VERSION ""

NS_ :

BS_:

BU_: IHU

BO_ 1538 NMm_IHU_RxMessage: 8 Vector__XXX
 SG_ NM_User_RxSignal_01 : 0|8@1- (1,0) [0|0] ""  IHU

BO_ 2015 DIAG_OBD_REQ_Broadcast: 8 Vector__XXX
 SG_ DIAG_OBD_REQ_Broadcast : 7|64@0+ (1,0) [0|0] ""  IHU

BO_ 1866 Diag_IHU_REQ: 8 Vector__XXX
 SG_ Diag_IHU_REQ : 7|64@0+ (1,0) [0|0] ""  IHU

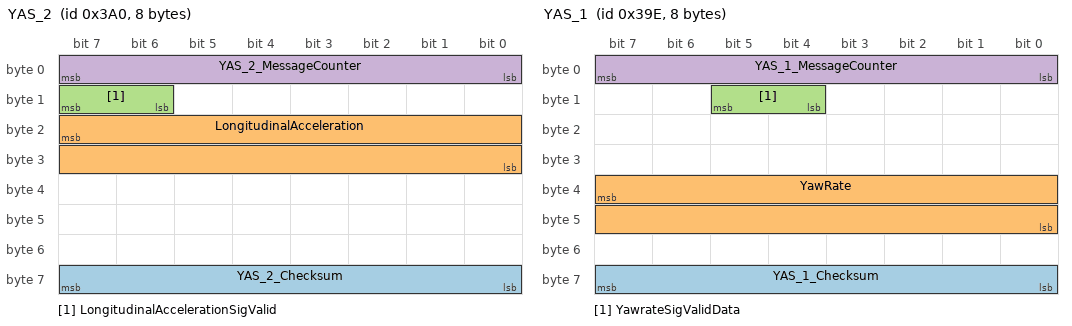
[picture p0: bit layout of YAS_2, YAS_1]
BO_ 928 YAS_2: 8 Vector__XXX
 SG_ YAS_2_Checksum : 63|8@0+ (1,0) [0|255] ""  IHU
 SG_ LongitudinalAcceleration : 23|16@0+ (0.001,-2) [-2|2] "g"  IHU
 SG_ LongitudinalAccelerationSigValid : 15|2@0+ (1,0) [0|3] ""  IHU
 SG_ YAS_2_MessageCounter : 7|8@0+ (1,0) [0|255] ""  IHU

BO_ 926 YAS_1: 8 Vector__XXX
 SG_ YAS_1_Checksum : 63|8@0+ (1,0) [0|255] ""  IHU
 SG_ YawRate : 39|16@0+ (0.01,-180) [-180|180] "deg/sec"  IHU
 SG_ YawrateSigValidData : 13|2@0+ (1,0) [0|3] ""  IHU
 SG_ YAS_1_MessageCounter : 7|8@0+ (1,0) [0|255] ""  IHU

BO_ 769 TCU_G: 4 Vector__XXX
 SG_ GBPositoionDisplay : 14|5@0+ (1,0) [0|31] ""  IHU

BO_ 1206 SHU2R_1: 8 Vector__XXX
 SG_ SHU2R_RSeatVentnSts : 5|3@0+ (1,0) [0|7] ""  IHU
 SG_ SHU2R_RSeatHeatSts : 2|3@0+ (1,0) [0|7] ""  IHU

BO_ 1202 SHU2M_1: 8 Vector__XXX
 SG_ SHU2M_MSeatVentnSts : 5|3@0+ (1,0) [0|7] ""  IHU
 SG_ SHU2M_MSeatHeatSts : 2|3@0+ (1,0) [0|7] ""  IHU

BO_ 1194 SHU2L_1: 8 Vector__XXX
 SG_ SHU2L_LSeatVentnSts : 5|3@0+ (1,0) [0|7] ""  IHU
 SG_ SHU2L_LSeatHeatSts : 2|3@0+ (1,0) [0|7] ""  IHU

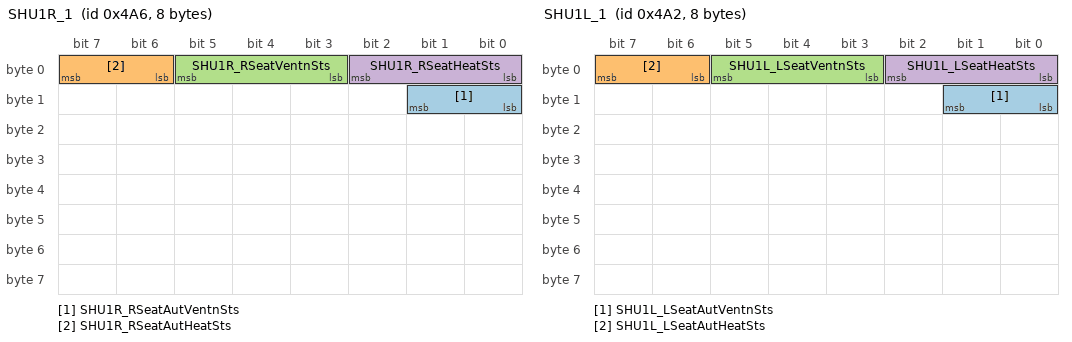
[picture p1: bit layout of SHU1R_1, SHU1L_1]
BO_ 1190 SHU1R_1: 8 Vector__XXX
 SG_ SHU1R_RSeatAutVentnSts : 9|2@0+ (1,0) [0|3] ""  IHU
 SG_ SHU1R_RSeatAutHeatSts : 7|2@0+ (1,0) [0|3] ""  IHU
 SG_ SHU1R_RSeatVentnSts : 5|3@0+ (1,0) [0|7] ""  IHU
 SG_ SHU1R_RSeatHeatSts : 2|3@0+ (1,0) [0|7] ""  IHU

BO_ 1186 SHU1L_1: 8 Vector__XXX
 SG_ SHU1L_LSeatAutVentnSts : 9|2@0+ (1,0) [0|3] ""  IHU
 SG_ SHU1L_LSeatAutHeatSts : 7|2@0+ (1,0) [0|3] ""  IHU
 SG_ SHU1L_LSeatVentnSts : 5|3@0+ (1,0) [0|7] ""  IHU
 SG_ SHU1L_LSeatHeatSts : 2|3@0+ (1,0) [0|7] ""  IHU

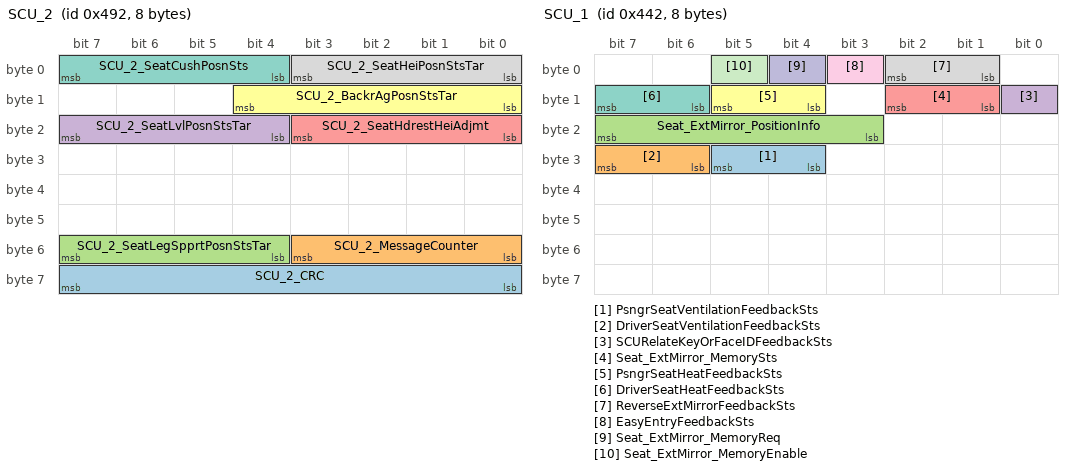
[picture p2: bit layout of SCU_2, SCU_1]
BO_ 1170 SCU_2: 8 Vector__XXX
 SG_ SCU_2_CRC : 63|8@0+ (1,0) [0|255] ""  IHU
 SG_ SCU_2_MessageCounter : 51|4@0+ (1,0) [0|15] ""  IHU
 SG_ SCU_2_SeatLegSpprtPosnStsTar : 55|4@0+ (10,0) [0|100] "%"  IHU
 SG_ SCU_2_SeatLvlPosnStsTar : 23|4@0+ (10,0) [0|100] "%"  IHU
 SG_ SCU_2_SeatHdrestHeiAdjmt : 19|4@0+ (10,0) [0|100] "%"  IHU
 SG_ SCU_2_BackrAgPosnStsTar : 12|5@0+ (5,0) [0|100] "%"  IHU
 SG_ SCU_2_SeatCushPosnSts : 7|4@0+ (10,0) [0|100] "%"  IHU
 SG_ SCU_2_SeatHeiPosnStsTar : 3|4@0+ (10,0) [0|100] "%"  IHU

BO_ 1090 SCU_1: 8 Vector__XXX
 SG_ PsngrSeatVentilationFeedbackSts : 29|2@0+ (1,0) [0|3] ""  IHU
 SG_ DriverSeatVentilationFeedbackSts : 31|2@0+ (1,0) [0|3] ""  IHU
 SG_ Seat_ExtMirror_PositionInfo : 23|5@0+ (1,0) [0|31] ""  IHU
 SG_ SCURelateKeyOrFaceIDFeedbackSts : 8|1@0+ (1,0) [0|1] ""  IHU
 SG_ Seat_ExtMirror_MemorySts : 10|2@0+ (1,0) [0|3] ""  IHU
 SG_ PsngrSeatHeatFeedbackSts : 13|2@0+ (1,0) [0|3] ""  IHU
 SG_ DriverSeatHeatFeedbackSts : 15|2@0+ (1,0) [0|3] ""  IHU
 SG_ ReverseExtMirrorFeedbackSts : 2|2@0+ (1,0) [0|3] ""  IHU
 SG_ EasyEntryFeedbackSts : 3|1@0+ (1,0) [0|1] ""  IHU
 SG_ Seat_ExtMirror_MemoryReq : 4|1@0+ (1,0) [0|1] ""  IHU
 SG_ Seat_ExtMirror_MemoryEnable : 5|1@0+ (1,0) [0|1] ""  IHU

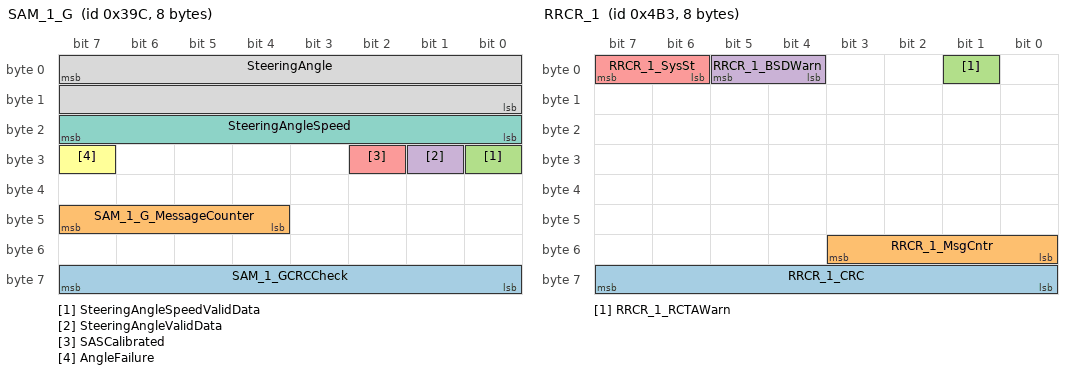
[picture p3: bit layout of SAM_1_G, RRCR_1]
BO_ 924 SAM_1_G: 8 Vector__XXX
 SG_ SAM_1_GCRCCheck : 63|8@0+ (1,0) [0|255] ""  IHU
 SG_ SAM_1_G_MessageCounter : 47|4@0+ (1,0) [0|15] ""  IHU
 SG_ SteeringAngleSpeedValidData : 24|1@0+ (1,0) [0|1] ""  IHU
 SG_ SteeringAngleValidData : 25|1@0+ (1,0) [0|1] ""  IHU
 SG_ SASCalibrated : 26|1@0+ (1,0) [0|1] ""  IHU
 SG_ AngleFailure : 31|1@0+ (1,0) [0|1] ""  IHU
 SG_ SteeringAngleSpeed : 23|8@0+ (4,0) [0|1016] "deg/Sec"  IHU
 SG_ SteeringAngle : 7|16@0+ (0.0625,-2048) [-2048|2047.875] "deg"  IHU

BO_ 1203 RRCR_1: 8 Vector__XXX
 SG_ RRCR_1_CRC : 63|8@0+ (1,0) [0|255] ""  IHU
 SG_ RRCR_1_MsgCntr : 51|4@0+ (1,0) [0|15] ""  IHU
 SG_ RRCR_1_RCTAWarn : 1|1@0+ (1,0) [0|1] ""  IHU
 SG_ RRCR_1_BSDWarn : 5|2@0+ (1,0) [0|3] ""  IHU
 SG_ RRCR_1_SysSt : 7|2@0+ (1,0) [0|3] ""  IHU

BO_ 498 RLCR_2: 8 Vector__XXX
 SG_ RLCR_2_RCTBONOFFSts : 5|2@0+ (1,0) [0|3] ""  IHU
 SG_ RLCR_2_RAEBONOFFSts : 3|2@0+ (1,0) [0|3] ""  IHU

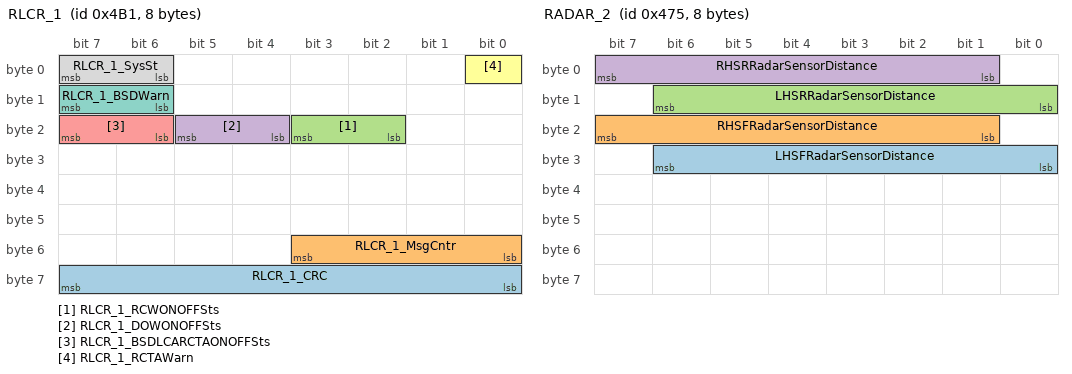
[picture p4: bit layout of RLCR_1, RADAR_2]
BO_ 1201 RLCR_1: 8 Vector__XXX
 SG_ RLCR_1_CRC : 63|8@0+ (1,0) [0|255] ""  IHU
 SG_ RLCR_1_MsgCntr : 51|4@0+ (1,0) [0|15] ""  IHU
 SG_ RLCR_1_RCWONOFFSts : 19|2@0+ (1,0) [0|3] ""  IHU
 SG_ RLCR_1_DOWONOFFSts : 21|2@0+ (1,0) [0|3] ""  IHU
 SG_ RLCR_1_BSDLCARCTAONOFFSts : 23|2@0+ (1,0) [0|3] ""  IHU
 SG_ RLCR_1_RCTAWarn : 0|1@0+ (1,0) [0|1] ""  IHU
 SG_ RLCR_1_BSDWarn : 15|2@0+ (1,0) [0|3] ""  IHU
 SG_ RLCR_1_SysSt : 7|2@0+ (1,0) [0|3] ""  IHU

BO_ 1141 RADAR_2: 8 Vector__XXX
 SG_ LHSFRadarSensorDistance : 30|7@0+ (5,30) [30|500] "cm"  IHU
 SG_ RHSFRadarSensorDistance : 23|7@0+ (5,30) [30|500] "cm"  IHU
 SG_ LHSRRadarSensorDistance : 14|7@0+ (5,30) [30|500] "cm"  IHU
 SG_ RHSRRadarSensorDistance : 7|7@0+ (5,30) [30|500] "cm"  IHU

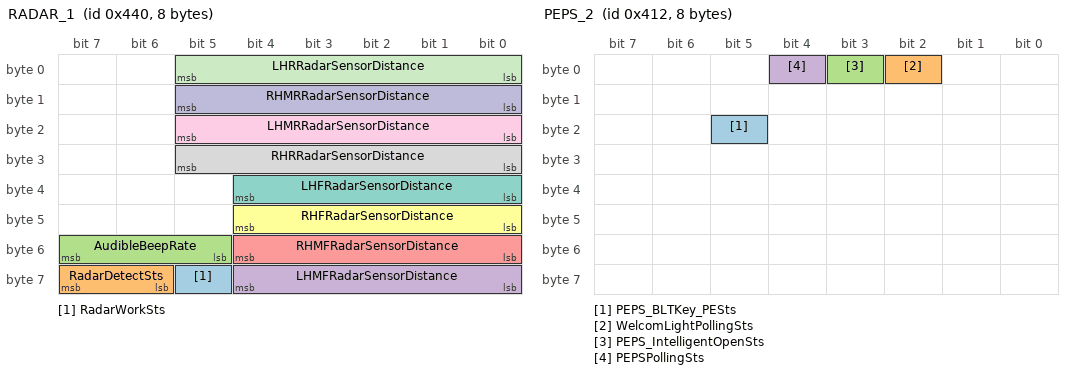
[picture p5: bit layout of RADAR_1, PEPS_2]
BO_ 1088 RADAR_1: 8 Vector__XXX
 SG_ RadarWorkSts : 61|1@0+ (1,0) [0|1] ""  IHU
 SG_ RadarDetectSts : 63|2@0+ (1,0) [0|3] ""  IHU
 SG_ AudibleBeepRate : 55|3@0+ (1,0) [0|7] ""  IHU
 SG_ LHMFRadarSensorDistance : 60|5@0+ (5,25) [25|160] "cm"  IHU
 SG_ RHMFRadarSensorDistance : 52|5@0+ (5,25) [25|160] "cm"  IHU
 SG_ RHFRadarSensorDistance : 44|5@0+ (5,25) [25|160] "cm"  IHU
 SG_ LHFRadarSensorDistance : 36|5@0+ (5,25) [25|160] "cm"  IHU
 SG_ RHRRadarSensorDistance : 29|6@0+ (5,25) [25|180] "cm"  IHU
 SG_ LHMRRadarSensorDistance : 21|6@0+ (5,25) [25|180] "cm"  IHU
 SG_ RHMRRadarSensorDistance : 13|6@0+ (5,25) [25|180] "cm"  IHU
 SG_ LHRRadarSensorDistance : 5|6@0+ (5,25) [25|180] "cm"  IHU

BO_ 1078 PLG_1: 8 Vector__XXX
 SG_ PLG_OperateSts : 21|3@0+ (1,0) [0|7] ""  IHU
 SG_ PLG_Set_MaxPosition : 15|8@0+ (1,0) [0|100] "%"  IHU

BO_ 1042 PEPS_2: 8 Vector__XXX
 SG_ PEPS_BLTKey_PESts : 21|1@0+ (1,0) [0|1] ""  IHU
 SG_ WelcomLightPollingSts : 2|1@0+ (1,0) [0|1] ""  IHU
 SG_ PEPS_IntelligentOpenSts : 3|1@0+ (1,0) [0|1] ""  IHU
 SG_ PEPSPollingSts : 4|1@0+ (1,0) [0|1] ""  IHU

BO_ 998 PEPS_1: 8 Vector__XXX
 SG_ RemoteStartSts : 42|2@0+ (1,0) [0|3] ""  IHU
 SG_ Start_StopRequest : 45|3@0+ (1,0) [0|7] ""  IHU
 SG_ IDInformation : 34|3@0+ (1,0) [0|7] ""  IHU

BO_ 1124 NFC_1: 8 Vector__XXX
 SG_ NFC_1_DispCardPosn : 15|1@0+ (1,0) [0|1] ""  IHU
 SG_ NFC_1_IDList : 7|3@0+ (1,0) [0|7] ""  IHU
 SG_ NFC_1_ID : 4|3@0+ (1,0) [0|7] ""  IHU

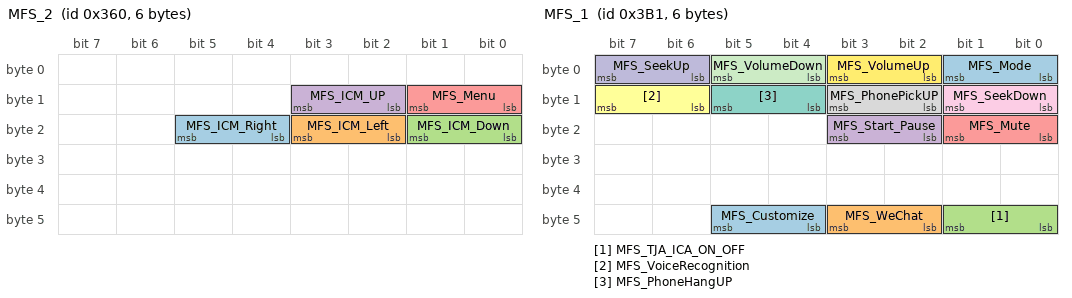
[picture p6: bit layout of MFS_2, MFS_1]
BO_ 864 MFS_2: 6 Vector__XXX
 SG_ MFS_ICM_Right : 21|2@0+ (1,0) [0|3] ""  IHU
 SG_ MFS_ICM_Left : 19|2@0+ (1,0) [0|3] ""  IHU
 SG_ MFS_ICM_Down : 17|2@0+ (1,0) [0|3] ""  IHU
 SG_ MFS_ICM_UP : 11|2@0+ (1,0) [0|3] ""  IHU
 SG_ MFS_Menu : 9|2@0+ (1,0) [0|3] ""  IHU

BO_ 945 MFS_1: 6 Vector__XXX
 SG_ MFS_Customize : 45|2@0+ (1,0) [0|3] ""  IHU
 SG_ MFS_WeChat : 43|2@0+ (1,0) [0|3] ""  IHU
 SG_ MFS_TJA_ICA_ON_OFF : 41|2@0+ (1,0) [0|3] ""  IHU
 SG_ MFS_Start_Pause : 19|2@0+ (1,0) [0|3] ""  IHU
 SG_ MFS_Mute : 17|2@0+ (1,0) [0|3] ""  IHU
 SG_ MFS_VoiceRecognition : 15|2@0+ (1,0) [0|3] ""  IHU
 SG_ MFS_PhoneHangUP : 13|2@0+ (1,0) [0|3] ""  IHU
 SG_ MFS_PhonePickUP : 11|2@0+ (1,0) [0|3] ""  IHU
 SG_ MFS_SeekDown : 9|2@0+ (1,0) [0|3] ""  IHU
 SG_ MFS_SeekUp : 7|2@0+ (1,0) [0|3] ""  IHU
 SG_ MFS_VolumeDown : 5|2@0+ (1,0) [0|3] ""  IHU
 SG_ MFS_VolumeUp : 3|2@0+ (1,0) [0|3] ""  IHU
 SG_ MFS_Mode : 1|2@0+ (1,0) [0|3] ""  IHU

BO_ 1218 LHM_1: 8 Vector__XXX
 SG_ LHM_1_ADBenable_Feedback : 0|1@0+ (1,0) [0|1] ""  IHU
 SG_ LHM_1_ADBSts : 2|2@0+ (1,0) [0|3] ""  IHU

BO_ 1059 LDW_1: 8 Vector__XXX
 SG_ LDWSensitivitySettingFeedback : 6|2@0+ (1,0) [0|3] ""  IHU
 SG_ LDWSwitchStsFeedback : 7|1@0+ (1,0) [0|1] ""  IHU

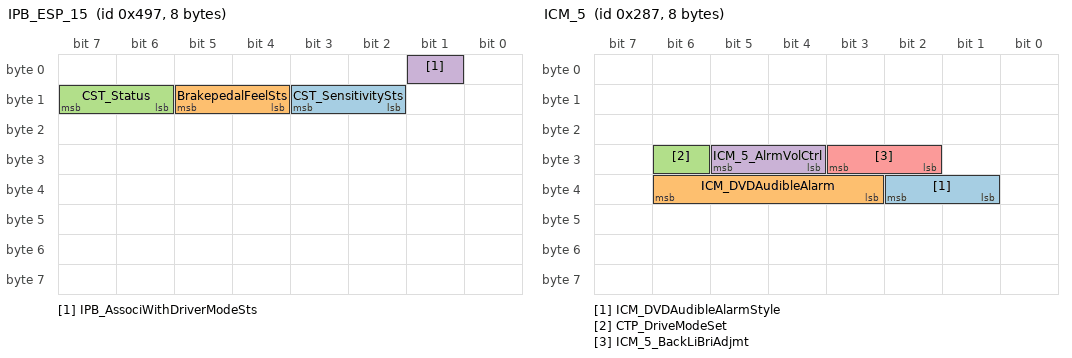
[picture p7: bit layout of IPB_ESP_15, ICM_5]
BO_ 1175 IPB_ESP_15: 8 Vector__XXX
 SG_ CST_SensitivitySts : 11|2@0+ (1,0) [0|3] ""  IHU
 SG_ BrakepedalFeelSts : 13|2@0+ (1,0) [0|3] ""  IHU
 SG_ CST_Status : 15|2@0+ (1,0) [0|3] ""  IHU
 SG_ IPB_AssociWithDriverModeSts : 1|1@0+ (1,0) [0|1] ""  IHU

BO_ 1149 IMMO_12: 8 Vector__XXX
 SG_ IMMO_Teach : 7|64@0+ (1,0) [0|0] ""  IHU

BO_ 1110 IMMO_11: 8 Vector__XXX
 SG_ IMMO_Chall : 7|64@0+ (1,0) [0|0] ""  IHU

BO_ 1508 ICM_IHU_Interaction: 8 Vector__XXX
 SG_ ICM_4_InteractiveDisplayInfo : 7|64@0+ (1,0) [0|0] ""  IHU

BO_ 906 IDCU_12: 8 Vector__XXX
 SG_ IDCU_12CPMod : 15|4@0+ (1,0) [0|15] ""  IHU
 SG_ IDCU_12Rmninfo : 7|7@0+ (1,0) [0|127] ""  IHU

BO_ 1248 IDCU_11: 8 Vector__XXX
 SG_ IDCU_11_DrvAssiStylests : 8|2@0+ (1,0) [0|3] ""  IHU
 SG_ IDCU_11_DCLCONOFFsts : 10|2@0+ (1,0) [0|3] ""  IHU

BO_ 533 ICM_8: 8 Vector__XXX
 SG_ ICM_8_FrntRadarSwt : 15|1@0+ (1,0) [0|1] ""  IHU
 SG_ ICM_ESPSwitchCmd : 0|1@0+ (1,0) [0|1] ""  IHU

BO_ 647 ICM_5: 8 Vector__XXX
 SG_ ICM_DVDAudibleAlarmStyle : 34|2@0+ (1,0) [0|3] ""  IHU
 SG_ ICM_DVDAudibleAlarm : 38|4@0+ (1,0) [0|15] ""  IHU
 SG_ CTP_DriveModeSet : 30|1@0+ (1,0) [0|3] ""  IHU
 SG_ ICM_5_AlrmVolCtrl : 29|2@0+ (1,0) [0|3] ""  IHU
 SG_ ICM_5_BackLiBriAdjmt : 27|2@0+ (1,0) [0|3] ""  IHU

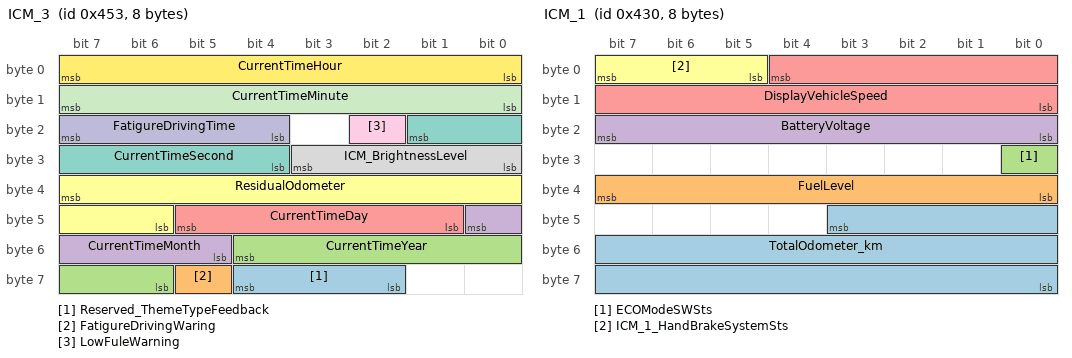
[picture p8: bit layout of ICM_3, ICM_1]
BO_ 1107 ICM_3: 8 Vector__XXX
 SG_ Reserved_ThemeTypeFeedback : 60|3@0+ (1,0) [0|0] ""  IHU
 SG_ FatigureDrivingWaring : 61|1@0+ (1,0) [0|1] ""  IHU
 SG_ CurrentTimeYear : 52|7@0+ (1,2000) [2000|2127] ""  IHU
 SG_ CurrentTimeMonth : 40|4@0+ (1,0) [1|12] ""  IHU
 SG_ CurrentTimeDay : 45|5@0+ (1,0) [1|31] ""  IHU
 SG_ ResidualOdometer : 39|10@0+ (1,0) [0|999] "km"  IHU
 SG_ CurrentTimeSecond : 17|6@0+ (1,0) [0|59] ""  IHU
 SG_ ICM_BrightnessLevel : 27|4@0+ (1,0) [0|15] ""  IHU
 SG_ LowFuleWarning : 18|1@0+ (1,0) [0|1] ""  IHU
 SG_ FatigureDrivingTime : 23|4@0+ (1,0) [0|15] ""  IHU
 SG_ CurrentTimeMinute : 15|8@0+ (1,0) [0|59] ""  IHU
 SG_ CurrentTimeHour : 7|8@0+ (1,0) [0|23] ""  IHU

BO_ 1106 ICM_2: 4 Vector__XXX
 SG_ ICM_2_OverSpeedValue : 31|6@0+ (1,0) [0|63] ""  IHU
 SG_ BackLightLevel : 23|4@0+ (1,0) [0|15] ""  IHU
 SG_ AverageFuelConsumption : 7|8@0+ (0.1,0) [0|25.4] "L/100km"  IHU

BO_ 1072 ICM_1: 8 Vector__XXX
 SG_ TotalOdometer_km : 43|20@0+ (1,0) [0|999999] "km"  IHU
 SG_ FuelLevel : 39|8@0+ (1,0) [0|100] "%"  IHU
 SG_ ECOModeSWSts : 24|1@0+ (1,0) [0|1] ""  IHU
 SG_ BatteryVoltage : 23|8@0+ (0.1,0) [0|25.4] "V"  IHU
 SG_ DisplayVehicleSpeed : 4|13@0+ (0.0625,0) [0|511.875] "km/h"  IHU
 SG_ ICM_1_HandBrakeSystemSts : 7|3@0+ (1,0) [0|7] ""  IHU

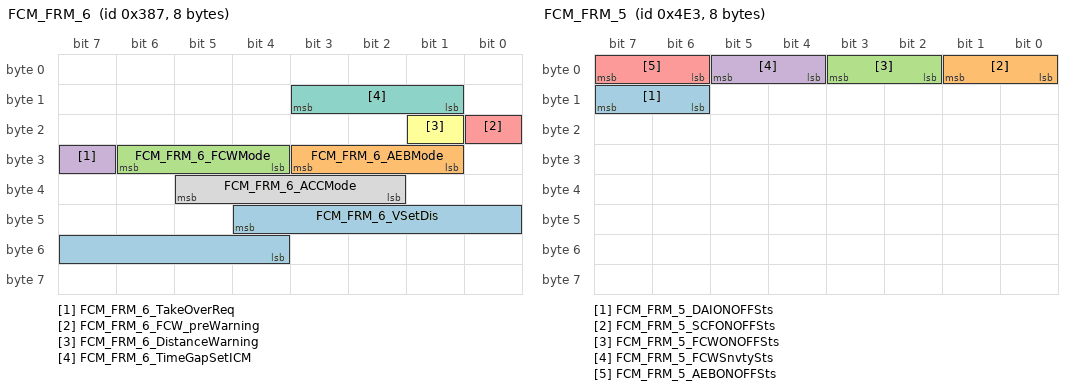
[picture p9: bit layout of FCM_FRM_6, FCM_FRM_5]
BO_ 903 FCM_FRM_6: 8 Vector__XXX
 SG_ FCM_FRM_6_VSetDis : 44|9@0+ (0.5,0) [0|255.5] "KPH"  IHU
 SG_ FCM_FRM_6_AEBMode : 27|3@0+ (1,0) [0|4] ""  IHU
 SG_ FCM_FRM_6_FCWMode : 30|3@0+ (1,0) [0|4] ""  IHU
 SG_ FCM_FRM_6_TakeOverReq : 31|1@0+ (1,0) [0|1] ""  IHU
 SG_ FCM_FRM_6_FCW_preWarning : 16|1@0+ (1,0) [0|1] ""  IHU
 SG_ FCM_FRM_6_DistanceWarning : 17|1@0+ (1,0) [0|1] ""  IHU
 SG_ FCM_FRM_6_TimeGapSetICM : 11|3@0+ (1,0) [0|7] ""  IHU
 SG_ FCM_FRM_6_ACCMode : 37|4@0+ (1,0) [0|15] ""  IHU

BO_ 1251 FCM_FRM_5: 8 Vector__XXX
 SG_ FCM_FRM_5_DAIONOFFSts : 15|2@0+ (1,0) [0|3] ""  IHU
 SG_ FCM_FRM_5_SCFONOFFSts : 1|2@0+ (1,0) [0|3] ""  IHU
 SG_ FCM_FRM_5_FCWONOFFSts : 3|2@0+ (1,0) [0|3] ""  IHU
 SG_ FCM_FRM_5_FCWSnvtySts : 5|2@0+ (1,0) [0|3] ""  IHU
 SG_ FCM_FRM_5_AEBONOFFSts : 7|2@0+ (1,0) [0|3] ""  IHU

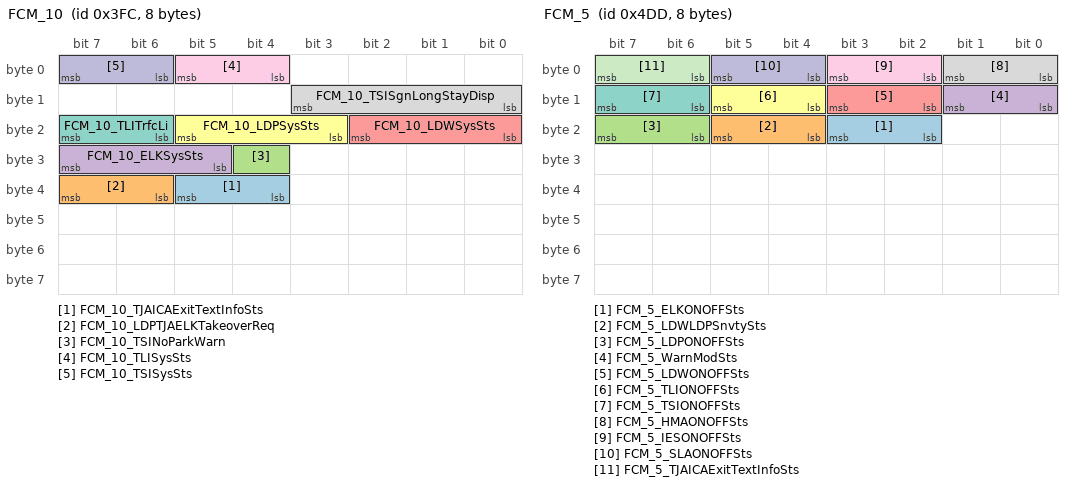
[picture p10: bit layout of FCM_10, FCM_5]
BO_ 1020 FCM_10: 8 Vector__XXX
 SG_ FCM_10_TJAICAExitTextInfoSts : 37|2@0+ (1,0) [0|3] ""  IHU
 SG_ FCM_10_LDPTJAELKTakeoverReq : 39|2@0+ (1,0) [0|3] ""  IHU
 SG_ FCM_10_TSINoParkWarn : 28|1@0+ (1,0) [0|1] ""  IHU
 SG_ FCM_10_ELKSysSts : 31|3@0+ (1,0) [0|7] ""  IHU
 SG_ FCM_10_LDWSysSts : 18|3@0+ (1,0) [0|7] ""  IHU
 SG_ FCM_10_LDPSysSts : 21|3@0+ (1,0) [0|7] ""  IHU
 SG_ FCM_10_TLITrfcLi : 23|2@0+ (1,0) [0|3] ""  IHU
 SG_ FCM_10_TSISgnLongStayDisp : 11|4@0+ (1,0) [0|15] ""  IHU
 SG_ FCM_10_TLISysSts : 5|2@0+ (1,0) [0|3] ""  IHU
 SG_ FCM_10_TSISysSts : 7|2@0+ (1,0) [0|3] ""  IHU

BO_ 1245 FCM_5: 8 Vector__XXX
 SG_ FCM_5_ELKONOFFSts : 19|2@0+ (1,0) [0|3] ""  IHU
 SG_ FCM_5_LDWLDPSnvtySts : 21|2@0+ (1,0) [0|3] ""  IHU
 SG_ FCM_5_LDPONOFFSts : 23|2@0+ (1,0) [0|3] ""  IHU
 SG_ FCM_5_WarnModSts : 9|2@0+ (1,0) [0|3] ""  IHU
 SG_ FCM_5_LDWONOFFSts : 11|2@0+ (1,0) [0|3] ""  IHU
 SG_ FCM_5_TLIONOFFSts : 13|2@0+ (1,0) [0|3] ""  IHU
 SG_ FCM_5_TSIONOFFSts : 15|2@0+ (1,0) [0|3] ""  IHU
 SG_ FCM_5_HMAONOFFSts : 1|2@0+ (1,0) [0|3] ""  IHU
 SG_ FCM_5_IESONOFFSts : 3|2@0+ (1,0) [0|3] ""  IHU
 SG_ FCM_5_SLAONOFFSts : 5|2@0+ (1,0) [0|3] ""  IHU
 SG_ FCM_5_TJAICAExitTextInfoSts : 7|2@0+ (1,0) [0|3] ""  IHU

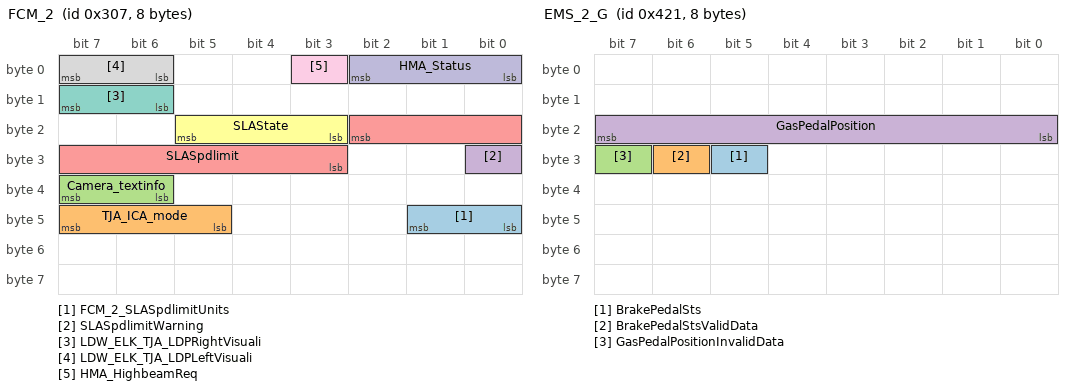
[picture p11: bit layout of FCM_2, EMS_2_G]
BO_ 775 FCM_2: 8 Vector__XXX
 SG_ FCM_2_SLASpdlimitUnits : 41|2@0+ (1,0) [0|3] ""  IHU
 SG_ TJA_ICA_mode : 47|3@0+ (1,0) [0|4] ""  IHU
 SG_ Camera_textinfo : 39|2@0+ (1,0) [0|3] ""  IHU
 SG_ SLASpdlimitWarning : 24|1@0+ (1,0) [0|1] ""  IHU
 SG_ SLASpdlimit : 18|8@0+ (1,0) [0|255] ""  IHU
 SG_ SLAState : 21|3@0+ (1,0) [0|7] ""  IHU
 SG_ LDW_ELK_TJA_LDPRightVisuali : 15|2@0+ (1,0) [0|3] ""  IHU
 SG_ LDW_ELK_TJA_LDPLeftVisuali : 7|2@0+ (1,0) [0|3] ""  IHU
 SG_ HMA_HighbeamReq : 3|1@0+ (1,0) [0|1] ""  IHU
 SG_ HMA_Status : 2|3@0+ (1,0) [0|7] ""  IHU

BO_ 896 EPS_1: 3 Vector__XXX
 SG_ EPS_AssociWithDriverModeSts : 11|1@0+ (1,0) [0|1] ""  IHU
 SG_ EPS_AssistanceStyle_Sts : 6|2@0+ (1,0) [0|3] ""  IHU

BO_ 1240 EMS_3_G: 8 Vector__XXX
 SG_ EMS_BoostP : 39|16@0+ (0.078125,0) [0|5119] "hPa"  IHU

BO_ 1057 EMS_2_G: 8 Vector__XXX
 SG_ BrakePedalSts : 29|1@0+ (1,0) [0|1] ""  IHU
 SG_ BrakePedalStsValidData : 30|1@0+ (1,0) [0|1] ""  IHU
 SG_ GasPedalPositionInvalidData : 31|1@0+ (1,0) [0|1] ""  IHU
 SG_ GasPedalPosition : 23|8@0+ (0.392,0) [0|99.568] "%"  IHU

BO_ 640 EMS_1_G: 8 Vector__XXX
 SG_ EngineSts : 58|1@0+ (1,0) [0|1] ""  IHU
 SG_ SSMStatus : 52|3@0+ (1,0) [0|7] ""  IHU
 SG_ EngineSpeed : 39|11@0+ (4,0) [0|8000] "rpm"  IHU

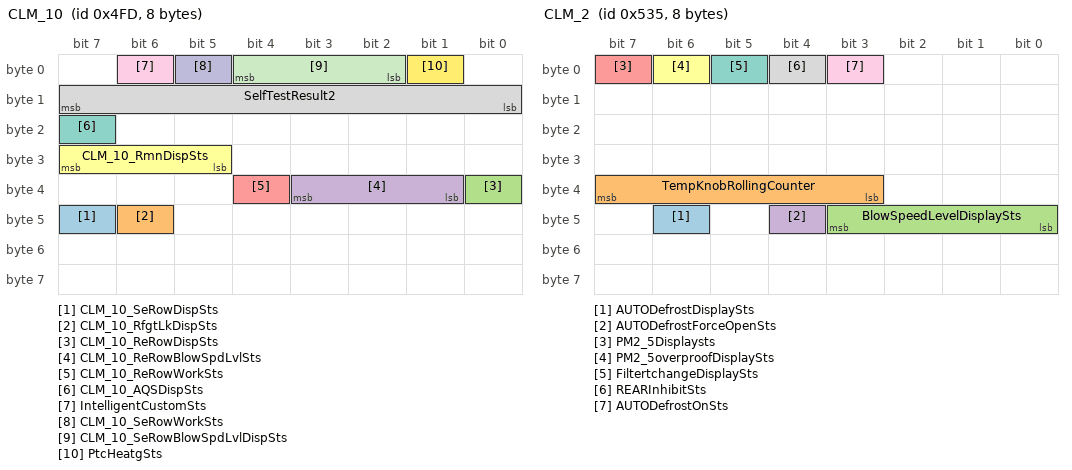
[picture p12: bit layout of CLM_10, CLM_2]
BO_ 1277 CLM_10: 8 Vector__XXX
 SG_ CLM_10_SeRowDispSts : 47|1@0+ (1,0) [0|1] ""  IHU
 SG_ CLM_10_RfgtLkDispSts : 46|1@0+ (1,0) [0|1] ""  IHU
 SG_ CLM_10_ReRowDispSts : 32|1@0+ (1,0) [0|1] ""  IHU
 SG_ CLM_10_ReRowBlowSpdLvlSts : 35|3@0+ (1,0) [0|7] ""  IHU
 SG_ CLM_10_ReRowWorkSts : 36|1@0+ (1,0) [0|1] ""  IHU
 SG_ CLM_10_RmnDispSts : 31|3@0+ (1,0) [0|7] ""  IHU
 SG_ CLM_10_AQSDispSts : 23|1@0+ (1,0) [0|1] ""  IHU
 SG_ SelfTestResult2 : 15|8@0+ (1,0) [0|255] ""  IHU
 SG_ IntelligentCustomSts : 6|1@0+ (1,0) [0|1] ""  IHU
 SG_ CLM_10_SeRowWorkSts : 5|1@0+ (1,0) [0|1] ""  IHU
 SG_ CLM_10_SeRowBlowSpdLvlDispSts : 4|3@0+ (1,0) [0|7] ""  IHU
 SG_ PtcHeatgSts : 1|1@0+ (1,0) [0|1] ""  IHU

BO_ 1334 CLM_3: 8 Vector__XXX
 SG_ FragranCeconsistenceLevelSts : 58|3@0+ (1,0) [0|7] ""  IHU
 SG_ Pos3_FragranceTypesSts : 49|3@0+ (1,0) [0|7] ""  IHU
 SG_ Pos2_FragranceTypesSts : 62|3@0+ (1,0) [0|7] ""  IHU
 SG_ PM2_5AutoRunSetSts : 59|1@0+ (1,0) [0|1] ""  IHU
 SG_ PM2_5_Incar_Level : 52|3@0+ (1,0) [0|7] ""  IHU
 SG_ PM2_5_Outcar_Level : 55|3@0+ (1,0) [0|7] ""  IHU
 SG_ FragranceDisplaysts : 40|1@0+ (1,0) [0|1] ""  IHU
 SG_ FragrancePositionSwt : 24|2@0+ (1,0) [0|3] ""  IHU
 SG_ ACModeCustomSts : 42|2@0+ (1,0) [0|3] ""  IHU
 SG_ FragranceWelcomeModeSts : 44|1@0+ (1,0) [0|1] ""  IHU
 SG_ RefreshFunctionSts : 43|1@0+ (1,0) [0|1] ""  IHU
 SG_ Pos1_FragranceTypesSts : 47|3@0+ (1,0) [0|7] ""  IHU
 SG_ PM2_5AutoRunSts : 33|1@0+ (1,0) [0|1] ""  IHU
 SG_ FragranceSWSts : 36|2@0+ (1,0) [0|3] ""  IHU
 SG_ AutoBltCalllowBlowSpeedSts : 37|1@0+ (1,0) [0|1] ""  IHU
 SG_ AutoParkInnerCirculationSts : 38|1@0+ (1,0) [0|1] ""  IHU
 SG_ PM2_5_IncarSts : 26|1@0+ (1,0) [0|1] ""  IHU
 SG_ PM2_5_ExtSts : 27|1@0+ (1,0) [0|1] ""  IHU
 SG_ PM2_5_ext : 23|10@0+ (1,0) [0|1000] "ug/m3"  IHU
 SG_ FragranceShortageWarning : 6|3@0+ (1,0) [0|7] ""  IHU
 SG_ ION_Function_Sts : 3|2@0+ (1,0) [0|3] ""  IHU
 SG_ PM2_5_incar : 1|10@0+ (1,0) [0|1000] "ug/m3"  IHU

BO_ 1333 CLM_2: 8 Vector__XXX
 SG_ AUTODefrostDisplaySts : 46|1@0+ (1,0) [0|1] ""  IHU
 SG_ TempKnobRollingCounter : 39|5@0+ (1,0) [0|31] ""  IHU
 SG_ BlowSpeedLevelDisplaySts : 43|4@0+ (1,0) [0|15] ""  IHU
 SG_ AUTODefrostForceOpenSts : 44|1@0+ (1,0) [0|1] ""  IHU
 SG_ PM2_5Displaysts : 7|1@0+ (1,0) [0|1] ""  IHU
 SG_ PM2_5overproofDisplaySts : 6|1@0+ (1,0) [0|1] ""  IHU
 SG_ FiltertchangeDisplaySts : 5|1@0+ (1,0) [0|1] ""  IHU
 SG_ REARInhibitSts : 4|1@0+ (1,0) [0|1] ""  IHU
 SG_ AUTODefrostOnSts : 3|1@0+ (1,0) [0|1] ""  IHU

BO_ 1306 CLM_1: 8 Vector__XXX
 SG_ SetTemperature_R_F : 61|5@0+ (2,58) [58|90] "℉"  IHU
 SG_ SetTemperature_L_F : 50|5@0+ (2,58) [58|90] "℉"  IHU
 SG_ SelfTestResult : 55|5@0+ (1,0) [0|31] ""  IHU
 SG_ TemperatureUnit : 40|1@0+ (1,0) [0|1] ""  IHU
 SG_ ZoneSelectionDisplaySts : 41|1@0+ (1,0) [0|1] ""  IHU
 SG_ CirculationModeDisplaySts : 42|1@0+ (1,0) [0|1] ""  IHU
 SG_ SetTemperature_R_C : 47|5@0+ (1,15) [15|31] "℃"  IHU
 SG_ SetTemperature_L_C : 39|5@0+ (1,15) [15|31] "℃"  IHU
 SG_ BlowDelayOffSts : 34|1@0+ (1,0) [0|1] ""  IHU
 SG_ BlowAdvanceOnSts : 33|1@0+ (1,0) [0|1] ""  IHU
 SG_ DisplayActive : 32|1@0+ (1,0) [0|1] ""  IHU
 SG_ SelfTestActive : 27|1@0+ (1,0) [0|1] ""  IHU
 SG_ PM2_5Sts : 26|1@0+ (1,0) [0|1] ""  IHU
 SG_ WorkingSts : 25|1@0+ (1,0) [0|1] ""  IHU
 SG_ ModeAdjustDisplaySts : 30|3@0+ (1,0) [0|7] ""  IHU
 SG_ FrontDeforest_MaxDisplaySts : 31|1@0+ (1,0) [0|1] ""  IHU
 SG_ ACRequestDisplaySts : 19|1@0+ (1,0) [0|1] ""  IHU
 SG_ AutoDisplaySts : 20|1@0+ (1,0) [0|1] ""  IHU
 SG_ Reserved_AC_MaxSts : 22|1@0+ (1,0) [0|1] ""  IHU
 SG_ ExternalTemperatureFailSts : 23|1@0+ (1,0) [0|1] ""  IHU
 SG_ ExternalTemperature_C : 15|8@0+ (0.5,-55) [-55|70] "°C"  IHU
 SG_ ExternalTemperature_F : 7|8@0+ (1,-67) [-67|158] "°F"  IHU

BO_ 1104 CGW_1: 8 Vector__XXX
 SG_ OBDDiagnosisReqInd : 7|1@0+ (1,0) [0|1] ""  IHU

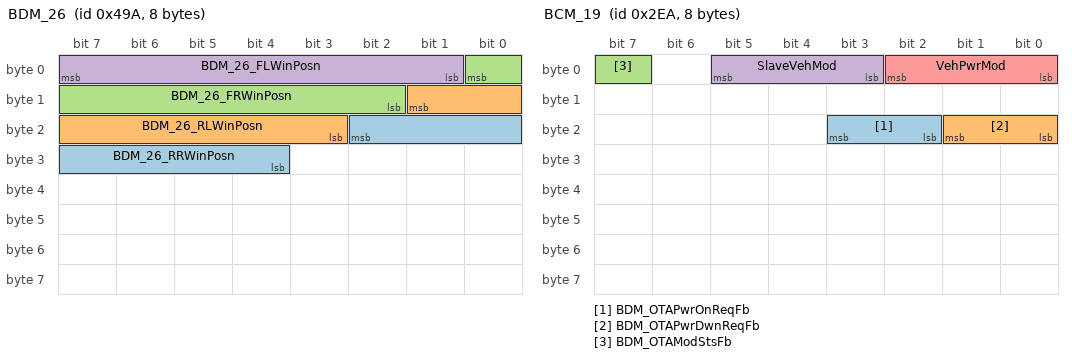
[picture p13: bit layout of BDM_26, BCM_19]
BO_ 1178 BDM_26: 8 Vector__XXX
 SG_ BDM_26_RRWinPosn : 18|7@0+ (1,0) [0|100] "%"  IHU
 SG_ BDM_26_RLWinPosn : 9|7@0+ (1,0) [0|100] "%"  IHU
 SG_ BDM_26_FRWinPosn : 0|7@0+ (1,0) [0|100] "%"  IHU
 SG_ BDM_26_FLWinPosn : 7|7@0+ (1,0) [0|100] "%"  IHU

BO_ 1007 BDM_25: 8 Vector__XXX
 SG_ BDM_25_AmbBrightness : 23|12@0+ (20,0) [0|81880] "Lux"  IHU
 SG_ BDM_25_FWBrightness : 1|10@0+ (6,0) [0|6126] "Lux"  IHU

BO_ 1287 BCM_22: 8 Vector__XXX
 SG_ BCM_22_WiprSnvtySetFb : 34|3@0+ (1,0) [0|7] ""  IHU
 SG_ PassSeatMsgStr_LvlSts : 20|2@0+ (1,0) [0|3] ""  IHU
 SG_ PassSeatMsg_ModeSts : 18|3@0+ (1,0) [0|7] ""  IHU

BO_ 746 BCM_19: 8 Vector__XXX
 SG_ BDM_OTAPwrOnReqFb : 19|2@0+ (1,0) [0|3] ""  IHU
 SG_ BDM_OTAPwrDwnReqFb : 17|2@0+ (1,0) [0|3] ""  IHU
 SG_ BDM_OTAModStsFb : 7|1@0+ (1,0) [0|1] ""  IHU
 SG_ SlaveVehMod : 5|3@0+ (1,0) [0|7] ""  IHU
 SG_ VehPwrMod : 2|3@0+ (1,0) [0|7] ""  IHU

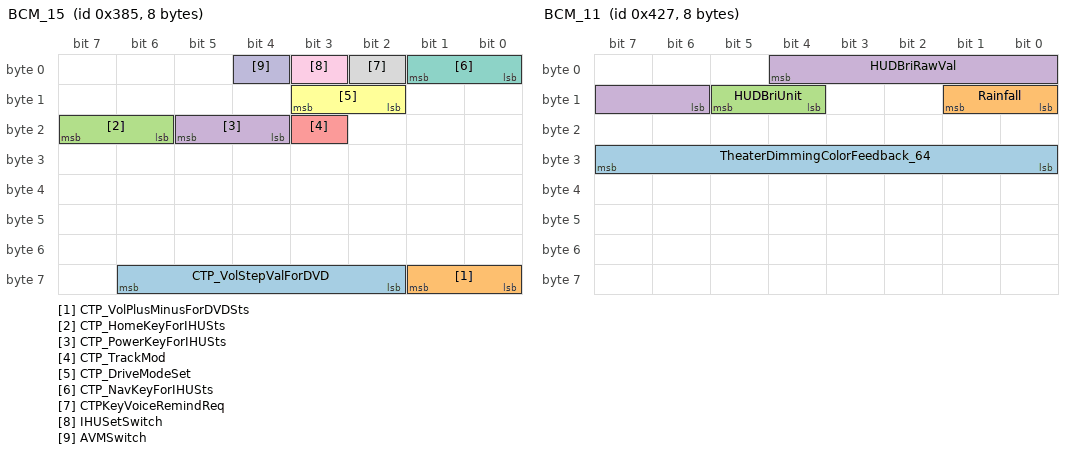
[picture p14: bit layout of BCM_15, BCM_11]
BO_ 901 BCM_15: 8 Vector__XXX
 SG_ CTP_VolStepValForDVD : 62|5@0+ (1,0) [0|31] "Grid"  IHU
 SG_ CTP_VolPlusMinusForDVDSts : 57|2@0+ (1,0) [0|3] ""  IHU
 SG_ CTP_HomeKeyForIHUSts : 23|2@0+ (1,0) [0|3] ""  IHU
 SG_ CTP_PowerKeyForIHUSts : 21|2@0+ (1,0) [0|3] ""  IHU
 SG_ CTP_TrackMod : 19|1@0+ (1,0) [0|1] ""  IHU
 SG_ CTP_DriveModeSet : 11|2@0+ (1,0) [0|3] ""  IHU
 SG_ CTP_NavKeyForIHUSts : 1|2@0+ (1,0) [0|3] ""  IHU
 SG_ CTPKeyVoiceRemindReq : 2|1@0+ (1,0) [0|1] ""  IHU
 SG_ IHUSetSwitch : 3|1@0+ (1,0) [0|1] ""  IHU
 SG_ AVMSwitch : 4|1@0+ (1,0) [0|1] ""  IHU

BO_ 936 BCM_13: 8 Vector__XXX
 SG_ IBS_SOH : 55|8@0+ (1,0) [0|255] "%"  IHU
 SG_ IBS_SOC : 23|8@0+ (1,0) [0|255] "%"  IHU

BO_ 934 BCM_12: 8 Vector__XXX
 SG_ IBS_Current : 39|16@0+ (1,0) [0|0] "A"  IHU
 SG_ IBS_Voltage : 21|14@0+ (0.000976563,3) [3|18] "V"  IHU

BO_ 1063 BCM_11: 8 Vector__XXX
 SG_ TheaterDimmingColorFeedback_64 : 31|8@0+ (1,0) [0|255] ""  IHU
 SG_ Rainfall : 9|2@0+ (1,0) [0|3] ""  IHU
 SG_ HUDBriUnit : 13|2@0+ (1,0) [0|3] ""  IHU
 SG_ HUDBriRawVal : 4|7@0+ (1,0) [0|126] ""  IHU

BO_ 1077 BCM_9: 8 Vector__XXX
 SG_ RvsExtMirrFbSts : 57|2@0+ (1,0) [0|3] ""  IHU
 SG_ Reserved_RainingWarning : 49|1@0+ (1,0) [0|0] ""  IHU
 SG_ SRF_Hall2SensorError : 47|1@0+ (1,0) [0|1] ""  IHU
 SG_ SRF_Hall1SensorError : 46|1@0+ (1,0) [0|1] ""  IHU
 SG_ SRF_SunroofOverVolt : 45|1@0+ (1,0) [0|1] ""  IHU
 SG_ SRF_SunroofUnderVolt : 44|1@0+ (1,0) [0|1] ""  IHU
 SG_ SRF_LINCommunicationERROR : 43|1@0+ (1,0) [0|1] ""  IHU
 SG_ SRF_SwitchError : 42|1@0+ (1,0) [0|1] ""  IHU
 SG_ SRF_OverHeatProtect : 41|1@0+ (1,0) [0|1] ""  IHU
 SG_ SRF_MotorRelayError : 40|1@0+ (1,0) [0|1] ""  IHU
 SG_ AssociatedWithDriverModeFeedback : 32|1@0+ (1,0) [0|1] ""  IHU
 SG_ TheaterDimmingBrightnessFeedback : 35|3@0+ (1,0) [0|7] ""  IHU
 SG_ TheaterDimmingColorFeedback : 38|3@0+ (1,0) [0|7] ""  IHU
 SG_ SRF_Sunshade_OperateSts : 25|3@0+ (1,0) [0|7] ""  IHU
 SG_ RRWindowSts : 28|3@0+ (1,0) [0|7] ""  IHU
 SG_ RLWindowSts : 31|3@0+ (1,0) [0|7] ""  IHU
 SG_ WindowInhibitSts : 17|1@0+ (1,0) [0|1] ""  IHU
 SG_ FRWindow_Sts : 20|3@0+ (1,0) [0|7] ""  IHU
 SG_ FLWindow_Sts : 23|3@0+ (1,0) [0|7] ""  IHU
 SG_ Window_OperateSts : 11|2@0+ (1,0) [0|3] ""  IHU
 SG_ Reserved_SRF_Error : 15|4@0+ (1,0) [0|15] ""  IHU
 SG_ SRF_InitStatus : 7|1@0+ (1,0) [0|1] ""  IHU
 SG_ AssociatedWithMusicModeFeedback : 9|1@0+ (1,0) [0|1] ""  IHU
 SG_ TheaterDimmingStatusFeedback : 8|1@0+ (1,0) [0|1] ""  IHU
 SG_ SRF_PositionSts : 6|4@0+ (1,0) [0|15] ""  IHU
 SG_ SRF_OperateSts : 2|3@0+ (1,0) [0|7] ""  IHU

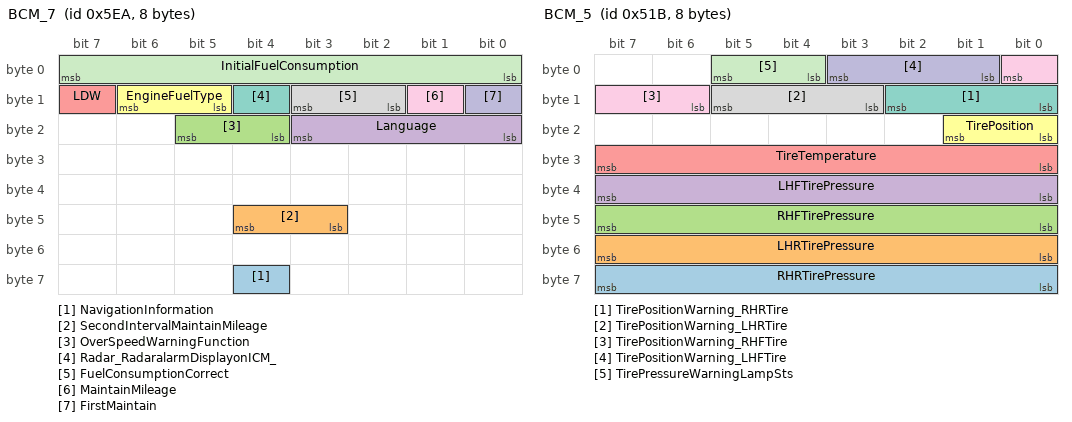
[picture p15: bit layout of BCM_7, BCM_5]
BO_ 1514 BCM_7: 8 Vector__XXX
 SG_ NavigationInformation : 60|1@0+ (1,0) [0|1] ""  IHU
 SG_ SecondIntervalMaintainMileage : 44|2@0+ (1,0) [0|3] ""  IHU
 SG_ OverSpeedWarningFunction : 21|2@0+ (1,0) [0|3] ""  IHU
 SG_ Language : 19|4@0+ (1,0) [0|15] ""  IHU
 SG_ LDW : 15|1@0+ (1,0) [0|1] ""  IHU
 SG_ EngineFuelType : 14|2@0+ (1,0) [0|3] ""  IHU
 SG_ Radar_RadaralarmDisplayonICM_ : 12|1@0+ (1,0) [0|1] ""  IHU
 SG_ FuelConsumptionCorrect : 11|2@0+ (1,0) [0|3] ""  IHU
 SG_ MaintainMileage : 9|1@0+ (1,0) [0|1] ""  IHU
 SG_ FirstMaintain : 8|1@0+ (1,0) [0|1] ""  IHU
 SG_ InitialFuelConsumption : 7|8@0+ (1,0) [0|255] ""  IHU

BO_ 1505 BCM_6: 8 Vector__XXX
 SG_ PEPSType : 61|2@0+ (1,0) [0|3] ""  IHU
 SG_ EmissionType : 52|1@0+ (1,0) [0|1] ""  IHU
 SG_ TCU3_CVT25_CVT18 : 39|1@0+ (1,0) [0|1] ""  IHU
 SG_ CGW : 38|1@0+ (1,0) [0|1] ""  IHU
 SG_ MFS_LIN : 36|1@0+ (1,0) [0|1] ""  IHU
 SG_ PLG : 34|1@0+ (1,0) [0|1] ""  IHU
 SG_ FRM : 33|1@0+ (1,0) [0|1] ""  IHU
 SG_ FCM : 32|1@0+ (1,0) [0|1] ""  IHU
 SG_ TCU4_7DCT_DHT : 31|1@0+ (1,0) [0|1] ""  IHU
 SG_ EIPM_ONCAN : 30|1@0+ (1,0) [0|1] ""  IHU
 SG_ BSD : 29|1@0+ (1,0) [0|1] ""  IHU
 SG_ EPB : 28|1@0+ (1,0) [0|1] ""  IHU
 SG_ AVM : 25|1@0+ (1,0) [0|1] ""  IHU
 SG_ RADAR : 24|1@0+ (1,0) [0|1] ""  IHU
 SG_ SAS : 17|1@0+ (1,0) [0|1] ""  IHU
 SG_ TPMS : 16|1@0+ (1,0) [0|1] ""  IHU
 SG_ APM : 15|1@0+ (1,0) [0|1] ""  IHU
 SG_ PEPS : 12|1@0+ (1,0) [0|1] ""  IHU
 SG_ EPS : 11|1@0+ (1,0) [0|1] ""  IHU
 SG_ CLM : 10|1@0+ (1,0) [0|1] ""  IHU
 SG_ TCU2_6DCT : 9|1@0+ (1,0) [0|1] ""  IHU
 SG_ TCU1_CVT19 : 8|1@0+ (1,0) [0|1] ""  IHU
 SG_ IMMO : 7|2@0+ (1,0) [0|3] ""  IHU
 SG_ ESP : 5|1@0+ (1,0) [0|1] ""  IHU
 SG_ ABS : 4|1@0+ (1,0) [0|1] ""  IHU
 SG_ ABM : 3|1@0+ (1,0) [0|1] ""  IHU
 SG_ ICM : 2|1@0+ (1,0) [0|1] ""  IHU
 SG_ BCM : 1|1@0+ (1,0) [0|1] ""  IHU
 SG_ EMS : 0|1@0+ (1,0) [0|1] ""  IHU

BO_ 1307 BCM_5: 8 Vector__XXX
 SG_ RHRTirePressure : 63|8@0+ (0.0177,0) [0|4.5] "bar"  IHU
 SG_ LHRTirePressure : 55|8@0+ (0.0177,0) [0|4.5] "bar"  IHU
 SG_ RHFTirePressure : 47|8@0+ (0.0177,0) [0|4.5] "bar"  IHU
 SG_ LHFTirePressure : 39|8@0+ (0.0177,0) [0|4.5] "bar"  IHU
 SG_ TireTemperature : 31|8@0+ (0.65,-40) [-40|125] "℃"  IHU
 SG_ TirePosition : 17|2@0+ (1,0) [0|3] ""  IHU
 SG_ TirePositionWarning_RHRTire : 10|3@0+ (1,0) [0|7] ""  IHU
 SG_ TirePositionWarning_LHRTire : 13|3@0+ (1,0) [0|7] ""  IHU
 SG_ TirePositionWarning_RHFTire : 0|3@0+ (1,0) [0|7] ""  IHU
 SG_ TirePositionWarning_LHFTire : 3|3@0+ (1,0) [0|7] ""  IHU
 SG_ TirePressureWarningLampSts : 5|2@0+ (1,0) [0|3] ""  IHU

BO_ 914 BCM_4: 8 Vector__XXX
 SG_ DRLModeSts : 58|1@0+ (1,0) [0|1] ""  IHU
 SG_ HeadlampDelayLightSts : 57|1@0+ (1,0) [0|1] ""  IHU
 SG_ AutolockSts : 56|1@0+ (1,0) [0|1] ""  IHU
 SG_ AutoFoldSts : 63|1@0+ (1,0) [0|1] ""  IHU
 SG_ HeadlampHeightFeedbackSts : 52|3@0+ (1,0) [0|7] ""  IHU
 SG_ RemoteLockFeedbackSts : 54|2@0+ (1,0) [0|3] ""  IHU
 SG_ BCM_4_ReverseGearSts : 35|1@0+ (1,0) [0|1] ""  IHU
 SG_ BCM_4_RearFogLightSts : 34|1@0+ (1,0) [0|1] ""  IHU
 SG_ BCM_4_DriverDoorLockSts : 31|1@0+ (1,0) [0|1] ""  IHU
 SG_ BCM_4_TrunkSts : 30|1@0+ (1,0) [0|1] ""  IHU
 SG_ BCM_4_LHRdoorSts : 29|1@0+ (1,0) [0|1] ""  IHU
 SG_ BCM_4_RHRDoorSts : 28|1@0+ (1,0) [0|1] ""  IHU
 SG_ BCM_4_HoodSts : 26|1@0+ (1,0) [0|1] ""  IHU
 SG_ BCM_4_PsngrDoorSts : 25|1@0+ (1,0) [0|1] ""  IHU
 SG_ BCM_4_DriverDoorSts : 24|1@0+ (1,0) [0|1] ""  IHU
 SG_ RVSMode : 19|1@0+ (1,0) [0|1] ""  IHU
 SG_ DirectionIndLeft : 17|1@0+ (1,0) [0|1] ""  IHU
 SG_ DirectionIndRight : 16|1@0+ (1,0) [0|1] ""  IHU
 SG_ BCM_4_ParkLightSts : 11|1@0+ (1,0) [0|1] ""  IHU
 SG_ DrvrDoorUnlckOnlySts : 10|1@0+ (1,0) [0|1] ""  IHU
 SG_ FGHeat_Req_CmdFeedback : 7|1@0+ (1,0) [0|1] ""  IHU
 SG_ BCM_4_KeySts : 6|2@0+ (1,0) [0|3] ""  IHU
 SG_ LightDetected : 4|1@0+ (1,0) [0|1] ""  IHU
 SG_ BCM_4_ArmingSts : 1|2@0+ (1,0) [0|3] ""  IHU

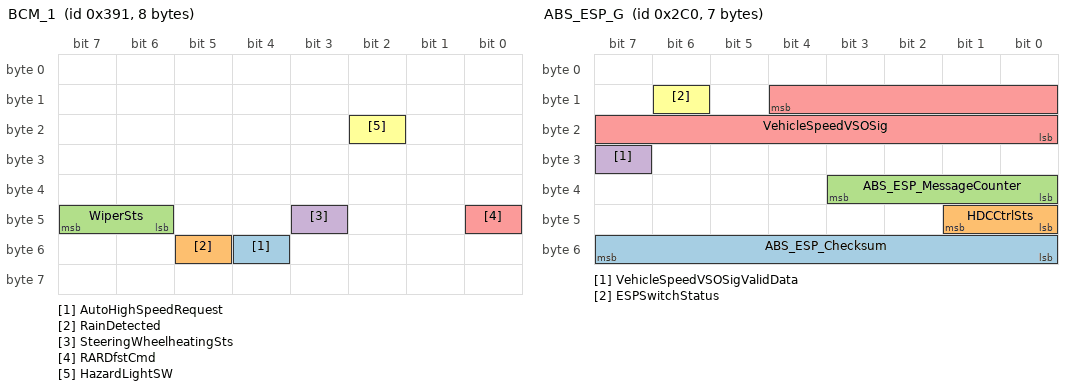
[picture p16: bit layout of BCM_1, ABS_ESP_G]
BO_ 913 BCM_1: 8 Vector__XXX
 SG_ AutoHighSpeedRequest : 52|1@0+ (1,0) [0|1] ""  IHU
 SG_ RainDetected : 53|1@0+ (1,0) [0|1] ""  IHU
 SG_ WiperSts : 47|2@0+ (1,0) [0|3] ""  IHU
 SG_ SteeringWheelheatingSts : 43|1@0+ (1,0) [0|1] ""  IHU
 SG_ RARDfstCmd : 40|1@0+ (1,0) [0|1] ""  IHU
 SG_ HazardLightSW : 18|1@0+ (1,0) [0|1] ""  IHU

BO_ 1217 ASU_1: 8 Vector__XXX
 SG_ ASU_1_SetModsts : 3|2@0+ (1,0) [0|3] ""  IHU
 SG_ ASU_1_AssocWithDrvrModFB : 5|2@0+ (1,0) [0|3] ""  IHU

BO_ 554 AVM_APA_1: 8 Vector__XXX
 SG_ APAFailureSts : 7|1@0+ (1,0) [0|1] ""  IHU
 SG_ APA_Active : 6|1@0+ (1,0) [0|1] ""  IHU
 SG_ AVM_APA_SystemSts : 5|3@0+ (1,0) [0|7] ""  IHU

BO_ 1267 AIPM_2: 8 Vector__XXX
 SG_ AIPM_2_DriveModeSet : 35|2@0+ (1,0) [0|3] ""  IHU

BO_ 1265 AIPM_1: 8 Vector__XXX
 SG_ PanelKeyVoiceRemindReq : 8|1@0+ (1,0) [0|1] ""  IHU

BO_ 704 ABS_ESP_G: 7 Vector__XXX
 SG_ ABS_ESP_Checksum : 55|8@0+ (1,0) [0|255] ""  IHU
 SG_ HDCCtrlSts : 41|2@0+ (1,0) [0|3] ""  IHU
 SG_ ABS_ESP_MessageCounter : 35|4@0+ (1,0) [0|15] ""  IHU
 SG_ VehicleSpeedVSOSigValidData : 31|1@0+ (1,0) [0|1] ""  IHU
 SG_ VehicleSpeedVSOSig : 12|13@0+ (0.0625,0) [0|511.875] "km/h"  IHU
 SG_ ESPSwitchStatus : 14|1@0+ (1,0) [0|1] ""  IHU

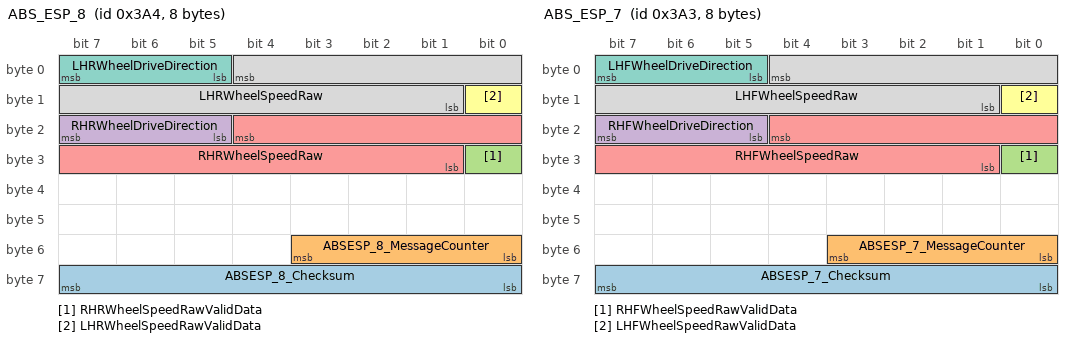
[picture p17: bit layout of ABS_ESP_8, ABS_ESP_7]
BO_ 932 ABS_ESP_8: 8 Vector__XXX
 SG_ ABSESP_8_Checksum : 63|8@0+ (1,0) [0|255] ""  IHU
 SG_ ABSESP_8_MessageCounter : 51|4@0+ (1,0) [0|15] ""  IHU
 SG_ RHRWheelSpeedRawValidData : 24|1@0+ (1,0) [0|1] ""  IHU
 SG_ RHRWheelDriveDirection : 23|3@0+ (1,0) [0|7] ""  IHU
 SG_ RHRWheelSpeedRaw : 20|12@0+ (0.05,-30) [-30|80] "m/s"  IHU
 SG_ LHRWheelSpeedRawValidData : 8|1@0+ (1,0) [0|1] ""  IHU
 SG_ LHRWheelDriveDirection : 7|3@0+ (1,0) [0|7] ""  IHU
 SG_ LHRWheelSpeedRaw : 4|12@0+ (0.05,-30) [-30|80] "m/s"  IHU

BO_ 931 ABS_ESP_7: 8 Vector__XXX
 SG_ ABSESP_7_Checksum : 63|8@0+ (1,0) [0|255] ""  IHU
 SG_ ABSESP_7_MessageCounter : 51|4@0+ (1,0) [0|15] ""  IHU
 SG_ RHFWheelSpeedRawValidData : 24|1@0+ (1,0) [0|1] ""  IHU
 SG_ RHFWheelDriveDirection : 23|3@0+ (1,0) [0|7] ""  IHU
 SG_ RHFWheelSpeedRaw : 20|12@0+ (0.05,-30) [-30|80] "m/s"  IHU
 SG_ LHFWheelSpeedRawValidData : 8|1@0+ (1,0) [0|1] ""  IHU
 SG_ LHFWheelDriveDirection : 7|3@0+ (1,0) [0|7] ""  IHU
 SG_ LHFWheelSpeedRaw : 4|12@0+ (0.05,-30) [-30|80] "m/s"  IHU

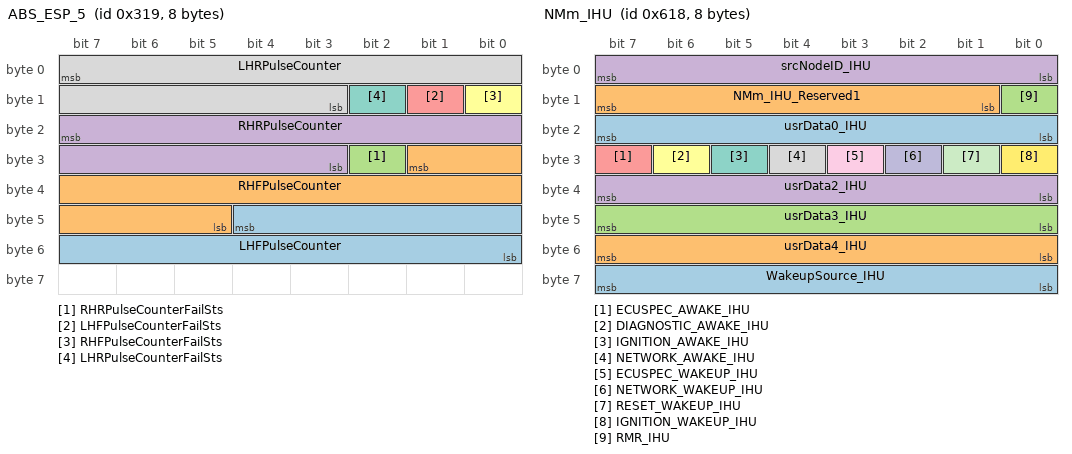
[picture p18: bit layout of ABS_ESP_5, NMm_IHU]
BO_ 793 ABS_ESP_5: 8 Vector__XXX
 SG_ LHFPulseCounter : 44|13@0+ (1,0) [0|8191] "pulse"  IHU
 SG_ RHFPulseCounter : 25|13@0+ (1,0) [0|8191] "pulse"  IHU
 SG_ RHRPulseCounterFailSts : 26|1@0+ (1,0) [0|1] ""  IHU
 SG_ RHRPulseCounter : 23|13@0+ (1,0) [0|8191] "pulse"  IHU
 SG_ LHFPulseCounterFailSts : 9|1@0+ (1,0) [0|1] ""  IHU
 SG_ RHFPulseCounterFailSts : 8|1@0+ (1,0) [0|1] ""  IHU
 SG_ LHRPulseCounterFailSts : 10|1@0+ (1,0) [0|1] ""  IHU
 SG_ LHRPulseCounter : 7|13@0+ (1,0) [0|8191] "pulse"  IHU

BO_ 787 ABS_ESP_3: 8 Vector__XXX
 SG_ ABS_ESP_3_AVHSts : 53|2@0+ (1,0) [0|3] ""  IHU
 SG_ ABS_ESP_3_AVHFailSts : 39|1@0+ (1,0) [0|1] ""  IHU

BO_ 800 ABM_1: 4 Vector__XXX
 SG_ ABM_1_PABSetSts : 11|1@0+ (1,0) [0|1] ""  IHU

BO_ 1882 Diag_IHU_RES: 8 IHU
 SG_ Diag_IHU_RES : 7|64@0+ (1,0) [0|0] "" Vector__XXX

BO_ 1942 DMC_ACP_RES: 8 Vector__XXX
 SG_ DMC__ACP_RES : 7|64@0+ (1,0) [0|0] ""  IHU

BO_ 1926 DMC_ACP_REQ: 8 IHU
 SG_ DMC__ACP_REQ : 7|64@0+ (1,0) [0|0] "" Vector__XXX

BO_ 1560 NMm_IHU: 8 IHU
 SG_ WakeupSource_IHU : 63|8@0+ (1,0) [0|255] "" Vector__XXX
 SG_ usrData4_IHU : 55|8@0+ (1,0) [0|255] "" Vector__XXX
 SG_ usrData3_IHU : 47|8@0+ (1,0) [0|255] "" Vector__XXX
 SG_ usrData2_IHU : 39|8@0+ (1,0) [0|255] "" Vector__XXX
 SG_ ECUSPEC_AWAKE_IHU : 31|1@0+ (1,0) [0|1] "" Vector__XXX
 SG_ DIAGNOSTIC_AWAKE_IHU : 30|1@0+ (1,0) [0|1] "" Vector__XXX
 SG_ IGNITION_AWAKE_IHU : 29|1@0+ (1,0) [0|1] "" Vector__XXX
 SG_ NETWORK_AWAKE_IHU : 28|1@0+ (1,0) [0|1] "" Vector__XXX
 SG_ ECUSPEC_WAKEUP_IHU : 27|1@0+ (1,0) [0|1] "" Vector__XXX
 SG_ NETWORK_WAKEUP_IHU : 26|1@0+ (1,0) [0|1] "" Vector__XXX
 SG_ RESET_WAKEUP_IHU : 25|1@0+ (1,0) [0|1] "" Vector__XXX
 SG_ IGNITION_WAKEUP_IHU : 24|1@0+ (1,0) [0|1] "" Vector__XXX
 SG_ usrData0_IHU : 23|8@0+ (1,0) [0|255] "" Vector__XXX
 SG_ NMm_IHU_Reserved1 : 15|7@0+ (1,0) [0|127] "" Vector__XXX
 SG_ RMR_IHU : 8|1@0+ (1,0) [0|1] "" Vector__XXX
 SG_ srcNodeID_IHU : 7|8@0+ (1,0) [0|255] "" Vector__XXX

BO_ 1266 TBOX_2: 8 Vector__XXX
 SG_ TBOX_SetAVMVeiw : 34|3@0+ (1,0) [0|7] ""  IHU
 SG_ TBOX_SetAVMOnReq : 36|2@0+ (1,0) [0|3] ""  IHU

BO_ 1312 TBOX_1: 4 Vector__XXX
 SG_ TBOX_1_RemDiagSts : 23|2@0+ (1,0) [0|3] ""  IHU

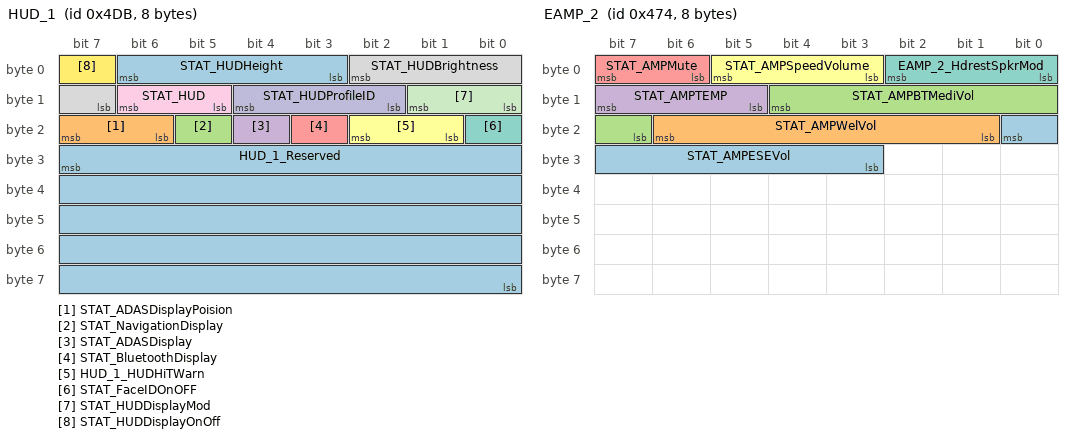
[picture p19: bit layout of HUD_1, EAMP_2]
BO_ 1243 HUD_1: 8 Vector__XXX
 SG_ HUD_1_Reserved : 31|40@0+ (1,0) [0|0] ""  IHU
 SG_ STAT_ADASDisplayPoision : 23|2@0+ (1,0) [0|3] ""  IHU
 SG_ STAT_NavigationDisplay : 21|1@0+ (1,0) [0|1] ""  IHU
 SG_ STAT_ADASDisplay : 20|1@0+ (1,0) [0|1] ""  IHU
 SG_ STAT_BluetoothDisplay : 19|1@0+ (1,0) [0|1] ""  IHU
 SG_ HUD_1_HUDHiTWarn : 18|2@0+ (1,0) [0|3] ""  IHU
 SG_ STAT_FaceIDOnOFF : 16|1@0+ (1,0) [0|1] ""  IHU
 SG_ STAT_HUDBrightness : 2|4@0+ (1,0) [0|15] ""  IHU
 SG_ STAT_HUD : 14|2@0+ (1,0) [0|3] ""  IHU
 SG_ STAT_HUDProfileID : 12|3@0+ (1,0) [0|7] ""  IHU
 SG_ STAT_HUDDisplayMod : 9|2@0+ (1,0) [0|3] ""  IHU
 SG_ STAT_HUDDisplayOnOff : 7|1@0+ (1,0) [0|1] ""  IHU
 SG_ STAT_HUDHeight : 6|4@0+ (1,0) [0|15] ""  IHU

BO_ 1140 EAMP_2: 8 Vector__XXX
 SG_ STAT_AMPESEVol : 16|6@0+ (1,0) [0|63] ""  IHU
 SG_ STAT_AMPWelVol : 22|6@0+ (1,0) [0|63] ""  IHU
 SG_ STAT_AMPBTMediVol : 12|6@0+ (1,0) [0|63] ""  IHU
 SG_ STAT_AMPTEMP : 15|3@0+ (1,0) [0|7] ""  IHU
 SG_ STAT_AMPMute : 7|2@0+ (1,0) [0|3] ""  IHU
 SG_ STAT_AMPSpeedVolume : 5|3@0+ (1,0) [0|7] ""  IHU
 SG_ EAMP_2_HdrestSpkrMod : 2|3@0+ (1,0) [0|7] ""  IHU

BO_ 1121 EAMP_1: 8 Vector__XXX
 SG_ STAT_AMPAlarmVolume : 63|4@0+ (1,0) [1|15] ""  IHU
 SG_ STAT_AMPLoudness : 59|2@0+ (1,0) [0|3] ""  IHU
 SG_ STAT_AMPLiveAcoustics : 57|2@0+ (1,0) [0|3] ""  IHU
 SG_ STAT_AMPSoundFieldFader : 55|4@0+ (1,0) [0|15] ""  IHU
 SG_ STAT_AMPSoundFieldBalance : 51|4@0+ (1,0) [0|15] ""  IHU
 SG_ STAT_AMPSoundEffectTreble : 47|4@0+ (1,0) [0|15] ""  IHU
 SG_ STAT_AMPSoundEffectMidrange : 43|4@0+ (1,0) [0|15] ""  IHU
 SG_ STAT_AMPSoundEffectBass : 39|4@0+ (1,0) [0|15] ""  IHU
 SG_ STAT_AMPSoundEffect : 35|4@0+ (1,0) [0|15] ""  IHU
 SG_ STAT_AMPRestoreDefaults : 31|2@0+ (1,0) [0|3] ""  IHU
 SG_ STAT_AMPDefaultVolume : 29|6@0+ (1,0) [0|63] ""  IHU
 SG_ STAT_AMPSoundFocus : 23|3@0+ (1,0) [0|15] ""  IHU
 SG_ STAT_AMPPhoneVolume : 20|5@0+ (1,0) [0|31] ""  IHU
 SG_ STAT_AMPMediaVolume : 15|6@0+ (1,0) [0|63] ""  IHU
 SG_ STAT_AMPKeyTone : 9|2@0+ (1,0) [0|3] ""  IHU
 SG_ STAT_AMPVRVolume : 7|4@0+ (1,0) [0|15] ""  IHU
 SG_ STAT_AMPNaviVolume : 3|4@0+ (1,0) [0|15] ""  IHU

BO_ 1517 HUD_IHU_Interaction: 8 Vector__XXX
 SG_ HUD_IHU_Interaction : 7|64@0+ (1,0) [0|0] ""  IHU

BO_ 1515 IHU_HUD_Interaction: 8 IHU
 SG_ IHU_HUD_Interaction : 7|64@0+ (1,0) [0|0] "" Vector__XXX

BO_ 1298 IHU_CVBOX_Interaction: 8 IHU
 SG_ IHU_CVBOX_Interaction : 7|64@0+ (1,0) [0|0] "" Vector__XXX

BO_ 1289 CVBOX_IHU_Interaction: 8 Vector__XXX
 SG_ CVBOX_IHU_Interaction : 7|64@0+ (1,0) [0|0] ""  IHU

BO_ 759 DVR_TIHU_Interaction: 8 Vector__XXX
 SG_ DVR_TIHU_Interaction : 7|64@0+ (1,0) [0|0] ""  IHU

BO_ 755 TIHU_DVR_Interaction: 8 IHU
 SG_ IHU_DVR_Interaction : 7|64@0+ (1,0) [0|0] "" Vector__XXX

BO_ 1506 TIHU_ICM_Interaction: 8 IHU
 SG_ InteractiveDisplayInfo : 7|64@0+ (1,0) [0|0] "" Vector__XXX

BO_ 1151 TIHU_IMMO_12: 8 IHU
 SG_ TIHU_Teach_IMMO : 7|64@0+ (1,0) [0|0] "" Vector__XXX

BO_ 1116 TIHU_IMMO_11: 8 IHU
 SG_ TIHU_Auth : 7|64@0+ (1,0) [0|0] "" Vector__XXX

CM_ BO_ 2015 "Source network message is \"NoMsgSendType,/\".
If no messages are received on source network, no messages are sent on the destination network.";
CM_ BO_ 1866 "Source network message is \"NoMsgSendType, /\".
If no messages are received on source network, no messages are sent on the destination network.";
CM_ BO_ 928 "Source network message is \"Cyclic, 20ms\".
If no messages are received on source network, no messages are sent on the destination network.";
CM_ SG_ 928 YAS_2_Checksum "0x01 XOR 0x28 XOR Byte0 XOR Byte1 XOR Byte2 XOR Byte3 XOR Byte4 XOR Byte5 XOR Byte6";
CM_ SG_ 928 LongitudinalAcceleration "???????????
??????????!mao!0.0027680342857143 g";
CM_ SG_ 928 LongitudinalAccelerationSigValid "If hasn??t been calibrated, after initialization, this signal ??s value is always10(invalid)";
CM_ BO_ 926 "Source network message is \"Cyclic, 20ms\".
If no messages are received on source network, no messages are sent on the destination network.";
CM_ SG_ 926 YAS_1_Checksum "0x01 XOR 0x27 XOR Byte0 XOR Byte1 XOR Byte2 XOR Byte3 XOR Byte4 XOR Byte5 XOR Byte6";
CM_ SG_ 926 YawRate "???????????                ??????????：0.122189236 deg/s";
CM_ SG_ 926 YawrateSigValidData "Signal state for yawrate";
CM_ BO_ 769 "Source network message is \"Cyclic, 100ms\".
If no messages are received on source network, no messages are sent on the destination network.";
CM_ SG_ 769 GBPositoionDisplay "?????M1??，????5，???????????，??01101??????????????????
Low???CVT?С?for PHEV!mao!TCU only has 0x0!dun!0x1!dun!0x2!dun!0x3!dun!0x4";
CM_ BO_ 1206 "Source network message is \"Cyclic, 100ms\".
If no messages are received on source network, no messages are sent on the destination network.";
CM_ SG_ 1206 SHU2R_RSeatVentnSts "Seat Ventilation Status
????????????????";
CM_ SG_ 1206 SHU2R_RSeatHeatSts "Seat Heat Status
??????????μ?????";
CM_ BO_ 1202 "Source network message is \"Cyclic, 100ms\".
If no messages are received on source network, no messages are sent on the destination network.";
CM_ SG_ 1202 SHU2M_MSeatVentnSts "Seat Ventilation Status
?????м??????????";
CM_ SG_ 1202 SHU2M_MSeatHeatSts "Seat Heat Status
?????м????μ?????";
CM_ BO_ 1194 "Source network message is \"Cyclic, 100ms\".
If no messages are received on source network, no messages are sent on the destination network.";
CM_ SG_ 1194 SHU2L_LSeatVentnSts "Seat Ventilation Status
????????????????";
CM_ SG_ 1194 SHU2L_LSeatHeatSts "Seat Heat Status
??????????μ?????";
CM_ BO_ 1190 "Source network message is \"Cyclic, 100ms\".
If no messages are received on source network, no messages are sent on the destination network.";
CM_ SG_ 1190 SHU1R_RSeatAutVentnSts "Passenger Seat Automatic Ventilation Status";
CM_ SG_ 1190 SHU1R_RSeatAutHeatSts "Passenger Seat Automatic Heat Status";
CM_ SG_ 1190 SHU1R_RSeatVentnSts "Passenger Seat Ventilation Status
???????????????";
CM_ SG_ 1190 SHU1R_RSeatHeatSts "Passenger Seat Heat Status
?????????μ?????";
CM_ BO_ 1186 "Source network message is \"Cyclic, 100ms\".
If no messages are received on source network, no messages are sent on the destination network.";
CM_ SG_ 1186 SHU1L_LSeatAutVentnSts "Driver Seat Automatic Ventilation Status";
CM_ SG_ 1186 SHU1L_LSeatAutHeatSts "Driver Seat Automatic Heat Status";
CM_ SG_ 1186 SHU1L_LSeatVentnSts "Driver Seat Ventilation Status
????????????????";
CM_ SG_ 1186 SHU1L_LSeatHeatSts "Driver Seat Heat Status
??????????μ?????";
CM_ SG_ 1170 SCU_2_CRC "CRC (SAE J1850 CRC-8)
Note: Details Please refer to specification??Standard Specification for CAN Data Link Layer_v1.1??section 2.3.2";
CM_ SG_ 1170 SCU_2_MessageCounter "Rolling message counter(the maximum value of Alive counter is 15)
Note: Details Please refer to specification??Standard Specification for CAN Data Link Layer_v1.1??section 2.3.1";
CM_ SG_ 1170 SCU_2_SeatLegSpprtPosnStsTar "Seat leg support position status";
CM_ SG_ 1170 SCU_2_SeatLvlPosnStsTar "Seat level position status";
CM_ SG_ 1170 SCU_2_SeatHdrestHeiAdjmt "Seat headrest height adjustment";
CM_ SG_ 1170 SCU_2_BackrAgPosnStsTar "Seat back angle position status";
CM_ SG_ 1170 SCU_2_SeatCushPosnSts "Seat cushion position status";
CM_ SG_ 1170 SCU_2_SeatHeiPosnStsTar "Seat height position status";
CM_ BO_ 1090 "Source network message is \"Cyclic, 100ms\".
If no messages are received on source network, no messages are sent on the destination network.";
CM_ SG_ 1090 PsngrSeatVentilationFeedbackSts "0x3: Seat Ventilation Level3 is only for EEA4.0 project
?????????????";
CM_ SG_ 1090 DriverSeatVentilationFeedbackSts "0x3: Seat Ventilation Level3 is only for EEA4.0 project
?????????????";
CM_ SG_ 1090 Seat_ExtMirror_PositionInfo "???η?????DVD??????λ????????";
CM_ SG_ 1090 SCURelateKeyOrFaceIDFeedbackSts "???μ??书???????????ID?????????????
??????????????!mao!?????????μ??书????????????????????
????????????????!mao!?????????μ??书???????????ID????????";
CM_ SG_ 1090 Seat_ExtMirror_MemorySts "????/????????????
0x0!mao!??д???????/??????λ?ü??书???!dou!??????0x0
0x1!mao!??????
0x2!mao!???????
???????!dou!???????????0x1!mao!success!dou!???0x0!mao!Not active";
CM_ SG_ 1090 PsngrSeatHeatFeedbackSts "0x3: Seat heating Level3 is only for EEA4.0 project
???????μ?????";
CM_ SG_ 1090 DriverSeatHeatFeedbackSts "0x3: Seat heating Level3 is only for EEA4.0 project
???????μ?????";
CM_ SG_ 1090 ReverseExtMirrorFeedbackSts "???????????·???????";
CM_ SG_ 1090 EasyEntryFeedbackSts "EasyEntry??????";
CM_ SG_ 1090 Seat_ExtMirror_MemoryReq "???μ???/??????????????
Note:???????????????????λ???????!dou!???????????3s????в??????????,???????????????????????!dou!????????????0x1!mao!Reuqest!dou!???0x0!mao!Not Request";
CM_ SG_ 1090 Seat_ExtMirror_MemoryEnable "???μ???/????????????????????
Note!mao!??????????????!dou!????????0x1??";
CM_ BO_ 924 "Source network message is \"Cyclic, 10ms\".
If no messages are received on source network, no messages are sent on the destination network.";
CM_ SG_ 924 SAM_1_GCRCCheck "CRC (SAE J1850 CRC-8)
Note: Details Please refer to specification??Standard Specification for CAN Data Link Layer_v1.1??section 2.3.2";
CM_ SG_ 924 SAM_1_G_MessageCounter "Rolling message counter(the maximum value of Alive counter is 15)
Note: Details Please refer to specification??Standard Specification for CAN Data Link Layer_v1.1??section 2.3.1";
CM_ SG_ 924 AngleFailure "????????????????SAS????????????
SASδ????б?????????????Χ???1-failure";
CM_ SG_ 924 SteeringAngle "The actual range is from -720 deg to +720 deg.";
CM_ BO_ 1203 "Source network message is \"Cyclic, 100ms\".
If no messages are received on source network, no messages are sent on the destination network.";
CM_ SG_ 1203 RRCR_1_CRC "CRC (SAE J1850 CRC-8)
Note: Details Please refer to specification??EE Standard Specification for CAN FD Network Implementation??section 2.3.2";
CM_ SG_ 1203 RRCR_1_MsgCntr "Rolling message counter(the maximum value of Alive counter is 15)
Note: Details Please refer to specification??EE Standard Specification for CAN FD Network Implementation??section 2.3.1";
CM_ SG_ 1203 RRCR_1_RCTAWarn "RCTA Warning";
CM_ SG_ 1203 RRCR_1_BSDWarn "Blind spot detection system Warning";
CM_ SG_ 1203 RRCR_1_SysSt "System State (only for VEONEER)";
CM_ BO_ 498 "Source network message is \"Cyclic, 10ms\".
If no messages are received on source network, no messages are sent on the destination network.";
CM_ SG_ 498 RLCR_2_RCTBONOFFSts "RCTB Switch status";
CM_ SG_ 498 RLCR_2_RAEBONOFFSts "RAEB Switch status";
CM_ BO_ 1201 "Source network message is \"Cyclic, 100ms\".
If no messages are received on source network, no messages are sent on the destination network.";
CM_ SG_ 1201 RLCR_1_CRC "CRC (SAE J1850 CRC-8)
Note: Details Please refer to specification??EE Standard Specification for CAN FD Network Implementation??section 2.3.2";
CM_ SG_ 1201 RLCR_1_MsgCntr "Rolling message counter(the maximum value of Alive counter is 15)
Note: Details Please refer to specification??EE Standard Specification for CAN FD Network Implementation??section 2.3.1";
CM_ SG_ 1201 RLCR_1_RCWONOFFSts "Rear Collision Warning Switch Status";
CM_ SG_ 1201 RLCR_1_DOWONOFFSts "Door open warning Switch status";
CM_ SG_ 1201 RLCR_1_BSDLCARCTAONOFFSts "Blind spot detection system/LCA/RCTA Switch status";
CM_ SG_ 1201 RLCR_1_RCTAWarn "RCTA Warning";
CM_ SG_ 1201 RLCR_1_BSDWarn "Blind spot detection system Warning";
CM_ SG_ 1201 RLCR_1_SysSt "System self-test State(only for VEONEER)";
CM_ BO_ 1141 "Source network message is \"Cyclic, 100ms\".
If no messages are received on source network, no messages are sent on the destination network.";
CM_ SG_ 1141 LHSFRadarSensorDistance "??????????
??????Sensor err!mao!????0x7F
???????????????!mao!????0x7E

???????!mao!????=(D)*5+30
???????!mao!????0x7E
0x5F~0x7D!mao!??Ч????";
CM_ SG_ 1141 RHSFRadarSensorDistance "??????????
??????Sensor err!mao!????0x7F
???????????????!mao!????0x7E

???????!mao!????=(D)*5+30
???????!mao!????0x7E
0x5F~0x7D!mao!??Ч????";
CM_ SG_ 1141 LHSRRadarSensorDistance "?????????
??????Sensor err!mao!????0x7F
???????????????!mao!????0x7E

???????!mao!????=(D)*5+30
???????!mao!????0x7E
0x5F~0x7D!mao!??Ч????";
CM_ SG_ 1141 RHSRRadarSensorDistance "?????????
??????Sensor err!mao!????0x7F
???????????????!mao!????0x7E

???????!mao!????=(D)*5+30
???????!mao!????0x7E
0x5F~0x7D!mao!??Ч????";
CM_ BO_ 1088 "Source network message is \"Cyclic, 100ms\".
If no messages are received on source network, no messages are sent on the destination network.";
CM_ SG_ 1088 RadarWorkSts "???????????
1!dun!Active!mao!????PAS???????????!dou!???????????!dou!?????1??
2!dun!Not Active!mao!???????????PAS??????!dou!??0(Not Active)??";
CM_ SG_ 1088 RadarDetectSts "????????
????01!dou!RRM????????????????????
????10!dou!RRM??????????????????";
CM_ SG_ 1088 AudibleBeepRate "???????
1!dun!??????????????????Startup
2!dun!??????????!mao!??????????
3!dun!?????????RadarWorkSts??????";
CM_ SG_ 1088 LHMFRadarSensorDistance "??????????
??????Sensor err!mao!????0x1F
???????????????!mao!????0x1E

???????!mao!????=(D)*5+25
???????!mao!????0x1E
???????(??4 ??)!mao!????0x1E
0x1C~0x1D!mao!??Ч????";
CM_ SG_ 1088 RHMFRadarSensorDistance "??????????
??????Sensor err!mao!????0x1F
???????????????!mao!????0x1E

???????!mao!????=(D)*5+25
???????!mao!????0x1E
???????(??4 ??)!mao!????0x1E
0x1C~0x1D!mao!??Ч????";
CM_ SG_ 1088 RHFRadarSensorDistance "????????
??????Sensor err!mao!????0x1F
???????????????!mao!????0x1E

???????!mao!????=(D)*5+25
???????!mao!????0x1E
???????(??4 ??)!mao!????0x1E
0x1C~0x1D!mao!??Ч????";
CM_ SG_ 1088 LHFRadarSensorDistance "????????
??????Sensor err!mao!????0x1F
???????????????!mao!????0x1E

???????!mao!????=(D)*5+25
???????!mao!????0x1E
???????(??4 ??)!mao!????0x1E
0x1C~0x1D!mao!??Ч????";
CM_ SG_ 1088 RHRRadarSensorDistance "????????
??????Sensor err!mao!????0x3F
???????????????!mao!????0x3E

???????!mao!????=(D)*5+25
???????!mao!????0x3E
0x20~0x3D!mao!??Ч????\"";
CM_ SG_ 1088 LHMRRadarSensorDistance "???к??????
??????Sensor err!mao!????0x3F
???????????????!mao!????0x3E

???????!mao!????=(D)*5+25
???????!mao!????0x3E 
0x20~0x3D!mao!??Ч????";
CM_ SG_ 1088 RHMRRadarSensorDistance "???к??????
??????Sensor err!mao!????0x3F
???????????????!mao!????0x3E

???????!mao!????=(D)*5+25
???????!mao!????0x3E 
0x20~0x3D!mao!??Ч????";
CM_ SG_ 1088 LHRRadarSensorDistance "????????
??????Sensor err!mao!????0x3F
???????????????!mao!????0x3E

???????!mao!????=(D)*5+25
???????!mao!????0x3E
0x20~0x3D!mao!??Ч????";
CM_ BO_ 1078 "Source network message is \"Cyclic, 100ms\".
If no messages are received on source network, no messages are sent on the destination network.";
CM_ SG_ 1078 PLG_OperateSts "β????????";
CM_ SG_ 1078 PLG_Set_MaxPosition "β????????????λ??";
CM_ BO_ 1042 "Source network message is \"Cyclic, 100ms\".
If no messages are received on source network, no messages are sent on the destination network.";
CM_ SG_ 1042 PEPS_BLTKey_PESts "????????PE??????????????";
CM_ BO_ 998 "Source network message is \"Cyclic, 50ms\".
If no messages are received on source network, no messages are sent on the destination network.";
CM_ SG_ 998 RemoteStartSts "????????";
CM_ SG_ 998 Start_StopRequest "???,???????";
CM_ SG_ 998 IDInformation "To show which ID is sending the signal.";
CM_ BO_ 1124 "Source network message is \"Cyclic, 100ms\".
If no messages are received on source network, no messages are sent on the destination network.";
CM_ SG_ 1124 NFC_1_DispCardPosn "Display card position";
CM_ BO_ 864 "Source network message is \"Cyclic, 50ms\".
If no messages are received on source network, no messages are sent on the destination network.";
CM_ BO_ 945 "Source network message is \"Cyclic, 50ms\".
If no messages are received on source network, no messages are sent on the destination network.";
CM_ SG_ 945 MFS_TJA_ICA_ON_OFF "IHU???MFS?????TJA_ICA_ON_OFF?????????????0?，?????????????????，??IHU_7?а???Not Active??????????????1????2?，??????????，IHU????????ε??????????η???switch off，??仯??η???switch on;??????";
CM_ BO_ 1218 "Source network message is \"Cyclic, 100ms\".
If no messages are received on source network, no messages are sent on the destination network.";
CM_ BO_ 1059 "Source network message is \"Cyclic, 100ms\".
If no messages are received on source network, no messages are sent on the destination network.";
CM_ SG_ 1059 LDWSensitivitySettingFeedback "LDW???????????
?????????????????????,Low????????????,High?????????????????????.";
CM_ SG_ 1059 LDWSwitchStsFeedback "LDW?????????????";
CM_ BO_ 1175 "Source network message is \"Cyclic, 100ms\".
If no messages are received on source network, no messages are sent on the destination network.";
CM_ SG_ 1175 CST_Status "CST:Comfortable stop";
CM_ BO_ 1149 "Source network message is \"NoMsgSendType, /\".
If no messages are received on source network, no messages are sent on the destination network.";
CM_ BO_ 1110 "Source network message is \"NoMsgSendType, /\".
If no messages are received on source network, no messages are sent on the destination network.";
CM_ BO_ 1508 "Source network message is \"NoMsgSendType, /\".
If no messages are received on source network, no messages are sent on the destination network.";
CM_ SG_ 1508 ICM_4_InteractiveDisplayInfo "Refer to ??T15 RRM and ICM Interactive Display Communication Specification??";
CM_ SG_ 906 IDCU_12CPMod "Chery Pilot Mode
???????!dou!?????
???????????????
??????CP???????????????
??????CP??????????????
???????????????
??????NOC???????????????
??????NOC??????????????
CP??????????????????????!dou!?????????????????
NOC??????????????????????!dou!?????????????????
?????????????!dou!??????????????
???????????
???";
CM_ SG_ 906 IDCU_12Rmninfo "HMI reminder information";
CM_ SG_ 1248 IDCU_11_DrvAssiStylests "Assist driver's default style selection Settings
???????????????????????!dou!IDCU??????";
CM_ SG_ 1248 IDCU_11_DCLCONOFFsts "Dial lever control lane change setting item switch state
???????????????????!dou!IDCU??????";
CM_ BO_ 533 "??????Σ???3?ε????? ???????Not Active.";
CM_ BO_ 647 "Source network message is \"Cyclic, 20ms\".
If no messages are received on source network, no messages are sent on the destination network.";
CM_ SG_ 647 ICM_DVDAudibleAlarmStyle "???????????：
0x0:?????
0x1:???β???
0x2!mao!???????
12.3????????????!dou!??????????DVD???????";
CM_ SG_ 647 ICM_DVDAudibleAlarm "12.3????????????，??????????DVD???????
0x0:?????";
CM_ SG_ 647 ICM_5_AlrmVolCtrl "Alarm volume control????????????
??????????????????????!dou!???????Up????Down?!dou!???????????????????????!dou!??????????????????0x0 Not active??
0x0 ??????
0x1 ???????????
0x2 ???????????";
CM_ SG_ 647 ICM_5_BackLiBriAdjmt "Backlight brightness adjustment ???????????
?????????????????????!dou!???????Up????Down?!dou!???????????????????????!dou!??????????????????0x0 Not active??
0x0 ??????
0x1 ???????????
0x2 ???????????";
CM_ BO_ 1107 "Source network message is \"Cyclic, 500ms\".
If no messages are received on source network, no messages are sent on the destination network.";
CM_ SG_ 1107 FatigureDrivingWaring "?????????";
CM_ SG_ 1107 CurrentTimeYear "??";
CM_ SG_ 1107 CurrentTimeMonth "??";
CM_ SG_ 1107 CurrentTimeDay "??";
CM_ SG_ 1107 ResidualOdometer "???????";
CM_ SG_ 1107 CurrentTimeSecond "ICM??????????????
DVD??
????????!dou!??0 (Not active)??
????????0 (Startup)?????15????????!dou!???????????(????????????????????)??";
CM_ SG_ 1107 LowFuleWarning "????????????????????DVD?????，DVD??????????????λ????????，????????????????е?????
??????λ???????Ч!dou!??????0??";
CM_ SG_ 1107 FatigureDrivingTime "????????，???????????????á?
???????????????!dou!????1 hours??????????Ч???????!dou!????????????????Ч?
??δ???????!dou!?????????Ч???
????????!dou!??1 hours??
???RRM???ù????!dou!???????????????????????????ICM????????";
CM_ SG_ 1107 CurrentTimeMinute "ICM??????????????
DVD??????????y??
????????!dou!??0 (Not active)??????????0 (Startup)?????15????????!dou!???????????(????????????????????)??";
CM_ SG_ 1107 CurrentTimeHour "ICM???????????????
DVD??????????y??
????????!dou!??0 (Not active)??????????0 (Startup)?????15????????!dou!???????????(????????????????????)??";
CM_ BO_ 1106 "Source network message is \"Cyclic, 100ms\".
If no messages are received on source network, no messages are sent on the destination network.";
CM_ SG_ 1106 ICM_2_OverSpeedValue "???：??DVD???????????，??????0x0";
CM_ SG_ 1106 AverageFuelConsumption "??????";
CM_ BO_ 1072 "Source network message is \"Cyclic, 20ms\".
If no messages are received on source network, no messages are sent on the destination network.";
CM_ SG_ 1072 FuelLevel "Unfilter signal";
CM_ SG_ 1072 ECOModeSWSts "?????1????\"ECO\"，0????\"Sport\"
MT????ECO????";
CM_ SG_ 1072 BatteryVoltage "????????????????";
CM_ SG_ 1072 DisplayVehicleSpeed "???????????，???????????";
CM_ SG_ 1072 ICM_1_HandBrakeSystemSts "???????
????????????
???????н???
?????????????????
?????????н??????
δ???!mao!??????????δ???
ErrorApplied!mao!
??EPBError????????????н???,????????EPB(apply)???????101?????????????
??EPBError????????н???,??101?????????????
??е??????000??001????????EPB?????????С?";
CM_ BO_ 903 "Source network message is \"Cyclic, 50ms\".
If no messages are received on source network, no messages are sent on the destination network.";
CM_ SG_ 903 FCM_FRM_6_VSetDis "setted target speed";
CM_ SG_ 903 FCM_FRM_6_AEBMode "AEB Mode";
CM_ SG_ 903 FCM_FRM_6_FCWMode "FCW Mode";
CM_ SG_ 903 FCM_FRM_6_TakeOverReq "Take Over Request";
CM_ SG_ 903 FCM_FRM_6_FCW_preWarning "FCW_preWarning";
CM_ SG_ 903 FCM_FRM_6_DistanceWarning "Distance Warning";
CM_ SG_ 903 FCM_FRM_6_TimeGapSetICM "Time Gap Set on the ICM";
CM_ SG_ 903 FCM_FRM_6_ACCMode "ACC Mode";
CM_ BO_ 1251 "Source network message is \"Cyclic, 100ms\".
If no messages are received on source network, no messages are sent on the destination network.";
CM_ SG_ 1251 FCM_FRM_5_DAIONOFFSts "DAI status";
CM_ SG_ 1251 FCM_FRM_5_SCFONOFFSts "SCF status";
CM_ SG_ 1251 FCM_FRM_5_FCWONOFFSts "FCW status";
CM_ SG_ 1251 FCM_FRM_5_FCWSnvtySts "FCW Sensitivity status";
CM_ SG_ 1251 FCM_FRM_5_AEBONOFFSts "AEB status";
CM_ BO_ 1020 "Source network message is \"Cyclic, 50ms\".
If no messages are received on source network, no messages are sent on the destination network.";
CM_ SG_ 1020 FCM_10_TJAICAExitTextInfoSts "TJAICA Exit Text Information status";
CM_ SG_ 1020 FCM_10_LDPTJAELKTakeoverReq "Take over request to driver";
CM_ SG_ 1020 FCM_10_TSINoParkWarn "TSI No Park Warning";
CM_ SG_ 1020 FCM_10_ELKSysSts "ELK System Status";
CM_ SG_ 1020 FCM_10_LDWSysSts "LDW System Status";
CM_ SG_ 1020 FCM_10_LDPSysSts "LDP System Status";
CM_ SG_ 1020 FCM_10_TLITrfcLi "TLI Traffic Light";
CM_ SG_ 1020 FCM_10_TSISgnLongStayDisp "TSI Sign Long Stay Display";
CM_ SG_ 1020 FCM_10_TLISysSts "TLI system Status";
CM_ SG_ 1020 FCM_10_TSISysSts "TSI System Status";
CM_ BO_ 1245 "Source network message is \"Cyclic, 100ms\".
If no messages are received on source network, no messages are sent on the destination network.";
CM_ SG_ 1245 FCM_5_ELKONOFFSts "ELK status";
CM_ SG_ 1245 FCM_5_LDWLDPSnvtySts "LDW LDP Senstitivity status";
CM_ SG_ 1245 FCM_5_LDPONOFFSts "LDP status";
CM_ SG_ 1245 FCM_5_WarnModSts "Warning Mode status";
CM_ SG_ 1245 FCM_5_LDWONOFFSts "LDW status";
CM_ SG_ 1245 FCM_5_TLIONOFFSts "TLI status";
CM_ SG_ 1245 FCM_5_TSIONOFFSts "TSI status";
CM_ SG_ 1245 FCM_5_HMAONOFFSts "HMA status";
CM_ SG_ 1245 FCM_5_IESONOFFSts "IES status";
CM_ SG_ 1245 FCM_5_SLAONOFFSts "SLA ON/OFF status";
CM_ SG_ 1245 FCM_5_TJAICAExitTextInfoSts "TJAICA Exit Text Information status";
CM_ BO_ 775 "Source network message is \"Cyclic, 20ms\".
If no messages are received on source network, no messages are sent on the destination network.";
CM_ SG_ 775 FCM_2_SLASpdlimitUnits "SLA Speed limit Units";
CM_ SG_ 775 LDW_ELK_TJA_LDPRightVisuali "LDW_ELK_TJA_LDP Right Visualization";
CM_ SG_ 775 LDW_ELK_TJA_LDPLeftVisuali "LDW_ELK_TJA_LDP Left Visualization";
CM_ BO_ 896 "Source network message is \"Cyclic, 100ms\".
If no messages are received on source network, no messages are sent on the destination network.";
CM_ SG_ 896 EPS_AssistanceStyle_Sts "0x0: sport
0x1: comfort
0x3: normal (reserved)
0x4: Reserved";
CM_ BO_ 1240 "Source network message is \"Cyclic, 100ms\".
If no messages are received on source network, no messages are sent on the destination network.";
CM_ SG_ 1240 EMS_BoostP "boost pressure";
CM_ BO_ 1057 "Source network message is \"Cyclic, 100ms\".
If no messages are received on source network, no messages are sent on the destination network.";
CM_ SG_ 1057 GasPedalPosition "Driver/Cruise control
This signal including compositive informations which are actual gas pedal position and dummy Cruise control gas pedal position";
CM_ BO_ 640 "Source network message is \"Cyclic, 100ms\".
If no messages are received on source network, no messages are sent on the destination network.";
CM_ SG_ 640 EngineSts "PHEV??，???????????????????";
CM_ SG_ 640 SSMStatus "??????????????????
0-Reset Start/Stop not active(any engine condition possible)
??????
1-StandbyS/S active, engine off(waiting for initial keybutton start)
?????!dou!?????????翪??
2- StoppedS/S active, engine standstill
3- Starter RestartSS/ active starter engine is turning 
??????????????????
4 - Engine RestartS/S active, engine runs up
?????????????????????????!dou!??????????????????!dou!??????е?0!dou!???????????!dou!??????????????????????????!dou!????????????!dou!???????????????????
5 - OperationS/S active, engine is running
6 - Auto StoppingS/S active, engine is turning but no fuel injection anymore
????ISS????!dou!??????000";
CM_ SG_ 1277 CLM_10_SeRowDispSts "Second Row display Status";
CM_ SG_ 1277 CLM_10_RfgtLkDispSts "Refrigerant Leakage Display Status";
CM_ SG_ 1277 CLM_10_ReRowDispSts "Rear Row display  Status";
CM_ SG_ 1277 CLM_10_ReRowBlowSpdLvlSts "Rear Row Blow speed level Status";
CM_ SG_ 1277 CLM_10_ReRowWorkSts "Rear Row Work  Status";
CM_ SG_ 1277 CLM_10_RmnDispSts "Reminder Display Status";
CM_ SG_ 1277 CLM_10_AQSDispSts "AQS Display Status";
CM_ SG_ 1277 SelfTestResult2 "fault display on DVD with SelfTestActive
????????????????DVD????????!dou!DVD?????????????????SelfTestActive?????";
CM_ SG_ 1277 IntelligentCustomSts "ON:?????????????
OFF!mao!????????????";
CM_ SG_ 1277 CLM_10_SeRowWorkSts "Second Row Working status
??????????";
CM_ SG_ 1277 CLM_10_SeRowBlowSpdLvlDispSts "Second Row Blow speed level display status
??????????λ";
CM_ SG_ 1277 PtcHeatgSts "Ptc Heating Status
ON:??????????????
OFF!mao!?????????????";
CM_ BO_ 1334 "Source network message is \"Cyclic, 500ms\".
If no messages are received on source network, no messages are sent on the destination network.";
CM_ SG_ 1334 FragranCeconsistenceLevelSts "??????????????";
CM_ SG_ 1334 Pos3_FragranceTypesSts "λ??3???????????????:
Type1,Type2 ??Type3?????????????????
Unfilled ???λ??δ??κ?????";
CM_ SG_ 1334 Pos2_FragranceTypesSts "λ??2???????????????:
Type1,Type2 ??Type3?????????????????
Unfilled ???λ??δ??κ?????";
CM_ SG_ 1334 PM2_5AutoRunSetSts "?????????????????????";
CM_ SG_ 1334 PM2_5_Incar_Level "???????PM2.5???????????????????????";
CM_ SG_ 1334 PM2_5_Outcar_Level "???????PM2.5???????????????????????";
CM_ SG_ 1334 FragranceDisplaysts "???????????????";
CM_ SG_ 1334 ACModeCustomSts "????????????????";
CM_ SG_ 1334 FragranceWelcomeModeSts "???????????";
CM_ SG_ 1334 RefreshFunctionSts "?????????????????";
CM_ SG_ 1334 Pos1_FragranceTypesSts "λ??1???????????????:
Type1,Type2 ??Type3?????????????????
Unfilled ???λ??δ??κ?????";
CM_ SG_ 1334 PM2_5AutoRunSts "?????????????，????????????????????????????????
???????????????????????!dou!????????";
CM_ SG_ 1334 FragranceSWSts "????????????";
CM_ SG_ 1334 AutoBltCalllowBlowSpeedSts "???????????????????????";
CM_ SG_ 1334 AutoParkInnerCirculationSts "???????????????????";
CM_ SG_ 1334 PM2_5_IncarSts "PM2.5_IncarSts????PM2.5?????????????，??0X1????????·?????·????";
CM_ SG_ 1334 PM2_5_ExtSts "PM2.5_ExtSts????PM2.5?????????????，??0X1????????·?????·????";
CM_ SG_ 1334 PM2_5_ext "????PM2.5?";
CM_ SG_ 1334 FragranceShortageWarning "?????????????
??????bitλ???????λ???
????!mao!111!dou!??λ??1!dou!???λ??3?????????м?λ??1!dou!???λ??2??????????λ??1!dou!???λ??1??????????????1!dou!??????????!dou!??????";
CM_ SG_ 1334 ION_Function_Sts "???????????????,???????????????：
0x0 ??????????????
0x1 ?????????
0x2 ????????";
CM_ SG_ 1334 PM2_5_incar "????PM2.5?";
CM_ BO_ 1333 "Source network message is \"Cyclic, 100ms\".
If no messages are received on source network, no messages are sent on the destination network.";
CM_ SG_ 1333 AUTODefrostDisplaySts "????????????????，??????????????????(???????????????，??????????????，????????)";
CM_ SG_ 1333 TempKnobRollingCounter "?????/??????????
???!mao!????????????????16!dou!?????????????10000??

?綯????!dou!IPM????RRM???????????";
CM_ SG_ 1333 AUTODefrostForceOpenSts "???????????????????，??????????????????(?????????????，?????????????????????，????????)";
CM_ SG_ 1333 PM2_5Displaysts "?????????DVD，?????????????????????";
CM_ SG_ 1333 PM2_5overproofDisplaySts "????????δ??????????，????PM2.5????????，DVD?????????????????????????";
CM_ SG_ 1333 FiltertchangeDisplaySts "?????о????????DVD?????????????????";
CM_ SG_ 1333 REARInhibitSts "???????????????ж????????";
CM_ SG_ 1333 AUTODefrostOnSts "???????????????";
CM_ BO_ 1306 "Source network message is \"Cyclic, 100ms\".
If no messages are received on source network, no messages are sent on the destination network.";
CM_ SG_ 1306 SelfTestResult "????????????????DVD????????，DVD?????????????????SelfTestActive?????";
CM_ SG_ 1306 TemperatureUnit "???????????Startup??
??????!deg!";
CM_ SG_ 1306 SetTemperature_L_C "?????????，????????????????趨?????????????趨???????????，??????趨???????，??????趨????????
DVDδ????趨????!dou!???????趨????startup ?????1F?!dou!DVD???????????????????????";
CM_ SG_ 1306 BlowDelayOffSts "DelayOff：??????????
Not DelayOff!mao!??????????????";
CM_ SG_ 1306 BlowAdvanceOnSts "AdvanceOn：???????????
Not AdvanceOn!mao!???????????????";
CM_ SG_ 1306 DisplayActive "???????????
CLM?????????????DVD????????!dou!????active-1!dou!DVD??????????????????10????м????????????!dou!????? not active-0!dou!DVD?????????????";
CM_ SG_ 1306 SelfTestActive "???????????????????5S????，?????????????Ч???， ????????????????DVD????????5s??，??????????????Ч";
CM_ SG_ 1306 PM2_5Sts "PM2.5??????";
CM_ SG_ 1306 WorkingSts "Not active-?????
Active--?????";
CM_ SG_ 1306 FrontDeforest_MaxDisplaySts "?????????????";
CM_ SG_ 1306 ACRequestDisplaySts "AC??????
?????????????,?????EMS??AC??????????????";
CM_ SG_ 1306 Reserved_AC_MaxSts "MAX AC??????";
CM_ SG_ 1104 OBDDiagnosisReqInd "?????????
1!mao!CGW???Diag CAN????????????1(??????CAN???Diag CAN????????????????)
0!mao!CGW 10s??????Diag CAN????????????0(??????CAN???Diag CAN????????????????)
TBOX!mao!???1???????????????????????";
CM_ BO_ 1178 "Source network message is \"Cyclic, 100ms\".
If no messages are received on source network, no messages are sent on the destination network.";
CM_ SG_ 1178 BDM_26_RRWinPosn "Rear Right Window Position";
CM_ SG_ 1178 BDM_26_RLWinPosn "Rear Left Window Position";
CM_ SG_ 1178 BDM_26_FRWinPosn "Front Right Window Position";
CM_ SG_ 1178 BDM_26_FLWinPosn "Front Left Window Position";
CM_ SG_ 1007 BDM_25_AmbBrightness "?????";
CM_ SG_ 1007 BDM_25_FWBrightness "????";
CM_ BO_ 1287 "Source network message is \"Cyclic, 100ms\".
If no messages are received on source network, no messages are sent on the destination network.";
CM_ SG_ 1287 BCM_22_WiprSnvtySetFb "Wiper Sensitivity Set feedback";
CM_ SG_ 1287 PassSeatMsg_ModeSts "0x0:????
0x1:??????
0x2:è????
0x3:??????
0x4:?滺??
0x5:?????";
CM_ BO_ 746 "Source network message is \"Cyclic, 20ms\".
If no messages are received on source network, no messages are sent on the destination network.";
CM_ SG_ 746 BDM_OTAPwrOnReqFb "OTA Power On Request FeedBack";
CM_ SG_ 746 BDM_OTAPwrDwnReqFb "OTA Power Down Request FeedBack";
CM_ SG_ 746 BDM_OTAModStsFb "Mode Status FeedBack";
CM_ SG_ 746 SlaveVehMod "?????????????";
CM_ SG_ 746 VehPwrMod "?????????";
CM_ SG_ 901 CTP_VolStepValForDVD "Volume Step Value For DVD of Roller";
CM_ SG_ 901 CTP_VolPlusMinusForDVDSts "Volume Plus Minus For DVD Status of Roller";
CM_ SG_ 901 CTP_HomeKeyForIHUSts "DVD???????";
CM_ SG_ 901 CTP_PowerKeyForIHUSts "DVD???????
??e??????????д????e????!dou!??????0x0";
CM_ SG_ 901 CTP_TrackMod "track mode
???????!dou!??3?? Active!dou!????? Not Active";
CM_ SG_ 901 CTP_NavKeyForIHUSts "CTP_NavigationKeyForIHUSts
???????!dou!??3?? Active!dou!????? Not Active
????????!dou!???????????";
CM_ BO_ 936 "Source network message is \"Cyclic, 100ms\".
If no messages are received on source network, no messages are sent on the destination network.";
CM_ SG_ 936 IBS_SOH "The maximum possible amount of a fully charged battery (aged), relative to the nominal battery capacity; 101-254 reserved.Invalid Raw Value:255.";
CM_ SG_ 936 IBS_SOC "Battery state of charge calculated from IBS; 101-254 reserved;Invalid Raw Value:255.";
CM_ BO_ 934 "Source network message is \"Cyclic, 100ms\".
If no messages are received on source network, no messages are sent on the destination network.";
CM_ SG_ 934 IBS_Current "Current measured battery current.
Initial value:
65535/1024-32,
65535/128-256,
65535/16-2048.
Factor:
1/1024,
1/128,
1/16.
Offset:
-32,
-256,
-2048.
Minimum:
-1,
-200,
-1500.
Maximum:
1,
200,
1500.";
CM_ SG_ 934 IBS_Voltage "Current measured battery voltage, max value is 18V.Invalid Raw Value:16383.";
CM_ BO_ 1063 "Source network message is \"Cyclic, 100ms\".
If no messages are received on source network, no messages are sent on the destination network.";
CM_ SG_ 1063 TheaterDimmingColorFeedback_64 "64???Χ???????????";
CM_ SG_ 1063 HUDBriUnit "HUD brightness unit.
In case brightness <= 120lux, the HUDBrightnessUnit=0x0 ; in case the brightness > 120lux andbrightness<= 1200lux, the HUDBrightnessUnit=0x1; 
in case thbrightness > 1200lux and brightness<= 12000lux, theHUDBrightnessUnit=0x2;
otherwise the HUDBrightnessUnit=0x3.";
CM_ SG_ 1063 HUDBriRawVal "HUDBrightnessRawValue
HUD brightness automatic adjustment raw value for HUD.
0x7F:Invalid. HUDbrightness=HUDBrightnessRawValue*HUDBrightnessUnit";
CM_ BO_ 1077 "Source network message is \"Cyclic, 100ms\".
If no messages are received on source network, no messages are sent on the destination network.";
CM_ SG_ 1077 RvsExtMirrFbSts "?????????????·???????";
CM_ SG_ 1077 SRF_Hall2SensorError "HALL2??????????";
CM_ SG_ 1077 SRF_Hall1SensorError "HALL1??????????";
CM_ SG_ 1077 SRF_SunroofOverVolt "?????????";
CM_ SG_ 1077 SRF_SunroofUnderVolt "???????????";
CM_ SG_ 1077 SRF_LINCommunicationERROR "LIN??????";
CM_ SG_ 1077 SRF_SwitchError "??????";
CM_ SG_ 1077 SRF_OverHeatProtect "?????????????";
CM_ SG_ 1077 SRF_MotorRelayError "????????????";
CM_ SG_ 1077 AssociatedWithDriverModeFeedback "Associated With Driver Mode Feedback";
CM_ SG_ 1077 TheaterDimmingBrightnessFeedback "Theater Dimming Brightness Feedback";
CM_ SG_ 1077 TheaterDimmingColorFeedback "Theater Dimming Color Feedback";
CM_ SG_ 1077 SRF_Sunshade_OperateSts "???????????";
CM_ SG_ 1077 RRWindowSts "??????：
???????????????????6????!mao!comfort!dou!close ,open ,stop , closing , opening!dou!????????!dun!???!dun!???!dun!???!dun!???????к????????С?
???APP???startup???????????????????";
CM_ SG_ 1077 RLWindowSts "??????：
???????????????????6????!mao!comfort!dou!close ,open ,stop , closing , opening!dou!????????!dun!???!dun!???!dun!???!dun!???????к????????С?
???APP???startup???????????????????";
CM_ SG_ 1077 WindowInhibitSts "?????????";
CM_ SG_ 1077 FRWindow_Sts "??????：
???????????????????6????!mao!comfort!dou!close ,open ,stop , closing , opening!dou!????????!dun!???!dun!???!dun!???!dun!???????к????????С?
???APP???startup???????????????????";
CM_ SG_ 1077 FLWindow_Sts "??????：
???????????????????6????!mao!comfort!dou!close ,open ,stop , closing , opening!dou!????????!dun!???!dun!???!dun!???!dun!???????к????????С?
???APP???startup???????????????????";
CM_ SG_ 1077 Window_OperateSts "??????：
Window_OperateSts????2????!mao!active ,not active !dou!???????ж????????ж???";
CM_ SG_ 1077 Reserved_SRF_Error "?????????????????????，??0x0?????????????????????";
CM_ SG_ 1077 SRF_InitStatus "?????????λ";
CM_ SG_ 1077 AssociatedWithMusicModeFeedback "Associated With Music Mode Feedback";
CM_ SG_ 1077 TheaterDimmingStatusFeedback "Theater Dimming Status Feedback";
CM_ SG_ 1077 SRF_PositionSts "??????λ??
SRF_PostionSts???????????λ??!dou!0??????!dou!100%??????!dou!tilt?????!dou!?????????12????!mao!0!dun!10%!dun!20%......100%!dun!tilt!dou!???????????!dou!???統?????λ???????????!dou!????0-10%???!dou!??????10%!dou!???????.";
CM_ SG_ 1077 SRF_OperateSts "????
SRF_OperateSts??????7????!mao!tilt,close,opening,stop,closing,open, comfort open!mao!?????????!dun!???!dun!????!dun!???!dun!?????!dun!???!dun!???????????.";
CM_ BO_ 1514 "Source network message is \"NoMsgSendType, /\".???????????????
If no messages are received on source network, no messages are sent on the destination network.";
CM_ BO_ 1505 "Source network message is \"NoMsgSendType, /\".???????????????
If no messages are received on source network, no messages are sent on the destination network.";
CM_ BO_ 1307 "Source network message is \"Cyclic, 500ms\".
If no messages are received on source network, no messages are sent on the destination network.";
CM_ SG_ 1307 TireTemperature "?????????，??TyrePosition?????á?";
CM_ SG_ 1307 TirePosition "???????λ???，??TyreTemperature?????????";
CM_ SG_ 1307 TirePositionWarning_RHRTire "???λ?????????，????????、???、???、?????";
CM_ SG_ 1307 TirePositionWarning_LHRTire "???λ?????????，????????、???、???、?????";
CM_ SG_ 1307 TirePositionWarning_RHFTire "?????λ?????????，????????、???、???、?????";
CM_ SG_ 1307 TirePositionWarning_LHFTire "?????λ?????????，????????、???、???、?????";
CM_ SG_ 1307 TirePressureWarningLampSts "??????????，?????、?????????????、?????????????????";
CM_ BO_ 914 "Source network message is \"Cyclic, 20ms\".
If no messages are received on source network, no messages are sent on the destination network.";
CM_ SG_ 914 DRLModeSts "????г????????";
CM_ SG_ 914 HeadlampDelayLightSts "?????????????????????????????????，???????";
CM_ SG_ 914 AutolockSts "?????????????";
CM_ SG_ 914 AutoFoldSts "?????????????";
CM_ SG_ 914 HeadlampHeightFeedbackSts "???????";
CM_ SG_ 914 RemoteLockFeedbackSts "????????";
CM_ SG_ 914 DirectionIndLeft "????????????????1，????????????0.";
CM_ SG_ 914 DirectionIndRight "????????????????1，????????????0.";
CM_ SG_ 914 DrvrDoorUnlckOnlySts "???????????????????";
CM_ SG_ 914 FGHeat_Req_CmdFeedback "??絲??????????";
CM_ SG_ 914 LightDetected "0X0: ??
0x1: ??
?????LIN??????!mao!
????LIN???S_AUTO_LAMP??????????????????CAN??????????
?????LIN??????
BCM?????????????????????CAN??????????
?????????????ж????????????????0";
CM_ SG_ 914 BCM_4_ArmingSts "???????/?????????????
??????0x1,??????0x2
??????/??????? 0x1??0x2??????????0x0";
CM_ BO_ 913 "Source network message is \"Cyclic, 20ms\".
If no messages are received on source network, no messages are sent on the destination network.";
CM_ SG_ 913 AutoHighSpeedRequest "Auto high speed request
???????ε??????";
CM_ SG_ 913 RainDetected "Rain detected
???????????";
CM_ SG_ 913 HazardLightSW "???????????，????Σ???????????????????????，????Σ?????";
CM_ SG_ 1217 ASU_1_SetModsts "Set mode status";
CM_ SG_ 1217 ASU_1_AssocWithDrvrModFB "associate with driver mode feedback";
CM_ BO_ 554 "Source network message is \"Cyclic, 20ms\".
If no messages are received on source network, no messages are sent on the destination network.";
CM_ SG_ 554 APAFailureSts "APA????????";
CM_ SG_ 554 APA_Active "APA?????????";
CM_ SG_ 554 AVM_APA_SystemSts "APA?????????
0x0: ??????????п???APA?????!dou!??????0x0
0x1: standby??
0x2: ?????????
0x3: ??????????
0x4: ?????????????????λ???!dou!??????0x4
0x5: APA????
0x6: APA?ж?
???!mao!APA????????????
BCM???0x3!dun!0x4!dun!0x6???????";
CM_ BO_ 1267 "Source network message is \"Cyclic, 100ms\".
If no messages are received on source network, no messages are sent on the destination network.";
CM_ SG_ 1267 AIPM_2_DriveModeSet "????????λ，??3?ε???，????? Not Active";
CM_ BO_ 1265 "?????????????????????????0
Source network message is \"NoMsgSendType, /\".
If no messages are received on source network, no messages are sent on the destination network.";
CM_ SG_ 1265 PanelKeyVoiceRemindReq "0x0：No action??DVD need not to respond to this signal 
0x1!mao! Request??DVD need to make an audible prompt??
Note!mao!When the panel detects that a button that requires an audible prompt is pressed, the signal is triggered to first send a frame 0x1:Request, and then send a frame 0x0:Not active.";
CM_ BO_ 704 "Source network message is \"Cyclic, 100ms\".
If no messages are received on source network, no messages are sent on the destination network.";
CM_ SG_ 704 ABS_ESP_Checksum "((Byte0+Byte1+ Byte2+Byte3+Byte4+Byte5) AND 0xFF) XOR 0xFF
Note: Details Please refer to specification??Standard Specification for CAN Data Link Layer_v1.1??section 2.3.3";
CM_ SG_ 704 ABS_ESP_MessageCounter "Rolling message counter(the maximum value of Alive counter is 15)
Note: Details Please refer to specification??Standard Specification for CAN Data Link Layer_v1.1??section 2.3.1";
CM_ SG_ 704 ESPSwitchStatus "??1?? means VDC and Engine Traction Control System (PTC) Function and Brake Traction Control System (BTC) Function disabled and Ignit ESP lamp.
0x0!mao!ESP???????
0x1!mao!ESP??????";
CM_ BO_ 932 "Source network message is \"Cyclic, 20ms\".
If no messages are received on source network, no messages are sent on the destination network.";
CM_ SG_ 932 ABSESP_8_Checksum "((Byte0+Byte1+ Byte2+Byte3+Byte4+Byte5+Byte6) AND 0xFF) XOR 0xFF
Note: Details Please refer to specification??Standard Specification for CAN Data Link Layer_v1.1??section 2.3.3";
CM_ SG_ 932 ABSESP_8_MessageCounter "Rolling message counter(the maximum value of Alive counter is 15)
Note: Details Please refer to specification??Standard Specification for CAN Data Link Layer_v1.1??section 2.3.1";
CM_ BO_ 931 "Source network message is \"Cyclic, 20ms\".
If no messages are received on source network, no messages are sent on the destination network.";
CM_ SG_ 931 ABSESP_7_Checksum "((Byte0+Byte1+ Byte2+Byte3+Byte4+Byte5+Byte6) AND 0xFF) XOR 0xFF
Note: Details Please refer to specification??Standard Specification for CAN Data Link Layer_v1.1??section 2.3.3";
CM_ SG_ 931 ABSESP_7_MessageCounter "Rolling message counter(the maximum value of Alive counter is 15)
Note: Details Please refer to specification??Standard Specification for CAN Data Link Layer_v1.1??section 2.3.1";
CM_ BO_ 793 "Source network message is \"Cyclic, 20ms\".
If no messages are received on source network, no messages are sent on the destination network.";
CM_ BO_ 787 "Source network message is \"Cyclic, 20ms\".
If no messages are received on source network, no messages are sent on the destination network.";
CM_ SG_ 787 ABS_ESP_3_AVHSts "Auto Hold??????";
CM_ SG_ 787 ABS_ESP_3_AVHFailSts "AutoHold?????Ч??";
CM_ BO_ 800 "Source network message is \"Cyclic, 500ms\".
If no messages are received on source network, no messages are sent on the destination network.";
CM_ SG_ 800 ABM_1_PABSetSts "ABM_1_PAB Set Status";
CM_ SG_ 1560 WakeupSource_IHU "Wakeup Source
Note: Details Please refer to specification??IF CAN IHU Network Management Specification ??section10.2 and ??IF CAN DMC Network Management Specification ??section10.2";
CM_ SG_ 1560 ECUSPEC_AWAKE_IHU "ECU keeps the network awake for ECU-define reasons for which communication is needed";
CM_ SG_ 1560 DIAGNOSTIC_AWAKE_IHU "ECU needs communication for diagnostic purpose and keeps network awake.";
CM_ SG_ 1560 IGNITION_AWAKE_IHU "ECU can?t release communication because ignition (KL15) is turn on, or KLR is turned on";
CM_ SG_ 1560 NETWORK_AWAKE_IHU "ECU keeps the network awake due to the CAN message received from the network";
CM_ SG_ 1560 ECUSPEC_WAKEUP_IHU "ECU was in ??power off??, ??Bus Sleep??, ??Pre-pare Bus Sleep?? or ??Ready Sleep?? mode or ??awake?? and re-started by ECU specific reason (e.g. pressed Button, timer, etc.)";
CM_ SG_ 1560 NETWORK_WAKEUP_IHU "ECU was in ??Power off??, ??Bus Sleep??, ??Pre-pare Bus Sleep?? or ??Ready Sleep?? Mode and then re-started by a network communication.";
CM_ SG_ 1560 RESET_WAKEUP_IHU "If ECU was already awake, in ??Prepare Bus Sleep?? or ??Ready Sleep?? mode and re-started by an internal or an external reset.";
CM_ SG_ 1560 IGNITION_WAKEUP_IHU "ECU was ??power off?? or ??Bus sleep?? mode and started by ignition switch";
CM_ SG_ 1560 RMR_IHU "If set to 1 to force the network management of all other nodes on the bus into the re-peat message state.";
CM_ SG_ 1560 srcNodeID_IHU "The srcNodeID of IHU is 0x18";
CM_ SG_ 1266 TBOX_SetAVMVeiw "???APP??????AVM???";
CM_ SG_ 1266 TBOX_SetAVMOnReq "???APP??????AVM??????";
CM_ SG_ 1312 TBOX_1_RemDiagSts "Remote Diagnostic Status";
CM_ SG_ 1243 STAT_ADASDisplayPoision "STAT_ADASDisplayPoision";
CM_ SG_ 1243 HUD_1_HUDHiTWarn "?HUD?high?temperature?warning";
CM_ SG_ 1243 STAT_HUDBrightness "STAT_HUDBrightness";
CM_ SG_ 1243 STAT_HUD "STAT_HUD";
CM_ SG_ 1243 STAT_HUDProfileID "STAT_HUDProfileID";
CM_ SG_ 1243 STAT_HUDDisplayMod "STAT_HUDDisplayMod";
CM_ SG_ 1243 STAT_HUDDisplayOnOff "STAT_HUDDisplayOnOff";
CM_ SG_ 1243 STAT_HUDHeight "STAT_HUDHeight";
CM_ BO_ 1140 "Not Active?????????????";
CM_ SG_ 1140 STAT_AMPESEVol "Volume
????,???31??0-31??";
CM_ SG_ 1140 STAT_AMPWelVol "Welcome Volume
??????,???31??0-31??";
CM_ SG_ 1140 STAT_AMPBTMediVol "Media Volume
e????????,???31??0-31??";
CM_ SG_ 1140 STAT_AMPTEMP "Temperature status of power amplifier
?????????";
CM_ SG_ 1140 STAT_AMPMute "????????????????
????????????lin??????????DVD!dou!DVD???CAN????
????";
CM_ SG_ 1140 STAT_AMPSpeedVolume "????????
????????????!mao!???!dun!??!dun!??!dun!??.
?????????????????!dou!??y???????Entertainment???????????????????????????????????????";
CM_ SG_ 1140 EAMP_2_HdrestSpkrMod "Set the headrest speaker mode using the host softkey
???????????????????????????????
0x0!mao!??????
0x1: ??????
0x2: ??????
0x3:?????
0x4:???
0x5:???
0x6:???
0x8:???";
CM_ BO_ 1121 "Not Active?????????????";
CM_ SG_ 1121 STAT_AMPAlarmVolume "??????，?????Χ?1~10";
CM_ SG_ 1121 STAT_AMPLoudness "???：???????????????y???????Entertainment?????，??????????????????????";
CM_ SG_ 1121 STAT_AMPLiveAcoustics "?????Ч?????????
EQ:equalizer";
CM_ SG_ 1121 STAT_AMPSoundFieldFader "???????/???????????Y_axis??";
CM_ SG_ 1121 STAT_AMPSoundFieldBalance "???????/??????????：???????????????????????X_axis??
?????????Χ?-7~+7";
CM_ SG_ 1121 STAT_AMPSoundEffectTreble "??Ч?????????????????????????";
CM_ SG_ 1121 STAT_AMPSoundEffectMidrange "??Ч??????????????????????????";
CM_ SG_ 1121 STAT_AMPSoundEffectBass "??Ч?????????????????????????'-7~+7，";
CM_ SG_ 1121 STAT_AMPSoundEffect "??Ч????
????!mao!?????!dun!???!dun!????!dun!???!dun!???!dun!???!dun!????!dun!???

0x1: Customer-defined mode?????
0x2: Standard mode ?????
0x3: Popular mode ??????
0x4: Jazz mode ?????
0x5: Classic mode ?????
0x6: Rock mode ?????
0x7: Vocals mode??????
0x8: Rural model(?????)";
CM_ SG_ 1121 STAT_AMPRestoreDefaults "??????????，????：????、??Ч、?????????????";
CM_ SG_ 1121 STAT_AMPDefaultVolume "???????????
0~ 31!dou!
?????y???????Entertainment???????????????????????!dou!
? ????????????????????A?!dou!??????y?????????С??A!dou!?????????????????????????????????????????y?????????????A!dou!??????????????????????A";
CM_ SG_ 1121 STAT_AMPSoundFocus "???????
0x1!mao!Customized(???Balance/Fader)
0x2!mao!All(Passenger)
0x3!mao!Driver
0x4!mao!Front
0x5!mao!Rear
0x6!mao!Sleep(Baby Mode)
0x7!mao!VIP(Boss)";
CM_ SG_ 1121 STAT_AMPPhoneVolume "?绰????,?????Χ?0~25";
CM_ SG_ 1121 STAT_AMPMediaVolume "y????,???31??0-31??";
CM_ SG_ 1121 STAT_AMPKeyTone "?????????";
CM_ SG_ 1121 STAT_AMPVRVolume "???????????，0~10，
VR!dou!????!mao!С?????!dou!EAMP?????????????";
CM_ SG_ 1121 STAT_AMPNaviVolume "??????,0~10";
CM_ SG_ 1506 InteractiveDisplayInfo "Refer to ??T15 RRM and ICM Interactive Display Communication Specification??";
BA_DEF_  "NmAsrCanMsgCycleTime" INT 1000 1000;
BA_DEF_  "NmAsrRepeatMessageTime" INT 3000 3000;
BA_DEF_  "NmAsrWaitBusSleepTime" INT 1500 1500;
BA_DEF_  "NmAsrTimeoutTime" INT 2500 2500;
BA_DEF_  "NmAsrBaseAddress" HEX 0 2047;
BA_DEF_  "NmAsrMessageCount" INT 128 128;
BA_DEF_  "NmType" STRING ;
BA_DEF_  "ILTxTimeout" INT 0 65535;
BA_DEF_  "Manufacturer" STRING ;
BA_DEF_ SG_  "GenSigTimeoutValue" INT 0 2147483647;
BA_DEF_ SG_  "GenSigStartValue" INT 0 2147483647;
BA_DEF_ SG_  "GenSigInactiveValue" INT 0 2147483647;
BA_DEF_ BO_  "TpTxIndex" INT 0 255;
BA_DEF_ BO_  "DiagUudtResponse" ENUM  "False","True";
BA_DEF_ BO_  "DiagResponse" ENUM  "No","Yes";
BA_DEF_ BO_  "DiagRequest" ENUM  "No","Yes";
BA_DEF_ BO_  "DiagState" ENUM  "No","Yes";
BA_DEF_ BO_  "NmAsrMessage" ENUM  "No","Yes";
BA_DEF_ BO_  "GenMsgFastOnStart" INT 0 65535;
BA_DEF_ BO_  "GenMsgCycleTimeFast" INT 0 65535;
BA_DEF_ BO_  "GenMsgNrOfRepetition" INT 0 65535;
BA_DEF_ BO_  "GenMsgStartDelayTime" INT 0 65535;
BA_DEF_ BO_  "GenMsgCycleTime" INT 0 65535;
BA_DEF_ BO_  "GenMsgDelayTime" INT 0 65535;
BA_DEF_ SG_  "GenSigSendType" ENUM  "Cyclic","OnWrite","OnWriteWithRepetition","OnChange","OnChangeWithRepetition","IfActive","IfActiveWithRepetition","NoSigSendType","OnChangeAndIfActive","OnChangeAndIfActiveWithRepetition";
BA_DEF_ BO_  "GenMsgSendType" ENUM  "Cyclic","NotUsed","NotUsed","NotUsed","NotUsed","NotUsed","NotUsed","IfActive","NoMsgSendType";
BA_DEF_ BO_  "GenMsgILSupport" ENUM  "No","Yes";
BA_DEF_ BU_  "NmStationAddress" HEX 0 255;
BA_DEF_ BU_  "NmAsrCanMsgReducedTime" INT 500 818;
BA_DEF_ BU_  "NmAsrCanMsgCycleOffset" INT 0 635;
BA_DEF_ BU_  "NmAsrNodeIdentifier" HEX 0 255;
BA_DEF_ BU_  "NmAsrNode" ENUM  "No","Yes";
BA_DEF_ BU_  "ILUsed" ENUM  "No","Yes";
BA_DEF_REL_ BU_SG_REL_  "GenSigTimeoutTime" INT 0 65535;
BA_DEF_DEF_  "NmAsrCanMsgCycleTime" 1000;
BA_DEF_DEF_  "NmAsrRepeatMessageTime" 3000;
BA_DEF_DEF_  "NmAsrWaitBusSleepTime" 1500;
BA_DEF_DEF_  "NmAsrTimeoutTime" 2500;
BA_DEF_DEF_  "NmAsrBaseAddress" 1536;
BA_DEF_DEF_  "NmAsrMessageCount" 128;
BA_DEF_DEF_  "NmType" "NmAsr";
BA_DEF_DEF_  "ILTxTimeout" 0;
BA_DEF_DEF_  "Manufacturer" "Vector";
BA_DEF_DEF_  "GenSigTimeoutValue" 0;
BA_DEF_DEF_  "GenSigStartValue" 0;
BA_DEF_DEF_  "GenSigInactiveValue" 0;
BA_DEF_DEF_  "TpTxIndex" 0;
BA_DEF_DEF_  "DiagUudtResponse" "False";
BA_DEF_DEF_  "DiagResponse" "No";
BA_DEF_DEF_  "DiagRequest" "No";
BA_DEF_DEF_  "DiagState" "No";
BA_DEF_DEF_  "NmAsrMessage" "No";
BA_DEF_DEF_  "GenMsgFastOnStart" 0;
BA_DEF_DEF_  "GenMsgCycleTimeFast" 0;
BA_DEF_DEF_  "GenMsgNrOfRepetition" 3;
BA_DEF_DEF_  "GenMsgStartDelayTime" 0;
BA_DEF_DEF_  "GenMsgCycleTime" 0;
BA_DEF_DEF_  "GenMsgDelayTime" 0;
BA_DEF_DEF_  "GenSigSendType" "NoSigSendType";
BA_DEF_DEF_  "GenMsgSendType" "NoMsgSendType";
BA_DEF_DEF_  "GenMsgILSupport" "No";
BA_DEF_DEF_  "NmStationAddress" 255;
BA_DEF_DEF_  "NmAsrCanMsgReducedTime" 575;
BA_DEF_DEF_  "NmAsrCanMsgCycleOffset" 0;
BA_DEF_DEF_  "NmAsrNodeIdentifier" 255;
BA_DEF_DEF_  "NmAsrNode" "No";
BA_DEF_DEF_  "ILUsed" "No";
BA_DEF_DEF_REL_ "GenSigTimeoutTime" 0;
BA_ "NmStationAddress" BU_ IHU 24;
BA_ "NmAsrNodeIdentifier" BU_ IHU 24;
BA_ "NmAsrNode" BU_ IHU 1;
BA_ "ILUsed" BU_ IHU 1;
BA_ "GenMsgNrOfRepetition" BO_ 1538 0;
BA_ "NmAsrMessage" BO_ 1538 1;
BA_ "GenMsgSendType" BO_ 1538 0;
BA_ "GenMsgCycleTime" BO_ 1538 1000;
BA_ "GenMsgILSupport" BO_ 1538 1;
BA_ "DiagState" BO_ 2015 1;
BA_ "GenMsgNrOfRepetition" BO_ 2015 0;
BA_ "DiagRequest" BO_ 1866 1;
BA_ "GenMsgNrOfRepetition" BO_ 1866 0;
BA_ "GenMsgILSupport" BO_ 928 1;
BA_ "GenMsgSendType" BO_ 928 0;
BA_ "GenMsgNrOfRepetition" BO_ 928 0;
BA_ "GenMsgCycleTime" BO_ 928 20;
BA_ "GenMsgILSupport" BO_ 926 1;
BA_ "GenMsgSendType" BO_ 926 0;
BA_ "GenMsgNrOfRepetition" BO_ 926 0;
BA_ "GenMsgCycleTime" BO_ 926 20;
BA_ "GenMsgILSupport" BO_ 769 1;
BA_ "GenMsgSendType" BO_ 769 0;
BA_ "GenMsgNrOfRepetition" BO_ 769 0;
BA_ "GenMsgCycleTime" BO_ 769 100;
BA_ "GenMsgILSupport" BO_ 1206 1;
BA_ "GenMsgSendType" BO_ 1206 0;
BA_ "GenMsgNrOfRepetition" BO_ 1206 0;
BA_ "GenMsgCycleTime" BO_ 1206 100;
BA_ "GenMsgILSupport" BO_ 1202 1;
BA_ "GenMsgSendType" BO_ 1202 0;
BA_ "GenMsgNrOfRepetition" BO_ 1202 0;
BA_ "GenMsgCycleTime" BO_ 1202 100;
BA_ "GenMsgILSupport" BO_ 1194 1;
BA_ "GenMsgSendType" BO_ 1194 0;
BA_ "GenMsgNrOfRepetition" BO_ 1194 0;
BA_ "GenMsgCycleTime" BO_ 1194 100;
BA_ "GenMsgILSupport" BO_ 1190 1;
BA_ "GenMsgSendType" BO_ 1190 0;
BA_ "GenMsgNrOfRepetition" BO_ 1190 0;
BA_ "GenMsgCycleTime" BO_ 1190 100;
BA_ "GenMsgILSupport" BO_ 1186 1;
BA_ "GenMsgSendType" BO_ 1186 0;
BA_ "GenMsgNrOfRepetition" BO_ 1186 0;
BA_ "GenMsgCycleTime" BO_ 1186 100;
BA_ "GenMsgILSupport" BO_ 1170 1;
BA_ "GenMsgSendType" BO_ 1170 0;
BA_ "GenMsgNrOfRepetition" BO_ 1170 0;
BA_ "GenMsgCycleTime" BO_ 1170 100;
BA_ "GenMsgILSupport" BO_ 1090 1;
BA_ "GenMsgSendType" BO_ 1090 0;
BA_ "GenMsgNrOfRepetition" BO_ 1090 0;
BA_ "GenMsgCycleTime" BO_ 1090 100;
BA_ "GenMsgILSupport" BO_ 924 1;
BA_ "GenMsgSendType" BO_ 924 0;
BA_ "GenMsgNrOfRepetition" BO_ 924 0;
BA_ "GenMsgCycleTime" BO_ 924 10;
BA_ "GenMsgILSupport" BO_ 1203 1;
BA_ "GenMsgSendType" BO_ 1203 0;
BA_ "GenMsgNrOfRepetition" BO_ 1203 0;
BA_ "GenMsgCycleTime" BO_ 1203 100;
BA_ "GenMsgILSupport" BO_ 498 1;
BA_ "GenMsgSendType" BO_ 498 0;
BA_ "GenMsgNrOfRepetition" BO_ 498 0;
BA_ "GenMsgCycleTime" BO_ 498 10;
BA_ "GenMsgILSupport" BO_ 1201 1;
BA_ "GenMsgSendType" BO_ 1201 0;
BA_ "GenMsgNrOfRepetition" BO_ 1201 0;
BA_ "GenMsgCycleTime" BO_ 1201 100;
BA_ "GenMsgILSupport" BO_ 1141 1;
BA_ "GenMsgSendType" BO_ 1141 0;
BA_ "GenMsgNrOfRepetition" BO_ 1141 0;
BA_ "GenMsgCycleTime" BO_ 1141 100;
BA_ "GenMsgILSupport" BO_ 1088 1;
BA_ "GenMsgSendType" BO_ 1088 0;
BA_ "GenMsgNrOfRepetition" BO_ 1088 0;
BA_ "GenMsgCycleTime" BO_ 1088 100;
BA_ "GenMsgILSupport" BO_ 1078 1;
BA_ "GenMsgSendType" BO_ 1078 0;
BA_ "GenMsgNrOfRepetition" BO_ 1078 0;
BA_ "GenMsgCycleTime" BO_ 1078 100;
BA_ "GenMsgILSupport" BO_ 1042 1;
BA_ "GenMsgSendType" BO_ 1042 0;
BA_ "GenMsgNrOfRepetition" BO_ 1042 0;
BA_ "GenMsgCycleTime" BO_ 1042 100;
BA_ "GenMsgILSupport" BO_ 998 1;
BA_ "GenMsgSendType" BO_ 998 0;
BA_ "GenMsgNrOfRepetition" BO_ 998 0;
BA_ "GenMsgCycleTime" BO_ 998 50;
BA_ "GenMsgILSupport" BO_ 1124 1;
BA_ "GenMsgSendType" BO_ 1124 0;
BA_ "GenMsgNrOfRepetition" BO_ 1124 0;
BA_ "GenMsgCycleTime" BO_ 1124 100;
BA_ "GenMsgILSupport" BO_ 864 1;
BA_ "GenMsgNrOfRepetition" BO_ 864 0;
BA_ "GenMsgDelayTime" BO_ 864 5;
BA_ "GenMsgILSupport" BO_ 945 1;
BA_ "GenMsgNrOfRepetition" BO_ 945 0;
BA_ "GenMsgDelayTime" BO_ 945 5;
BA_ "GenMsgILSupport" BO_ 1218 1;
BA_ "GenMsgSendType" BO_ 1218 0;
BA_ "GenMsgNrOfRepetition" BO_ 1218 0;
BA_ "GenMsgCycleTime" BO_ 1218 100;
BA_ "GenMsgILSupport" BO_ 1059 1;
BA_ "GenMsgSendType" BO_ 1059 0;
BA_ "GenMsgNrOfRepetition" BO_ 1059 0;
BA_ "GenMsgCycleTime" BO_ 1059 100;
BA_ "GenMsgILSupport" BO_ 1175 1;
BA_ "GenMsgSendType" BO_ 1175 0;
BA_ "GenMsgNrOfRepetition" BO_ 1175 0;
BA_ "GenMsgCycleTime" BO_ 1175 100;
BA_ "GenMsgILSupport" BO_ 1149 1;
BA_ "GenMsgNrOfRepetition" BO_ 1149 0;
BA_ "GenMsgILSupport" BO_ 1110 1;
BA_ "GenMsgNrOfRepetition" BO_ 1110 0;
BA_ "GenMsgILSupport" BO_ 1508 1;
BA_ "GenMsgNrOfRepetition" BO_ 1508 0;
BA_ "GenMsgILSupport" BO_ 906 1;
BA_ "GenMsgSendType" BO_ 906 0;
BA_ "GenMsgNrOfRepetition" BO_ 906 0;
BA_ "GenMsgCycleTime" BO_ 906 100;
BA_ "GenMsgILSupport" BO_ 1248 1;
BA_ "GenMsgSendType" BO_ 1248 0;
BA_ "GenMsgNrOfRepetition" BO_ 1248 0;
BA_ "GenMsgCycleTime" BO_ 1248 100;
BA_ "GenMsgILSupport" BO_ 533 1;
BA_ "GenMsgDelayTime" BO_ 533 5;
BA_ "GenMsgCycleTimeFast" BO_ 533 100;
BA_ "GenMsgILSupport" BO_ 647 1;
BA_ "GenMsgSendType" BO_ 647 0;
BA_ "GenMsgNrOfRepetition" BO_ 647 0;
BA_ "GenMsgCycleTime" BO_ 647 20;
BA_ "GenMsgILSupport" BO_ 1107 1;
BA_ "GenMsgSendType" BO_ 1107 0;
BA_ "GenMsgNrOfRepetition" BO_ 1107 0;
BA_ "GenMsgCycleTime" BO_ 1107 500;
BA_ "GenMsgILSupport" BO_ 1106 1;
BA_ "GenMsgSendType" BO_ 1106 0;
BA_ "GenMsgNrOfRepetition" BO_ 1106 0;
BA_ "GenMsgCycleTime" BO_ 1106 100;
BA_ "GenMsgILSupport" BO_ 1072 1;
BA_ "GenMsgSendType" BO_ 1072 0;
BA_ "GenMsgNrOfRepetition" BO_ 1072 0;
BA_ "GenMsgCycleTime" BO_ 1072 20;
BA_ "GenMsgILSupport" BO_ 903 1;
BA_ "GenMsgSendType" BO_ 903 0;
BA_ "GenMsgNrOfRepetition" BO_ 903 0;
BA_ "GenMsgCycleTime" BO_ 903 50;
BA_ "GenMsgILSupport" BO_ 1251 1;
BA_ "GenMsgSendType" BO_ 1251 0;
BA_ "GenMsgNrOfRepetition" BO_ 1251 0;
BA_ "GenMsgCycleTime" BO_ 1251 100;
BA_ "GenMsgILSupport" BO_ 1020 1;
BA_ "GenMsgSendType" BO_ 1020 0;
BA_ "GenMsgNrOfRepetition" BO_ 1020 0;
BA_ "GenMsgCycleTime" BO_ 1020 50;
BA_ "GenMsgILSupport" BO_ 1245 1;
BA_ "GenMsgSendType" BO_ 1245 0;
BA_ "GenMsgNrOfRepetition" BO_ 1245 0;
BA_ "GenMsgCycleTime" BO_ 1245 100;
BA_ "GenMsgILSupport" BO_ 775 1;
BA_ "GenMsgSendType" BO_ 775 0;
BA_ "GenMsgNrOfRepetition" BO_ 775 0;
BA_ "GenMsgCycleTime" BO_ 775 50;
BA_ "GenMsgILSupport" BO_ 896 1;
BA_ "GenMsgSendType" BO_ 896 0;
BA_ "GenMsgNrOfRepetition" BO_ 896 0;
BA_ "GenMsgCycleTime" BO_ 896 100;
BA_ "GenMsgILSupport" BO_ 1240 1;
BA_ "GenMsgSendType" BO_ 1240 0;
BA_ "GenMsgNrOfRepetition" BO_ 1240 0;
BA_ "GenMsgCycleTime" BO_ 1240 100;
BA_ "GenMsgILSupport" BO_ 1057 1;
BA_ "GenMsgSendType" BO_ 1057 0;
BA_ "GenMsgNrOfRepetition" BO_ 1057 0;
BA_ "GenMsgCycleTime" BO_ 1057 100;
BA_ "GenMsgILSupport" BO_ 640 1;
BA_ "GenMsgSendType" BO_ 640 0;
BA_ "GenMsgNrOfRepetition" BO_ 640 0;
BA_ "GenMsgCycleTime" BO_ 640 100;
BA_ "GenMsgILSupport" BO_ 1277 1;
BA_ "GenMsgSendType" BO_ 1277 0;
BA_ "GenMsgNrOfRepetition" BO_ 1277 0;
BA_ "GenMsgDelayTime" BO_ 1277 5;
BA_ "GenMsgCycleTime" BO_ 1277 100;
BA_ "GenMsgILSupport" BO_ 1334 1;
BA_ "GenMsgSendType" BO_ 1334 0;
BA_ "GenMsgNrOfRepetition" BO_ 1334 0;
BA_ "GenMsgCycleTime" BO_ 1334 500;
BA_ "GenMsgILSupport" BO_ 1333 1;
BA_ "GenMsgSendType" BO_ 1333 0;
BA_ "GenMsgNrOfRepetition" BO_ 1333 0;
BA_ "GenMsgCycleTime" BO_ 1333 100;
BA_ "GenMsgILSupport" BO_ 1306 1;
BA_ "GenMsgSendType" BO_ 1306 0;
BA_ "GenMsgNrOfRepetition" BO_ 1306 0;
BA_ "GenMsgDelayTime" BO_ 1306 5;
BA_ "GenMsgCycleTime" BO_ 1306 100;
BA_ "GenMsgILSupport" BO_ 1104 1;
BA_ "GenMsgSendType" BO_ 1104 0;
BA_ "GenMsgNrOfRepetition" BO_ 1104 0;
BA_ "GenMsgCycleTime" BO_ 1104 100;
BA_ "GenMsgILSupport" BO_ 1178 1;
BA_ "GenMsgSendType" BO_ 1178 0;
BA_ "GenMsgNrOfRepetition" BO_ 1178 0;
BA_ "GenMsgCycleTime" BO_ 1178 100;
BA_ "GenMsgILSupport" BO_ 1007 1;
BA_ "GenMsgSendType" BO_ 1007 0;
BA_ "GenMsgNrOfRepetition" BO_ 1007 0;
BA_ "GenMsgCycleTime" BO_ 1007 100;
BA_ "GenMsgILSupport" BO_ 1287 1;
BA_ "GenMsgSendType" BO_ 1287 0;
BA_ "GenMsgNrOfRepetition" BO_ 1287 0;
BA_ "GenMsgCycleTime" BO_ 1287 100;
BA_ "GenMsgILSupport" BO_ 746 1;
BA_ "GenMsgSendType" BO_ 746 0;
BA_ "GenMsgNrOfRepetition" BO_ 746 0;
BA_ "GenMsgCycleTime" BO_ 746 20;
BA_ "GenMsgILSupport" BO_ 901 1;
BA_ "GenMsgSendType" BO_ 901 0;
BA_ "GenMsgNrOfRepetition" BO_ 901 0;
BA_ "GenMsgCycleTime" BO_ 901 50;
BA_ "GenMsgILSupport" BO_ 936 1;
BA_ "GenMsgSendType" BO_ 936 0;
BA_ "GenMsgNrOfRepetition" BO_ 936 0;
BA_ "GenMsgCycleTime" BO_ 936 100;
BA_ "GenMsgILSupport" BO_ 934 1;
BA_ "GenMsgSendType" BO_ 934 0;
BA_ "GenMsgNrOfRepetition" BO_ 934 0;
BA_ "GenMsgCycleTime" BO_ 934 100;
BA_ "GenMsgILSupport" BO_ 1063 1;
BA_ "GenMsgSendType" BO_ 1063 0;
BA_ "GenMsgNrOfRepetition" BO_ 1063 0;
BA_ "GenMsgCycleTime" BO_ 1063 100;
BA_ "GenMsgILSupport" BO_ 1077 1;
BA_ "GenMsgSendType" BO_ 1077 0;
BA_ "GenMsgNrOfRepetition" BO_ 1077 0;
BA_ "GenMsgCycleTime" BO_ 1077 100;
BA_ "GenMsgILSupport" BO_ 1514 1;
BA_ "GenMsgNrOfRepetition" BO_ 1514 0;
BA_ "GenMsgCycleTimeFast" BO_ 1514 1000;
BA_ "GenMsgILSupport" BO_ 1505 1;
BA_ "GenMsgNrOfRepetition" BO_ 1505 0;
BA_ "GenMsgCycleTimeFast" BO_ 1505 1000;
BA_ "GenMsgILSupport" BO_ 1307 1;
BA_ "GenMsgSendType" BO_ 1307 0;
BA_ "GenMsgNrOfRepetition" BO_ 1307 0;
BA_ "GenMsgCycleTime" BO_ 1307 500;
BA_ "GenMsgILSupport" BO_ 914 1;
BA_ "GenMsgSendType" BO_ 914 0;
BA_ "GenMsgNrOfRepetition" BO_ 914 0;
BA_ "GenMsgCycleTime" BO_ 914 20;
BA_ "GenMsgILSupport" BO_ 913 1;
BA_ "GenMsgSendType" BO_ 913 0;
BA_ "GenMsgNrOfRepetition" BO_ 913 0;
BA_ "GenMsgCycleTime" BO_ 913 20;
BA_ "GenMsgILSupport" BO_ 1217 1;
BA_ "GenMsgSendType" BO_ 1217 0;
BA_ "GenMsgNrOfRepetition" BO_ 1217 0;
BA_ "GenMsgCycleTime" BO_ 1217 100;
BA_ "GenMsgILSupport" BO_ 554 1;
BA_ "GenMsgSendType" BO_ 554 0;
BA_ "GenMsgNrOfRepetition" BO_ 554 0;
BA_ "GenMsgCycleTime" BO_ 554 20;
BA_ "GenMsgILSupport" BO_ 1267 1;
BA_ "GenMsgSendType" BO_ 1267 0;
BA_ "GenMsgNrOfRepetition" BO_ 1267 0;
BA_ "GenMsgCycleTime" BO_ 1267 100;
BA_ "GenMsgILSupport" BO_ 1265 1;
BA_ "GenMsgNrOfRepetition" BO_ 1265 0;
BA_ "GenMsgDelayTime" BO_ 1265 5;
BA_ "GenMsgILSupport" BO_ 704 1;
BA_ "GenMsgSendType" BO_ 704 0;
BA_ "GenMsgNrOfRepetition" BO_ 704 0;
BA_ "GenMsgCycleTime" BO_ 704 100;
BA_ "GenMsgILSupport" BO_ 932 1;
BA_ "GenMsgSendType" BO_ 932 0;
BA_ "GenMsgNrOfRepetition" BO_ 932 0;
BA_ "GenMsgCycleTime" BO_ 932 20;
BA_ "GenMsgILSupport" BO_ 931 1;
BA_ "GenMsgSendType" BO_ 931 0;
BA_ "GenMsgNrOfRepetition" BO_ 931 0;
BA_ "GenMsgCycleTime" BO_ 931 20;
BA_ "GenMsgILSupport" BO_ 793 1;
BA_ "GenMsgSendType" BO_ 793 0;
BA_ "GenMsgNrOfRepetition" BO_ 793 0;
BA_ "GenMsgCycleTime" BO_ 793 20;
BA_ "GenMsgILSupport" BO_ 787 1;
BA_ "GenMsgSendType" BO_ 787 0;
BA_ "GenMsgNrOfRepetition" BO_ 787 0;
BA_ "GenMsgCycleTime" BO_ 787 20;
BA_ "GenMsgILSupport" BO_ 800 1;
BA_ "GenMsgSendType" BO_ 800 0;
BA_ "GenMsgNrOfRepetition" BO_ 800 6;
BA_ "GenMsgDelayTime" BO_ 800 5;
BA_ "GenMsgCycleTimeFast" BO_ 800 20;
BA_ "GenMsgCycleTime" BO_ 800 500;
BA_ "DiagResponse" BO_ 1882 1;
BA_ "GenMsgNrOfRepetition" BO_ 1882 0;
BA_ "DiagResponse" BO_ 1942 1;
BA_ "GenMsgNrOfRepetition" BO_ 1942 0;
BA_ "DiagRequest" BO_ 1926 1;
BA_ "GenMsgNrOfRepetition" BO_ 1926 0;
BA_ "NmAsrMessage" BO_ 1560 1;
BA_ "GenMsgSendType" BO_ 1560 0;
BA_ "GenMsgNrOfRepetition" BO_ 1560 0;
BA_ "GenMsgCycleTime" BO_ 1560 1000;
BA_ "GenMsgILSupport" BO_ 1266 1;
BA_ "GenMsgDelayTime" BO_ 1266 5;
BA_ "GenMsgCycleTimeFast" BO_ 1266 100;
BA_ "GenMsgILSupport" BO_ 1312 1;
BA_ "GenMsgSendType" BO_ 1312 0;
BA_ "GenMsgNrOfRepetition" BO_ 1312 0;
BA_ "GenMsgCycleTime" BO_ 1312 50;
BA_ "GenMsgILSupport" BO_ 1243 1;
BA_ "GenMsgSendType" BO_ 1243 0;
BA_ "GenMsgNrOfRepetition" BO_ 1243 0;
BA_ "GenMsgCycleTime" BO_ 1243 100;
BA_ "GenMsgILSupport" BO_ 1140 1;
BA_ "GenMsgSendType" BO_ 1140 0;
BA_ "GenMsgNrOfRepetition" BO_ 1140 0;
BA_ "GenMsgCycleTime" BO_ 1140 100;
BA_ "GenMsgILSupport" BO_ 1121 1;
BA_ "GenMsgSendType" BO_ 1121 0;
BA_ "GenMsgNrOfRepetition" BO_ 1121 0;
BA_ "GenMsgCycleTime" BO_ 1121 100;
BA_ "GenMsgILSupport" BO_ 1517 1;
BA_ "GenMsgNrOfRepetition" BO_ 1517 0;
BA_ "GenMsgILSupport" BO_ 1515 1;
BA_ "GenMsgNrOfRepetition" BO_ 1515 0;
BA_ "GenMsgILSupport" BO_ 1298 1;
BA_ "GenMsgNrOfRepetition" BO_ 1298 0;
BA_ "GenMsgILSupport" BO_ 1289 1;
BA_ "GenMsgNrOfRepetition" BO_ 1289 0;
BA_ "GenMsgILSupport" BO_ 759 1;
BA_ "GenMsgNrOfRepetition" BO_ 759 0;
BA_ "GenMsgILSupport" BO_ 755 1;
BA_ "GenMsgNrOfRepetition" BO_ 755 0;
BA_ "GenMsgILSupport" BO_ 1506 1;
BA_ "GenMsgNrOfRepetition" BO_ 1506 0;
BA_ "GenMsgILSupport" BO_ 1151 1;
BA_ "GenMsgNrOfRepetition" BO_ 1151 0;
BA_ "GenMsgDelayTime" BO_ 1151 5;
BA_ "GenMsgILSupport" BO_ 1116 1;
BA_ "GenMsgNrOfRepetition" BO_ 1116 0;
BA_ "GenSigSendType" SG_ 1538 NM_User_RxSignal_01 0;
BA_ "GenSigSendType" SG_ 2015 DIAG_OBD_REQ_Broadcast 1;
BA_ "GenSigSendType" SG_ 1866 Diag_IHU_REQ 1;
BA_ "GenSigSendType" SG_ 928 YAS_2_Checksum 0;
BA_ "GenSigSendType" SG_ 928 LongitudinalAcceleration 0;
BA_ "GenSigSendType" SG_ 928 LongitudinalAccelerationSigValid 0;
BA_ "GenSigStartValue" SG_ 928 LongitudinalAccelerationSigValid 3;
BA_ "GenSigSendType" SG_ 928 YAS_2_MessageCounter 0;
BA_ "GenSigSendType" SG_ 926 YAS_1_Checksum 0;
BA_ "GenSigSendType" SG_ 926 YawRate 0;
BA_ "GenSigSendType" SG_ 926 YawrateSigValidData 0;
BA_ "GenSigStartValue" SG_ 926 YawrateSigValidData 3;
BA_ "GenSigSendType" SG_ 926 YAS_1_MessageCounter 0;
BA_ "GenSigSendType" SG_ 769 GBPositoionDisplay 0;
BA_ "GenSigSendType" SG_ 1206 SHU2R_RSeatVentnSts 0;
BA_ "GenSigSendType" SG_ 1206 SHU2R_RSeatHeatSts 0;
BA_ "GenSigSendType" SG_ 1202 SHU2M_MSeatVentnSts 0;
BA_ "GenSigSendType" SG_ 1202 SHU2M_MSeatHeatSts 0;
BA_ "GenSigSendType" SG_ 1194 SHU2L_LSeatVentnSts 0;
BA_ "GenSigSendType" SG_ 1194 SHU2L_LSeatHeatSts 0;
BA_ "GenSigSendType" SG_ 1190 SHU1R_RSeatAutVentnSts 0;
BA_ "GenSigSendType" SG_ 1190 SHU1R_RSeatAutHeatSts 0;
BA_ "GenSigSendType" SG_ 1190 SHU1R_RSeatVentnSts 0;
BA_ "GenSigSendType" SG_ 1190 SHU1R_RSeatHeatSts 0;
BA_ "GenSigSendType" SG_ 1186 SHU1L_LSeatAutVentnSts 0;
BA_ "GenSigSendType" SG_ 1186 SHU1L_LSeatAutHeatSts 0;
BA_ "GenSigSendType" SG_ 1186 SHU1L_LSeatVentnSts 0;
BA_ "GenSigSendType" SG_ 1186 SHU1L_LSeatHeatSts 0;
BA_ "GenSigSendType" SG_ 1170 SCU_2_CRC 0;
BA_ "GenSigSendType" SG_ 1170 SCU_2_MessageCounter 0;
BA_ "GenSigSendType" SG_ 1170 SCU_2_SeatLegSpprtPosnStsTar 0;
BA_ "GenSigSendType" SG_ 1170 SCU_2_SeatLvlPosnStsTar 0;
BA_ "GenSigSendType" SG_ 1170 SCU_2_SeatHdrestHeiAdjmt 0;
BA_ "GenSigSendType" SG_ 1170 SCU_2_BackrAgPosnStsTar 0;
BA_ "GenSigSendType" SG_ 1170 SCU_2_SeatCushPosnSts 0;
BA_ "GenSigSendType" SG_ 1170 SCU_2_SeatHeiPosnStsTar 0;
BA_ "GenSigSendType" SG_ 1090 PsngrSeatVentilationFeedbackSts 0;
BA_ "GenSigSendType" SG_ 1090 DriverSeatVentilationFeedbackSts 0;
BA_ "GenSigSendType" SG_ 1090 Seat_ExtMirror_PositionInfo 0;
BA_ "GenSigSendType" SG_ 1090 SCURelateKeyOrFaceIDFeedbackSts 0;
BA_ "GenSigSendType" SG_ 1090 Seat_ExtMirror_MemorySts 0;
BA_ "GenSigSendType" SG_ 1090 PsngrSeatHeatFeedbackSts 0;
BA_ "GenSigSendType" SG_ 1090 DriverSeatHeatFeedbackSts 0;
BA_ "GenSigSendType" SG_ 1090 ReverseExtMirrorFeedbackSts 0;
BA_ "GenSigSendType" SG_ 1090 EasyEntryFeedbackSts 0;
BA_ "GenSigSendType" SG_ 1090 Seat_ExtMirror_MemoryReq 0;
BA_ "GenSigSendType" SG_ 1090 Seat_ExtMirror_MemoryEnable 0;
BA_ "GenSigSendType" SG_ 924 SAM_1_GCRCCheck 0;
BA_ "GenSigSendType" SG_ 924 SAM_1_G_MessageCounter 0;
BA_ "GenSigSendType" SG_ 924 SteeringAngleSpeedValidData 0;
BA_ "GenSigStartValue" SG_ 924 SteeringAngleSpeedValidData 1;
BA_ "GenSigSendType" SG_ 924 SteeringAngleValidData 0;
BA_ "GenSigStartValue" SG_ 924 SteeringAngleValidData 1;
BA_ "GenSigSendType" SG_ 924 SASCalibrated 0;
BA_ "GenSigSendType" SG_ 924 AngleFailure 0;
BA_ "GenSigSendType" SG_ 924 SteeringAngleSpeed 0;
BA_ "GenSigStartValue" SG_ 924 SteeringAngleSpeed 255;
BA_ "GenSigSendType" SG_ 924 SteeringAngle 0;
BA_ "GenSigStartValue" SG_ 924 SteeringAngle 65535;
BA_ "GenSigSendType" SG_ 1203 RRCR_1_CRC 0;
BA_ "GenSigSendType" SG_ 1203 RRCR_1_MsgCntr 0;
BA_ "GenSigSendType" SG_ 1203 RRCR_1_RCTAWarn 0;
BA_ "GenSigSendType" SG_ 1203 RRCR_1_BSDWarn 0;
BA_ "GenSigSendType" SG_ 1203 RRCR_1_SysSt 0;
BA_ "GenSigSendType" SG_ 498 RLCR_2_RCTBONOFFSts 0;
BA_ "GenSigSendType" SG_ 498 RLCR_2_RAEBONOFFSts 0;
BA_ "GenSigSendType" SG_ 1201 RLCR_1_CRC 0;
BA_ "GenSigSendType" SG_ 1201 RLCR_1_MsgCntr 0;
BA_ "GenSigSendType" SG_ 1201 RLCR_1_RCWONOFFSts 0;
BA_ "GenSigSendType" SG_ 1201 RLCR_1_DOWONOFFSts 0;
BA_ "GenSigSendType" SG_ 1201 RLCR_1_BSDLCARCTAONOFFSts 0;
BA_ "GenSigSendType" SG_ 1201 RLCR_1_RCTAWarn 0;
BA_ "GenSigSendType" SG_ 1201 RLCR_1_BSDWarn 0;
BA_ "GenSigSendType" SG_ 1201 RLCR_1_SysSt 0;
BA_ "GenSigSendType" SG_ 1141 LHSFRadarSensorDistance 0;
BA_ "GenSigStartValue" SG_ 1141 LHSFRadarSensorDistance 126;
BA_ "GenSigSendType" SG_ 1141 RHSFRadarSensorDistance 0;
BA_ "GenSigStartValue" SG_ 1141 RHSFRadarSensorDistance 126;
BA_ "GenSigSendType" SG_ 1141 LHSRRadarSensorDistance 0;
BA_ "GenSigStartValue" SG_ 1141 LHSRRadarSensorDistance 126;
BA_ "GenSigSendType" SG_ 1141 RHSRRadarSensorDistance 0;
BA_ "GenSigStartValue" SG_ 1141 RHSRRadarSensorDistance 126;
BA_ "GenSigSendType" SG_ 1088 RadarWorkSts 0;
BA_ "GenSigSendType" SG_ 1088 RadarDetectSts 0;
BA_ "GenSigSendType" SG_ 1088 AudibleBeepRate 0;
BA_ "GenSigSendType" SG_ 1088 LHMFRadarSensorDistance 0;
BA_ "GenSigStartValue" SG_ 1088 LHMFRadarSensorDistance 30;
BA_ "GenSigSendType" SG_ 1088 RHMFRadarSensorDistance 0;
BA_ "GenSigStartValue" SG_ 1088 RHMFRadarSensorDistance 30;
BA_ "GenSigSendType" SG_ 1088 RHFRadarSensorDistance 0;
BA_ "GenSigStartValue" SG_ 1088 RHFRadarSensorDistance 30;
BA_ "GenSigSendType" SG_ 1088 LHFRadarSensorDistance 0;
BA_ "GenSigStartValue" SG_ 1088 LHFRadarSensorDistance 30;
BA_ "GenSigSendType" SG_ 1088 RHRRadarSensorDistance 0;
BA_ "GenSigStartValue" SG_ 1088 RHRRadarSensorDistance 62;
BA_ "GenSigSendType" SG_ 1088 LHMRRadarSensorDistance 0;
BA_ "GenSigStartValue" SG_ 1088 LHMRRadarSensorDistance 62;
BA_ "GenSigSendType" SG_ 1088 RHMRRadarSensorDistance 0;
BA_ "GenSigStartValue" SG_ 1088 RHMRRadarSensorDistance 62;
BA_ "GenSigSendType" SG_ 1088 LHRRadarSensorDistance 0;
BA_ "GenSigStartValue" SG_ 1088 LHRRadarSensorDistance 62;
BA_ "GenSigSendType" SG_ 1078 PLG_OperateSts 0;
BA_ "GenSigSendType" SG_ 1078 PLG_Set_MaxPosition 0;
BA_ "GenSigStartValue" SG_ 1078 PLG_Set_MaxPosition 100;
BA_ "GenSigSendType" SG_ 1042 PEPS_BLTKey_PESts 0;
BA_ "GenSigSendType" SG_ 1042 WelcomLightPollingSts 0;
BA_ "GenSigSendType" SG_ 1042 PEPS_IntelligentOpenSts 0;
BA_ "GenSigSendType" SG_ 1042 PEPSPollingSts 0;
BA_ "GenSigSendType" SG_ 998 RemoteStartSts 0;
BA_ "GenSigSendType" SG_ 998 Start_StopRequest 0;
BA_ "GenSigSendType" SG_ 998 IDInformation 0;
BA_ "GenSigStartValue" SG_ 998 IDInformation 1;
BA_ "GenSigSendType" SG_ 1124 NFC_1_DispCardPosn 0;
BA_ "GenSigSendType" SG_ 1124 NFC_1_IDList 0;
BA_ "GenSigSendType" SG_ 1124 NFC_1_ID 0;
BA_ "GenSigSendType" SG_ 864 MFS_ICM_Right 1;
BA_ "GenSigSendType" SG_ 864 MFS_ICM_Left 1;
BA_ "GenSigSendType" SG_ 864 MFS_ICM_Down 1;
BA_ "GenSigSendType" SG_ 864 MFS_ICM_UP 1;
BA_ "GenSigSendType" SG_ 864 MFS_Menu 1;
BA_ "GenSigSendType" SG_ 945 MFS_Customize 1;
BA_ "GenSigSendType" SG_ 945 MFS_WeChat 1;
BA_ "GenSigSendType" SG_ 945 MFS_TJA_ICA_ON_OFF 1;
BA_ "GenSigSendType" SG_ 945 MFS_Start_Pause 1;
BA_ "GenSigSendType" SG_ 945 MFS_Mute 1;
BA_ "GenSigSendType" SG_ 945 MFS_VoiceRecognition 1;
BA_ "GenSigSendType" SG_ 945 MFS_PhoneHangUP 1;
BA_ "GenSigSendType" SG_ 945 MFS_PhonePickUP 1;
BA_ "GenSigSendType" SG_ 945 MFS_SeekDown 1;
BA_ "GenSigSendType" SG_ 945 MFS_SeekUp 1;
BA_ "GenSigSendType" SG_ 945 MFS_VolumeDown 1;
BA_ "GenSigSendType" SG_ 945 MFS_VolumeUp 1;
BA_ "GenSigSendType" SG_ 945 MFS_Mode 1;
BA_ "GenSigSendType" SG_ 1218 LHM_1_ADBenable_Feedback 0;
BA_ "GenSigSendType" SG_ 1218 LHM_1_ADBSts 0;
BA_ "GenSigSendType" SG_ 1059 LDWSensitivitySettingFeedback 0;
BA_ "GenSigStartValue" SG_ 1059 LDWSensitivitySettingFeedback 2;
BA_ "GenSigSendType" SG_ 1059 LDWSwitchStsFeedback 0;
BA_ "GenSigStartValue" SG_ 1059 LDWSwitchStsFeedback 1;
BA_ "GenSigSendType" SG_ 1175 CST_SensitivitySts 0;
BA_ "GenSigStartValue" SG_ 1175 CST_SensitivitySts 2;
BA_ "GenSigSendType" SG_ 1175 BrakepedalFeelSts 0;
BA_ "GenSigSendType" SG_ 1175 CST_Status 0;
BA_ "GenSigStartValue" SG_ 1175 CST_Status 1;
BA_ "GenSigSendType" SG_ 1175 IPB_AssociWithDriverModeSts 0;
BA_ "GenSigSendType" SG_ 1149 IMMO_Teach 1;
BA_ "GenSigSendType" SG_ 1110 IMMO_Chall 1;
BA_ "GenSigSendType" SG_ 906 IDCU_12CPMod 0;
BA_ "GenSigSendType" SG_ 906 IDCU_12Rmninfo 0;
BA_ "GenSigSendType" SG_ 1248 IDCU_11_DrvAssiStylests 0;
BA_ "GenSigSendType" SG_ 1248 IDCU_11_DCLCONOFFsts 0;
BA_ "GenSigSendType" SG_ 533 ICM_8_FrntRadarSwt 2;
BA_ "GenSigSendType" SG_ 533 ICM_ESPSwitchCmd 2;
BA_ "GenSigSendType" SG_ 647 ICM_DVDAudibleAlarmStyle 0;
BA_ "GenSigSendType" SG_ 647 ICM_DVDAudibleAlarm 0;
BA_ "GenSigSendType" SG_ 647 CTP_DriveModeSet 0;
BA_ "GenSigSendType" SG_ 647 ICM_5_AlrmVolCtrl 4;
BA_ "GenSigSendType" SG_ 647 ICM_5_BackLiBriAdjmt 4;
BA_ "GenSigSendType" SG_ 1107 Reserved_ThemeTypeFeedback 0;
BA_ "GenSigSendType" SG_ 1107 FatigureDrivingWaring 0;
BA_ "GenSigSendType" SG_ 1107 CurrentTimeYear 0;
BA_ "GenSigSendType" SG_ 1107 CurrentTimeMonth 0;
BA_ "GenSigStartValue" SG_ 1107 CurrentTimeMonth 1;
BA_ "GenSigSendType" SG_ 1107 CurrentTimeDay 0;
BA_ "GenSigStartValue" SG_ 1107 CurrentTimeDay 1;
BA_ "GenSigSendType" SG_ 1107 ResidualOdometer 0;
BA_ "GenSigStartValue" SG_ 1107 ResidualOdometer 1023;
BA_ "GenSigSendType" SG_ 1107 CurrentTimeSecond 0;
BA_ "GenSigSendType" SG_ 1107 ICM_BrightnessLevel 0;
BA_ "GenSigSendType" SG_ 1107 LowFuleWarning 0;
BA_ "GenSigSendType" SG_ 1107 FatigureDrivingTime 0;
BA_ "GenSigStartValue" SG_ 1107 FatigureDrivingTime 1;
BA_ "GenSigSendType" SG_ 1107 CurrentTimeMinute 0;
BA_ "GenSigSendType" SG_ 1107 CurrentTimeHour 0;
BA_ "GenSigSendType" SG_ 1106 ICM_2_OverSpeedValue 0;
BA_ "GenSigSendType" SG_ 1106 BackLightLevel 0;
BA_ "GenSigSendType" SG_ 1106 AverageFuelConsumption 0;
BA_ "GenSigSendType" SG_ 1072 TotalOdometer_km 0;
BA_ "GenSigSendType" SG_ 1072 FuelLevel 0;
BA_ "GenSigSendType" SG_ 1072 ECOModeSWSts 0;
BA_ "GenSigSendType" SG_ 1072 BatteryVoltage 0;
BA_ "GenSigSendType" SG_ 1072 DisplayVehicleSpeed 0;
BA_ "GenSigSendType" SG_ 1072 ICM_1_HandBrakeSystemSts 0;
BA_ "GenSigSendType" SG_ 903 FCM_FRM_6_VSetDis 0;
BA_ "GenSigSendType" SG_ 903 FCM_FRM_6_AEBMode 0;
BA_ "GenSigStartValue" SG_ 903 FCM_FRM_6_AEBMode 2;
BA_ "GenSigSendType" SG_ 903 FCM_FRM_6_FCWMode 0;
BA_ "GenSigStartValue" SG_ 903 FCM_FRM_6_FCWMode 1;
BA_ "GenSigSendType" SG_ 903 FCM_FRM_6_TakeOverReq 0;
BA_ "GenSigSendType" SG_ 903 FCM_FRM_6_FCW_preWarning 0;
BA_ "GenSigSendType" SG_ 903 FCM_FRM_6_DistanceWarning 0;
BA_ "GenSigSendType" SG_ 903 FCM_FRM_6_TimeGapSetICM 0;
BA_ "GenSigSendType" SG_ 903 FCM_FRM_6_ACCMode 0;
BA_ "GenSigSendType" SG_ 1251 FCM_FRM_5_DAIONOFFSts 0;
BA_ "GenSigStartValue" SG_ 1251 FCM_FRM_5_DAIONOFFSts 1;
BA_ "GenSigSendType" SG_ 1251 FCM_FRM_5_SCFONOFFSts 0;
BA_ "GenSigStartValue" SG_ 1251 FCM_FRM_5_SCFONOFFSts 1;
BA_ "GenSigSendType" SG_ 1251 FCM_FRM_5_FCWONOFFSts 0;
BA_ "GenSigStartValue" SG_ 1251 FCM_FRM_5_FCWONOFFSts 1;
BA_ "GenSigSendType" SG_ 1251 FCM_FRM_5_FCWSnvtySts 0;
BA_ "GenSigStartValue" SG_ 1251 FCM_FRM_5_FCWSnvtySts 1;
BA_ "GenSigSendType" SG_ 1251 FCM_FRM_5_AEBONOFFSts 0;
BA_ "GenSigStartValue" SG_ 1251 FCM_FRM_5_AEBONOFFSts 1;
BA_ "GenSigSendType" SG_ 1020 FCM_10_TJAICAExitTextInfoSts 0;
BA_ "GenSigStartValue" SG_ 1020 FCM_10_TJAICAExitTextInfoSts 1;
BA_ "GenSigSendType" SG_ 1020 FCM_10_LDPTJAELKTakeoverReq 0;
BA_ "GenSigSendType" SG_ 1020 FCM_10_TSINoParkWarn 0;
BA_ "GenSigSendType" SG_ 1020 FCM_10_ELKSysSts 0;
BA_ "GenSigSendType" SG_ 1020 FCM_10_LDWSysSts 0;
BA_ "GenSigSendType" SG_ 1020 FCM_10_LDPSysSts 0;
BA_ "GenSigSendType" SG_ 1020 FCM_10_TLITrfcLi 0;
BA_ "GenSigSendType" SG_ 1020 FCM_10_TSISgnLongStayDisp 0;
BA_ "GenSigSendType" SG_ 1020 FCM_10_TLISysSts 0;
BA_ "GenSigSendType" SG_ 1020 FCM_10_TSISysSts 0;
BA_ "GenSigSendType" SG_ 1245 FCM_5_ELKONOFFSts 0;
BA_ "GenSigStartValue" SG_ 1245 FCM_5_ELKONOFFSts 1;
BA_ "GenSigSendType" SG_ 1245 FCM_5_LDWLDPSnvtySts 0;
BA_ "GenSigStartValue" SG_ 1245 FCM_5_LDWLDPSnvtySts 1;
BA_ "GenSigSendType" SG_ 1245 FCM_5_LDPONOFFSts 0;
BA_ "GenSigStartValue" SG_ 1245 FCM_5_LDPONOFFSts 2;
BA_ "GenSigSendType" SG_ 1245 FCM_5_WarnModSts 0;
BA_ "GenSigStartValue" SG_ 1245 FCM_5_WarnModSts 3;
BA_ "GenSigSendType" SG_ 1245 FCM_5_LDWONOFFSts 0;
BA_ "GenSigStartValue" SG_ 1245 FCM_5_LDWONOFFSts 1;
BA_ "GenSigSendType" SG_ 1245 FCM_5_TLIONOFFSts 0;
BA_ "GenSigStartValue" SG_ 1245 FCM_5_TLIONOFFSts 1;
BA_ "GenSigSendType" SG_ 1245 FCM_5_TSIONOFFSts 0;
BA_ "GenSigStartValue" SG_ 1245 FCM_5_TSIONOFFSts 1;
BA_ "GenSigSendType" SG_ 1245 FCM_5_HMAONOFFSts 0;
BA_ "GenSigStartValue" SG_ 1245 FCM_5_HMAONOFFSts 1;
BA_ "GenSigSendType" SG_ 1245 FCM_5_IESONOFFSts 0;
BA_ "GenSigStartValue" SG_ 1245 FCM_5_IESONOFFSts 1;
BA_ "GenSigSendType" SG_ 1245 FCM_5_SLAONOFFSts 0;
BA_ "GenSigStartValue" SG_ 1245 FCM_5_SLAONOFFSts 1;
BA_ "GenSigSendType" SG_ 1245 FCM_5_TJAICAExitTextInfoSts 0;
BA_ "GenSigStartValue" SG_ 1245 FCM_5_TJAICAExitTextInfoSts 1;
BA_ "GenSigSendType" SG_ 775 FCM_2_SLASpdlimitUnits 0;
BA_ "GenSigSendType" SG_ 775 TJA_ICA_mode 0;
BA_ "GenSigSendType" SG_ 775 Camera_textinfo 0;
BA_ "GenSigSendType" SG_ 775 SLASpdlimitWarning 0;
BA_ "GenSigSendType" SG_ 775 SLASpdlimit 0;
BA_ "GenSigSendType" SG_ 775 SLAState 0;
BA_ "GenSigStartValue" SG_ 775 SLAState 1;
BA_ "GenSigSendType" SG_ 775 LDW_ELK_TJA_LDPRightVisuali 0;
BA_ "GenSigSendType" SG_ 775 LDW_ELK_TJA_LDPLeftVisuali 0;
BA_ "GenSigSendType" SG_ 775 HMA_HighbeamReq 0;
BA_ "GenSigSendType" SG_ 775 HMA_Status 0;
BA_ "GenSigStartValue" SG_ 775 HMA_Status 1;
BA_ "GenSigSendType" SG_ 896 EPS_AssociWithDriverModeSts 0;
BA_ "GenSigSendType" SG_ 896 EPS_AssistanceStyle_Sts 0;
BA_ "GenSigSendType" SG_ 1240 EMS_BoostP 0;
BA_ "GenSigSendType" SG_ 1057 BrakePedalSts 0;
BA_ "GenSigSendType" SG_ 1057 BrakePedalStsValidData 0;
BA_ "GenSigSendType" SG_ 1057 GasPedalPositionInvalidData 0;
BA_ "GenSigSendType" SG_ 1057 GasPedalPosition 0;
BA_ "GenSigSendType" SG_ 640 EngineSts 0;
BA_ "GenSigSendType" SG_ 640 SSMStatus 0;
BA_ "GenSigSendType" SG_ 640 EngineSpeed 0;
BA_ "GenSigSendType" SG_ 1277 CLM_10_SeRowDispSts 0;
BA_ "GenSigSendType" SG_ 1277 CLM_10_RfgtLkDispSts 0;
BA_ "GenSigSendType" SG_ 1277 CLM_10_ReRowDispSts 0;
BA_ "GenSigSendType" SG_ 1277 CLM_10_ReRowBlowSpdLvlSts 0;
BA_ "GenSigSendType" SG_ 1277 CLM_10_ReRowWorkSts 0;
BA_ "GenSigSendType" SG_ 1277 CLM_10_RmnDispSts 0;
BA_ "GenSigSendType" SG_ 1277 CLM_10_AQSDispSts 0;
BA_ "GenSigSendType" SG_ 1277 SelfTestResult2 1;
BA_ "GenSigSendType" SG_ 1277 IntelligentCustomSts 0;
BA_ "GenSigSendType" SG_ 1277 CLM_10_SeRowWorkSts 0;
BA_ "GenSigSendType" SG_ 1277 CLM_10_SeRowBlowSpdLvlDispSts 0;
BA_ "GenSigSendType" SG_ 1277 PtcHeatgSts 0;
BA_ "GenSigSendType" SG_ 1334 FragranCeconsistenceLevelSts 0;
BA_ "GenSigStartValue" SG_ 1334 FragranCeconsistenceLevelSts 1;
BA_ "GenSigSendType" SG_ 1334 Pos3_FragranceTypesSts 0;
BA_ "GenSigSendType" SG_ 1334 Pos2_FragranceTypesSts 0;
BA_ "GenSigSendType" SG_ 1334 PM2_5AutoRunSetSts 0;
BA_ "GenSigSendType" SG_ 1334 PM2_5_Incar_Level 0;
BA_ "GenSigSendType" SG_ 1334 PM2_5_Outcar_Level 0;
BA_ "GenSigSendType" SG_ 1334 FragranceDisplaysts 0;
BA_ "GenSigSendType" SG_ 1334 FragrancePositionSwt 0;
BA_ "GenSigSendType" SG_ 1334 ACModeCustomSts 0;
BA_ "GenSigSendType" SG_ 1334 FragranceWelcomeModeSts 0;
BA_ "GenSigSendType" SG_ 1334 RefreshFunctionSts 0;
BA_ "GenSigStartValue" SG_ 1334 RefreshFunctionSts 1;
BA_ "GenSigSendType" SG_ 1334 Pos1_FragranceTypesSts 0;
BA_ "GenSigSendType" SG_ 1334 PM2_5AutoRunSts 0;
BA_ "GenSigStartValue" SG_ 1334 PM2_5AutoRunSts 1;
BA_ "GenSigSendType" SG_ 1334 FragranceSWSts 0;
BA_ "GenSigStartValue" SG_ 1334 FragranceSWSts 1;
BA_ "GenSigSendType" SG_ 1334 AutoBltCalllowBlowSpeedSts 0;
BA_ "GenSigSendType" SG_ 1334 AutoParkInnerCirculationSts 0;
BA_ "GenSigSendType" SG_ 1334 PM2_5_IncarSts 0;
BA_ "GenSigSendType" SG_ 1334 PM2_5_ExtSts 0;
BA_ "GenSigSendType" SG_ 1334 PM2_5_ext 0;
BA_ "GenSigSendType" SG_ 1334 FragranceShortageWarning 0;
BA_ "GenSigSendType" SG_ 1334 ION_Function_Sts 0;
BA_ "GenSigSendType" SG_ 1334 PM2_5_incar 0;
BA_ "GenSigSendType" SG_ 1333 AUTODefrostDisplaySts 1;
BA_ "GenSigSendType" SG_ 1333 TempKnobRollingCounter 3;
BA_ "GenSigSendType" SG_ 1333 BlowSpeedLevelDisplaySts 3;
BA_ "GenSigSendType" SG_ 1333 AUTODefrostForceOpenSts 1;
BA_ "GenSigSendType" SG_ 1333 PM2_5Displaysts 1;
BA_ "GenSigSendType" SG_ 1333 PM2_5overproofDisplaySts 1;
BA_ "GenSigSendType" SG_ 1333 FiltertchangeDisplaySts 1;
BA_ "GenSigSendType" SG_ 1333 REARInhibitSts 1;
BA_ "GenSigSendType" SG_ 1333 AUTODefrostOnSts 0;
BA_ "GenSigSendType" SG_ 1306 SetTemperature_R_F 1;
BA_ "GenSigStartValue" SG_ 1306 SetTemperature_R_F 17;
BA_ "GenSigSendType" SG_ 1306 SetTemperature_L_F 1;
BA_ "GenSigStartValue" SG_ 1306 SetTemperature_L_F 17;
BA_ "GenSigSendType" SG_ 1306 SelfTestResult 1;
BA_ "GenSigSendType" SG_ 1306 TemperatureUnit 1;
BA_ "GenSigSendType" SG_ 1306 ZoneSelectionDisplaySts 1;
BA_ "GenSigSendType" SG_ 1306 CirculationModeDisplaySts 1;
BA_ "GenSigStartValue" SG_ 1306 CirculationModeDisplaySts 1;
BA_ "GenSigSendType" SG_ 1306 SetTemperature_R_C 1;
BA_ "GenSigStartValue" SG_ 1306 SetTemperature_R_C 17;
BA_ "GenSigSendType" SG_ 1306 SetTemperature_L_C 1;
BA_ "GenSigStartValue" SG_ 1306 SetTemperature_L_C 17;
BA_ "GenSigSendType" SG_ 1306 BlowDelayOffSts 0;
BA_ "GenSigSendType" SG_ 1306 BlowAdvanceOnSts 0;
BA_ "GenSigSendType" SG_ 1306 DisplayActive 1;
BA_ "GenSigSendType" SG_ 1306 SelfTestActive 1;
BA_ "GenSigSendType" SG_ 1306 PM2_5Sts 0;
BA_ "GenSigSendType" SG_ 1306 WorkingSts 1;
BA_ "GenSigSendType" SG_ 1306 ModeAdjustDisplaySts 1;
BA_ "GenSigStartValue" SG_ 1306 ModeAdjustDisplaySts 5;
BA_ "GenSigSendType" SG_ 1306 FrontDeforest_MaxDisplaySts 0;
BA_ "GenSigSendType" SG_ 1306 ACRequestDisplaySts 1;
BA_ "GenSigSendType" SG_ 1306 AutoDisplaySts 1;
BA_ "GenSigSendType" SG_ 1306 Reserved_AC_MaxSts 1;
BA_ "GenSigSendType" SG_ 1306 ExternalTemperatureFailSts 0;
BA_ "GenSigSendType" SG_ 1306 ExternalTemperature_C 0;
BA_ "GenSigStartValue" SG_ 1306 ExternalTemperature_C 254;
BA_ "GenSigSendType" SG_ 1306 ExternalTemperature_F 0;
BA_ "GenSigStartValue" SG_ 1306 ExternalTemperature_F 254;
BA_ "GenSigSendType" SG_ 1104 OBDDiagnosisReqInd 0;
BA_ "GenSigSendType" SG_ 1178 BDM_26_RRWinPosn 0;
BA_ "GenSigSendType" SG_ 1178 BDM_26_RLWinPosn 0;
BA_ "GenSigSendType" SG_ 1178 BDM_26_FRWinPosn 0;
BA_ "GenSigSendType" SG_ 1178 BDM_26_FLWinPosn 0;
BA_ "GenSigSendType" SG_ 1007 BDM_25_AmbBrightness 0;
BA_ "GenSigSendType" SG_ 1007 BDM_25_FWBrightness 0;
BA_ "GenSigSendType" SG_ 1287 BCM_22_WiprSnvtySetFb 0;
BA_ "GenSigSendType" SG_ 1287 PassSeatMsgStr_LvlSts 0;
BA_ "GenSigSendType" SG_ 1287 PassSeatMsg_ModeSts 0;
BA_ "GenSigSendType" SG_ 746 BDM_OTAPwrOnReqFb 0;
BA_ "GenSigSendType" SG_ 746 BDM_OTAPwrDwnReqFb 0;
BA_ "GenSigSendType" SG_ 746 BDM_OTAModStsFb 0;
BA_ "GenSigSendType" SG_ 746 SlaveVehMod 0;
BA_ "GenSigSendType" SG_ 746 VehPwrMod 0;
BA_ "GenSigSendType" SG_ 901 CTP_VolStepValForDVD 0;
BA_ "GenSigSendType" SG_ 901 CTP_VolPlusMinusForDVDSts 0;
BA_ "GenSigSendType" SG_ 901 CTP_HomeKeyForIHUSts 0;
BA_ "GenSigSendType" SG_ 901 CTP_PowerKeyForIHUSts 0;
BA_ "GenSigSendType" SG_ 901 CTP_TrackMod 0;
BA_ "GenSigSendType" SG_ 901 CTP_DriveModeSet 0;
BA_ "GenSigSendType" SG_ 901 CTP_NavKeyForIHUSts 0;
BA_ "GenSigSendType" SG_ 901 CTPKeyVoiceRemindReq 0;
BA_ "GenSigSendType" SG_ 901 IHUSetSwitch 0;
BA_ "GenSigSendType" SG_ 901 AVMSwitch 0;
BA_ "GenSigSendType" SG_ 936 IBS_SOH 0;
BA_ "GenSigStartValue" SG_ 936 IBS_SOH 255;
BA_ "GenSigSendType" SG_ 936 IBS_SOC 0;
BA_ "GenSigStartValue" SG_ 936 IBS_SOC 255;
BA_ "GenSigSendType" SG_ 934 IBS_Current 0;
BA_ "GenSigSendType" SG_ 934 IBS_Voltage 0;
BA_ "GenSigStartValue" SG_ 934 IBS_Voltage 16383;
BA_ "GenSigSendType" SG_ 1063 TheaterDimmingColorFeedback_64 0;
BA_ "GenSigStartValue" SG_ 1063 TheaterDimmingColorFeedback_64 2;
BA_ "GenSigSendType" SG_ 1063 Rainfall 0;
BA_ "GenSigSendType" SG_ 1063 HUDBriUnit 0;
BA_ "GenSigSendType" SG_ 1063 HUDBriRawVal 0;
BA_ "GenSigStartValue" SG_ 1063 HUDBriRawVal 127;
BA_ "GenSigSendType" SG_ 1077 RvsExtMirrFbSts 0;
BA_ "GenSigSendType" SG_ 1077 Reserved_RainingWarning 0;
BA_ "GenSigSendType" SG_ 1077 SRF_Hall2SensorError 0;
BA_ "GenSigSendType" SG_ 1077 SRF_Hall1SensorError 0;
BA_ "GenSigSendType" SG_ 1077 SRF_SunroofOverVolt 0;
BA_ "GenSigSendType" SG_ 1077 SRF_SunroofUnderVolt 0;
BA_ "GenSigSendType" SG_ 1077 SRF_LINCommunicationERROR 0;
BA_ "GenSigSendType" SG_ 1077 SRF_SwitchError 0;
BA_ "GenSigSendType" SG_ 1077 SRF_OverHeatProtect 0;
BA_ "GenSigSendType" SG_ 1077 SRF_MotorRelayError 0;
BA_ "GenSigSendType" SG_ 1077 AssociatedWithDriverModeFeedback 0;
BA_ "GenSigSendType" SG_ 1077 TheaterDimmingBrightnessFeedback 0;
BA_ "GenSigStartValue" SG_ 1077 TheaterDimmingBrightnessFeedback 2;
BA_ "GenSigSendType" SG_ 1077 TheaterDimmingColorFeedback 0;
BA_ "GenSigStartValue" SG_ 1077 TheaterDimmingColorFeedback 5;
BA_ "GenSigSendType" SG_ 1077 SRF_Sunshade_OperateSts 0;
BA_ "GenSigSendType" SG_ 1077 RRWindowSts 0;
BA_ "GenSigSendType" SG_ 1077 RLWindowSts 0;
BA_ "GenSigSendType" SG_ 1077 WindowInhibitSts 0;
BA_ "GenSigSendType" SG_ 1077 FRWindow_Sts 0;
BA_ "GenSigSendType" SG_ 1077 FLWindow_Sts 0;
BA_ "GenSigSendType" SG_ 1077 Window_OperateSts 0;
BA_ "GenSigSendType" SG_ 1077 Reserved_SRF_Error 0;
BA_ "GenSigSendType" SG_ 1077 SRF_InitStatus 0;
BA_ "GenSigSendType" SG_ 1077 AssociatedWithMusicModeFeedback 0;
BA_ "GenSigSendType" SG_ 1077 TheaterDimmingStatusFeedback 0;
BA_ "GenSigStartValue" SG_ 1077 TheaterDimmingStatusFeedback 1;
BA_ "GenSigSendType" SG_ 1077 SRF_PositionSts 0;
BA_ "GenSigSendType" SG_ 1077 SRF_OperateSts 0;
BA_ "GenSigSendType" SG_ 1307 RHRTirePressure 0;
BA_ "GenSigSendType" SG_ 1307 LHRTirePressure 0;
BA_ "GenSigSendType" SG_ 1307 RHFTirePressure 0;
BA_ "GenSigSendType" SG_ 1307 LHFTirePressure 0;
BA_ "GenSigSendType" SG_ 1307 TireTemperature 0;
BA_ "GenSigSendType" SG_ 1307 TirePosition 0;
BA_ "GenSigSendType" SG_ 1307 TirePositionWarning_RHRTire 0;
BA_ "GenSigSendType" SG_ 1307 TirePositionWarning_LHRTire 0;
BA_ "GenSigSendType" SG_ 1307 TirePositionWarning_RHFTire 0;
BA_ "GenSigSendType" SG_ 1307 TirePositionWarning_LHFTire 0;
BA_ "GenSigSendType" SG_ 1307 TirePressureWarningLampSts 0;
BA_ "GenSigSendType" SG_ 914 DRLModeSts 0;
BA_ "GenSigStartValue" SG_ 914 DRLModeSts 1;
BA_ "GenSigSendType" SG_ 914 HeadlampDelayLightSts 0;
BA_ "GenSigStartValue" SG_ 914 HeadlampDelayLightSts 1;
BA_ "GenSigSendType" SG_ 914 AutolockSts 0;
BA_ "GenSigSendType" SG_ 914 AutoFoldSts 0;
BA_ "GenSigSendType" SG_ 914 HeadlampHeightFeedbackSts 0;
BA_ "GenSigSendType" SG_ 914 RemoteLockFeedbackSts 0;
BA_ "GenSigSendType" SG_ 914 BCM_4_ReverseGearSts 0;
BA_ "GenSigSendType" SG_ 914 BCM_4_RearFogLightSts 0;
BA_ "GenSigSendType" SG_ 914 BCM_4_DriverDoorLockSts 0;
BA_ "GenSigStartValue" SG_ 914 BCM_4_DriverDoorLockSts 1;
BA_ "GenSigSendType" SG_ 914 BCM_4_TrunkSts 0;
BA_ "GenSigSendType" SG_ 914 BCM_4_LHRdoorSts 0;
BA_ "GenSigSendType" SG_ 914 BCM_4_RHRDoorSts 0;
BA_ "GenSigSendType" SG_ 914 BCM_4_HoodSts 0;
BA_ "GenSigSendType" SG_ 914 BCM_4_PsngrDoorSts 0;
BA_ "GenSigSendType" SG_ 914 BCM_4_DriverDoorSts 0;
BA_ "GenSigSendType" SG_ 914 RVSMode 0;
BA_ "GenSigSendType" SG_ 914 DirectionIndLeft 0;
BA_ "GenSigSendType" SG_ 914 DirectionIndRight 0;
BA_ "GenSigSendType" SG_ 914 BCM_4_ParkLightSts 0;
BA_ "GenSigSendType" SG_ 914 DrvrDoorUnlckOnlySts 0;
BA_ "GenSigSendType" SG_ 914 FGHeat_Req_CmdFeedback 0;
BA_ "GenSigSendType" SG_ 914 BCM_4_KeySts 0;
BA_ "GenSigSendType" SG_ 914 LightDetected 0;
BA_ "GenSigSendType" SG_ 914 BCM_4_ArmingSts 0;
BA_ "GenSigSendType" SG_ 913 AutoHighSpeedRequest 0;
BA_ "GenSigSendType" SG_ 913 RainDetected 0;
BA_ "GenSigSendType" SG_ 913 WiperSts 0;
BA_ "GenSigSendType" SG_ 913 SteeringWheelheatingSts 0;
BA_ "GenSigSendType" SG_ 913 RARDfstCmd 0;
BA_ "GenSigSendType" SG_ 913 HazardLightSW 0;
BA_ "GenSigSendType" SG_ 1217 ASU_1_SetModsts 0;
BA_ "GenSigSendType" SG_ 1217 ASU_1_AssocWithDrvrModFB 0;
BA_ "GenSigSendType" SG_ 554 APAFailureSts 0;
BA_ "GenSigSendType" SG_ 554 APA_Active 0;
BA_ "GenSigSendType" SG_ 554 AVM_APA_SystemSts 0;
BA_ "GenSigSendType" SG_ 1267 AIPM_2_DriveModeSet 0;
BA_ "GenSigSendType" SG_ 1265 PanelKeyVoiceRemindReq 1;
BA_ "GenSigSendType" SG_ 704 ABS_ESP_Checksum 0;
BA_ "GenSigSendType" SG_ 704 HDCCtrlSts 0;
BA_ "GenSigSendType" SG_ 704 ABS_ESP_MessageCounter 0;
BA_ "GenSigSendType" SG_ 704 VehicleSpeedVSOSigValidData 0;
BA_ "GenSigStartValue" SG_ 704 VehicleSpeedVSOSigValidData 1;
BA_ "GenSigSendType" SG_ 704 VehicleSpeedVSOSig 0;
BA_ "GenSigSendType" SG_ 704 ESPSwitchStatus 0;
BA_ "GenSigSendType" SG_ 932 ABSESP_8_Checksum 0;
BA_ "GenSigSendType" SG_ 932 ABSESP_8_MessageCounter 0;
BA_ "GenSigSendType" SG_ 932 RHRWheelSpeedRawValidData 0;
BA_ "GenSigStartValue" SG_ 932 RHRWheelSpeedRawValidData 1;
BA_ "GenSigSendType" SG_ 932 RHRWheelDriveDirection 0;
BA_ "GenSigSendType" SG_ 932 RHRWheelSpeedRaw 0;
BA_ "GenSigSendType" SG_ 932 LHRWheelSpeedRawValidData 0;
BA_ "GenSigStartValue" SG_ 932 LHRWheelSpeedRawValidData 1;
BA_ "GenSigSendType" SG_ 932 LHRWheelDriveDirection 0;
BA_ "GenSigSendType" SG_ 932 LHRWheelSpeedRaw 0;
BA_ "GenSigSendType" SG_ 931 ABSESP_7_Checksum 0;
BA_ "GenSigSendType" SG_ 931 ABSESP_7_MessageCounter 0;
BA_ "GenSigSendType" SG_ 931 RHFWheelSpeedRawValidData 0;
BA_ "GenSigStartValue" SG_ 931 RHFWheelSpeedRawValidData 1;
BA_ "GenSigSendType" SG_ 931 RHFWheelDriveDirection 0;
BA_ "GenSigSendType" SG_ 931 RHFWheelSpeedRaw 0;
BA_ "GenSigSendType" SG_ 931 LHFWheelSpeedRawValidData 0;
BA_ "GenSigStartValue" SG_ 931 LHFWheelSpeedRawValidData 1;
BA_ "GenSigSendType" SG_ 931 LHFWheelDriveDirection 0;
BA_ "GenSigSendType" SG_ 931 LHFWheelSpeedRaw 0;
BA_ "GenSigSendType" SG_ 793 LHFPulseCounter 0;
BA_ "GenSigSendType" SG_ 793 RHFPulseCounter 0;
BA_ "GenSigSendType" SG_ 793 RHRPulseCounterFailSts 0;
BA_ "GenSigSendType" SG_ 793 RHRPulseCounter 0;
BA_ "GenSigSendType" SG_ 793 LHFPulseCounterFailSts 0;
BA_ "GenSigSendType" SG_ 793 RHFPulseCounterFailSts 0;
BA_ "GenSigSendType" SG_ 793 LHRPulseCounterFailSts 0;
BA_ "GenSigSendType" SG_ 793 LHRPulseCounter 0;
BA_ "GenSigSendType" SG_ 787 ABS_ESP_3_AVHSts 0;
BA_ "GenSigSendType" SG_ 787 ABS_ESP_3_AVHFailSts 0;
BA_ "GenSigSendType" SG_ 800 ABM_1_PABSetSts 0;
BA_ "GenSigStartValue" SG_ 800 ABM_1_PABSetSts 1;
BA_ "GenSigSendType" SG_ 1882 Diag_IHU_RES 1;
BA_ "GenSigSendType" SG_ 1942 DMC__ACP_RES 1;
BA_ "GenSigSendType" SG_ 1926 DMC__ACP_REQ 1;
BA_ "GenSigSendType" SG_ 1560 WakeupSource_IHU 0;
BA_ "GenSigSendType" SG_ 1560 usrData4_IHU 0;
BA_ "GenSigSendType" SG_ 1560 usrData3_IHU 0;
BA_ "GenSigSendType" SG_ 1560 usrData2_IHU 0;
BA_ "GenSigSendType" SG_ 1560 ECUSPEC_AWAKE_IHU 0;
BA_ "GenSigSendType" SG_ 1560 DIAGNOSTIC_AWAKE_IHU 0;
BA_ "GenSigSendType" SG_ 1560 IGNITION_AWAKE_IHU 0;
BA_ "GenSigSendType" SG_ 1560 NETWORK_AWAKE_IHU 0;
BA_ "GenSigSendType" SG_ 1560 ECUSPEC_WAKEUP_IHU 0;
BA_ "GenSigSendType" SG_ 1560 NETWORK_WAKEUP_IHU 0;
BA_ "GenSigSendType" SG_ 1560 RESET_WAKEUP_IHU 0;
BA_ "GenSigSendType" SG_ 1560 IGNITION_WAKEUP_IHU 0;
BA_ "GenSigSendType" SG_ 1560 usrData0_IHU 0;
BA_ "GenSigSendType" SG_ 1560 NMm_IHU_Reserved1 0;
BA_ "GenSigSendType" SG_ 1560 RMR_IHU 0;
BA_ "GenSigSendType" SG_ 1560 srcNodeID_IHU 0;
BA_ "GenSigStartValue" SG_ 1560 srcNodeID_IHU 24;
BA_ "GenSigSendType" SG_ 1266 TBOX_SetAVMVeiw 2;
BA_ "GenSigSendType" SG_ 1266 TBOX_SetAVMOnReq 2;
BA_ "GenSigSendType" SG_ 1312 TBOX_1_RemDiagSts 0;
BA_ "GenSigSendType" SG_ 1243 HUD_1_Reserved 0;
BA_ "GenSigSendType" SG_ 1243 STAT_ADASDisplayPoision 0;
BA_ "GenSigSendType" SG_ 1243 STAT_NavigationDisplay 0;
BA_ "GenSigSendType" SG_ 1243 STAT_ADASDisplay 0;
BA_ "GenSigSendType" SG_ 1243 STAT_BluetoothDisplay 0;
BA_ "GenSigSendType" SG_ 1243 HUD_1_HUDHiTWarn 0;
BA_ "GenSigSendType" SG_ 1243 STAT_FaceIDOnOFF 0;
BA_ "GenSigSendType" SG_ 1243 STAT_HUDBrightness 0;
BA_ "GenSigSendType" SG_ 1243 STAT_HUD 0;
BA_ "GenSigSendType" SG_ 1243 STAT_HUDProfileID 0;
BA_ "GenSigSendType" SG_ 1243 STAT_HUDDisplayMod 0;
BA_ "GenSigSendType" SG_ 1243 STAT_HUDDisplayOnOff 0;
BA_ "GenSigSendType" SG_ 1243 STAT_HUDHeight 0;
BA_ "GenSigSendType" SG_ 1140 STAT_AMPESEVol 0;
BA_ "GenSigSendType" SG_ 1140 STAT_AMPWelVol 0;
BA_ "GenSigSendType" SG_ 1140 STAT_AMPBTMediVol 0;
BA_ "GenSigSendType" SG_ 1140 STAT_AMPTEMP 0;
BA_ "GenSigSendType" SG_ 1140 STAT_AMPMute 0;
BA_ "GenSigSendType" SG_ 1140 STAT_AMPSpeedVolume 0;
BA_ "GenSigSendType" SG_ 1140 EAMP_2_HdrestSpkrMod 0;
BA_ "GenSigSendType" SG_ 1121 STAT_AMPAlarmVolume 0;
BA_ "GenSigSendType" SG_ 1121 STAT_AMPLoudness 0;
BA_ "GenSigSendType" SG_ 1121 STAT_AMPLiveAcoustics 0;
BA_ "GenSigSendType" SG_ 1121 STAT_AMPSoundFieldFader 0;
BA_ "GenSigSendType" SG_ 1121 STAT_AMPSoundFieldBalance 0;
BA_ "GenSigSendType" SG_ 1121 STAT_AMPSoundEffectTreble 0;
BA_ "GenSigSendType" SG_ 1121 STAT_AMPSoundEffectMidrange 0;
BA_ "GenSigSendType" SG_ 1121 STAT_AMPSoundEffectBass 0;
BA_ "GenSigSendType" SG_ 1121 STAT_AMPSoundEffect 0;
BA_ "GenSigSendType" SG_ 1121 STAT_AMPRestoreDefaults 0;
BA_ "GenSigSendType" SG_ 1121 STAT_AMPDefaultVolume 0;
BA_ "GenSigSendType" SG_ 1121 STAT_AMPSoundFocus 0;
BA_ "GenSigSendType" SG_ 1121 STAT_AMPPhoneVolume 0;
BA_ "GenSigSendType" SG_ 1121 STAT_AMPMediaVolume 0;
BA_ "GenSigSendType" SG_ 1121 STAT_AMPKeyTone 0;
BA_ "GenSigSendType" SG_ 1121 STAT_AMPVRVolume 0;
BA_ "GenSigSendType" SG_ 1121 STAT_AMPNaviVolume 0;
BA_ "GenSigSendType" SG_ 1517 HUD_IHU_Interaction 1;
BA_ "GenSigSendType" SG_ 1515 IHU_HUD_Interaction 1;
BA_ "GenSigSendType" SG_ 1298 IHU_CVBOX_Interaction 1;
BA_ "GenSigSendType" SG_ 1289 CVBOX_IHU_Interaction 1;
BA_ "GenSigSendType" SG_ 759 DVR_TIHU_Interaction 1;
BA_ "GenSigSendType" SG_ 755 IHU_DVR_Interaction 1;
BA_ "GenSigSendType" SG_ 1151 TIHU_Teach_IMMO 1;
BA_ "GenSigSendType" SG_ 1116 TIHU_Auth 1;
VAL_ 928 LongitudinalAccelerationSigValid 3 " Initialize" 2 " Invalid" 1 " Reserved" 0 " Valid" ;
VAL_ 926 YawrateSigValidData 3 " Initialize" 2 " Invalid" 1 " Reserved" 0 " Valid" ;
VAL_ 769 GBPositoionDisplay 30 "Display M9-" 29 " Display M8-" 28 "Display M8+" 27 " Display M9" 26 " Display M8" 25 " Display M7-" 24 " Display M6-" 23 "Display M5-" 22 "Display M4-" 21 " Display M3-" 20 " Display M2-" 19 " Display M7+" 18 " Display M6+" 17 " Display M5+" 16 "Display M4+" 15 " Display M3+" 14 "Display M2+" 13 "Display M1+" 12 "Low" 11 "Display M7" 10 "Display M6" 9 "Display M5" 8 "Display M4" 7 "Display M3" 6 "Display M2" 5 "Display M1" 4 " Display D" 3 "Display N" 2 " Display R" 1 " Display P" 0 "NO Display" ;
VAL_ 1206 SHU2R_RSeatVentnSts 7 " Reserved" 6 " Reserved" 5 " Reserved" 4 " Reserved" 3 " Seat Ventilation Level3" 2 " Seat Ventilation Level2" 1 " Seat Ventilation Level1" 0 " OFF" ;
VAL_ 1206 SHU2R_RSeatHeatSts 7 " Reserved" 6 " Reserved" 5 " Reserved" 4 " Reserved" 3 " Seat heating Level3" 2 " Seat heating Level2" 1 " Seat heating Level1" 0 " OFF" ;
VAL_ 1202 SHU2M_MSeatVentnSts 7 " Reserved" 6 " Reserved" 5 " Reserved" 4 " Reserved" 3 " Seat Ventilation Level3" 2 " Seat Ventilation Level2" 1 " Seat Ventilation Level1" 0 " OFF" ;
VAL_ 1202 SHU2M_MSeatHeatSts 7 " Reserved" 6 " Reserved" 5 " Reserved" 4 " Reserved" 3 " Seat heating Level3" 2 " Seat heating Level2" 1 " Seat heating Level1" 0 " OFF" ;
VAL_ 1194 SHU2L_LSeatVentnSts 7 " Reserved" 6 " Reserved" 5 " Reserved" 4 " Reserved" 3 " Seat Ventilation Level3" 2 " Seat Ventilation Level2" 1 " Seat Ventilation Level1" 0 " OFF" ;
VAL_ 1194 SHU2L_LSeatHeatSts 7 " Reserved" 6 " Reserved" 5 " Reserved" 4 " Reserved" 3 " Seat heating Level3" 2 " Seat heating Level2" 1 " Seat heating Level1" 0 " OFF" ;
VAL_ 1190 SHU1R_RSeatAutVentnSts 3 " Reserved" 2 " Reserved" 1 " ON" 0 " OFF" ;
VAL_ 1190 SHU1R_RSeatAutHeatSts 3 " Reserved" 2 " Reserved" 1 " ON" 0 " OFF" ;
VAL_ 1190 SHU1R_RSeatVentnSts 7 " Reserved" 6 " Reserved" 5 " Reserved" 4 " Reserved" 3 " Seat Ventilation Level3" 2 " Seat Ventilation Level2" 1 " Seat Ventilation Level1" 0 " OFF" ;
VAL_ 1190 SHU1R_RSeatHeatSts 7 " Reserved" 6 " Reserved" 5 " Reserved" 4 " Reserved" 3 " Seat heating Level3" 2 " Seat heating Level2" 1 " Seat heating Level1" 0 " OFF" ;
VAL_ 1186 SHU1L_LSeatAutVentnSts 3 " Reserved" 2 " Reserved" 1 " ON" 0 " OFF" ;
VAL_ 1186 SHU1L_LSeatAutHeatSts 3 " Reserved" 2 " Reserved" 1 " ON" 0 " OFF" ;
VAL_ 1186 SHU1L_LSeatVentnSts 7 " Reserved" 6 " Reserved" 5 " Reserved" 4 " Reserved" 3 " Seat Ventilation Level3" 2 " Seat Ventilation Level2" 1 " Seat Ventilation Level1" 0 " OFF" ;
VAL_ 1186 SHU1L_LSeatHeatSts 7 " Reserved" 6 " Reserved" 5 " Reserved" 4 " Reserved" 3 " Seat heating Level3" 2 " Seat heating Level2" 1 " Seat heating Level1" 0 " OFF" ;
VAL_ 1090 PsngrSeatVentilationFeedbackSts 3 " Seat Ventilation Level3" 2 " Seat Ventilation Level2" 1 " Seat Ventilation Level1" 0 " OFF" ;
VAL_ 1090 DriverSeatVentilationFeedbackSts 3 " Seat Ventilation Level3" 2 " Seat Ventilation Level2" 1 " Seat Ventilation Level1" 0 " OFF" ;
VAL_ 1090 Seat_ExtMirror_PositionInfo 31 " Not used" 30 " Not used" 29 " Not used" 28 " Not used" 27 " Not used" 26 " Not used" 25 " Not used" 24 " Not used" 23 " Not used" 22 " Not used" 21 " Not used" 20 " Not used" 19 " Not used" 18 " Not used" 17 " Not used" 16 " error" 15 " seat_ExtMirror_Pos2_Recall_ID5" 14 " seat_ExtMirror_Pos1_Recall_ID5" 13 " seat_ExtMirror_Pos0_Recall_ID5" 12 " seat_ExtMirror_Pos2_Recall_ID4" 11 " seat_ExtMirror_Pos1_Recall_ID4" 10 " seat_ExtMirror_Pos0_Recall_ID4" 9 " seat_ExtMirror_Pos2_Recall_ID3" 8 " seat_ExtMirror_Pos1_Recall_ID3" 7 " seat_ExtMirror_Pos0_Recall_ID3" 6 " seat_ExtMirror_Pos2_Recall_ID2" 5 " seat_ExtMirror_Pos1_Recall_ID2" 4 " seat_ExtMirror_Pos0_Recall_ID2" 3 " seat_ExtMirror_Pos2_Recall_ID1" 2 " seat_ExtMirror_Pos1_Recall_ID1" 1 " seat_ExtMirror_Pos0_Recall_ID1" 0 " Not active" ;
VAL_ 1090 SCURelateKeyOrFaceIDFeedbackSts 1 " Relate" 0 " Not Relate" ;
VAL_ 1090 Seat_ExtMirror_MemorySts 3 " Not Used" 2 " Failure" 1 " Success" 0 " Not Active" ;
VAL_ 1090 PsngrSeatHeatFeedbackSts 3 " Seat heating Level3" 2 " Seat heating Level2" 1 " Seat heating Level1" 0 " OFF" ;
VAL_ 1090 DriverSeatHeatFeedbackSts 3 " Seat heating Level3" 2 " Seat heating Level2" 1 " Seat heating Level1" 0 " OFF" ;
VAL_ 1090 ReverseExtMirrorFeedbackSts 3 " Both sides" 2 " Only left side" 1 " Only right side" 0 " OFF" ;
VAL_ 1090 EasyEntryFeedbackSts 1 " ON" 0 " OFF" ;
VAL_ 1090 Seat_ExtMirror_MemoryReq 1 " Request" 0 " No Request" ;
VAL_ 1090 Seat_ExtMirror_MemoryEnable 1 " Enable" 0 " Disable" ;
VAL_ 924 SteeringAngleSpeedValidData 1 " Not Valid" 0 " Valid" ;
VAL_ 924 SteeringAngleValidData 1 " Not Valid" 0 " Valid" ;
VAL_ 924 SASCalibrated 1 " Calibrated" 0 " Not calibrated" ;
VAL_ 924 AngleFailure 1 " Failure" 0 " No Failure" ;
VAL_ 1203 RRCR_1_RCTAWarn 1 " Warning" 0 " No Warning" ;
VAL_ 1203 RRCR_1_BSDWarn 3 " Not Used" 2 " Critical Warning" 1 " Standard Warning" 0 " No Warning" ;
VAL_ 1203 RRCR_1_SysSt 3 " System Error" 2 " Temporary Error" 1 " On" 0 " Off" ;
VAL_ 498 RLCR_2_RCTBONOFFSts 3 " Reserved" 2 " OFF" 1 " ON" 0 " Not active" ;
VAL_ 498 RLCR_2_RAEBONOFFSts 3 " Reserved" 2 " OFF" 1 " ON" 0 " Not active" ;
VAL_ 1201 RLCR_1_RCWONOFFSts 3 " Reserved" 2 " OFF" 1 " ON" 0 " Not active" ;
VAL_ 1201 RLCR_1_DOWONOFFSts 3 " Reserved" 2 " OFF" 1 " ON" 0 " Not active" ;
VAL_ 1201 RLCR_1_BSDLCARCTAONOFFSts 3 " Reserved" 2 " OFF" 1 " ON" 0 " Not active" ;
VAL_ 1201 RLCR_1_RCTAWarn 1 " Warning" 0 " No Warning" ;
VAL_ 1201 RLCR_1_BSDWarn 3 " Not Used" 2 " Critical Warning" 1 " Standard Warning" 0 " No Warning" ;
VAL_ 1201 RLCR_1_SysSt 3 " System Error" 2 " Temporary Error" 1 " On" 0 " Off" ;
VAL_ 1141 LHSFRadarSensorDistance 125 " Not used" 124 " Not used" 123 " Not used" 122 " Not used" 121 " Not used" 120 " Not used" 119 " Not used" 118 " Not used" 117 " Not used" 116 " Not used" 115 " Not used" 114 " Not used" 113 " Not used" 112 " Not used" 111 " Not used" 110 " Not used" 109 " Not used" 108 " Not used" 107 " Not used" 106 " Not used" 105 " Not used" 104 " Not used" 103 " Not used" 102 " Not used" 101 " Not used" 100 " Not used" 99 " Not used" 98 " Not used" 97 " Not used" 96 " Not used" 95 " Not used" ;
VAL_ 1141 RHSFRadarSensorDistance 125 " Not used" 124 " Not used" 123 " Not used" 122 " Not used" 121 " Not used" 120 " Not used" 119 " Not used" 118 " Not used" 117 " Not used" 116 " Not used" 115 " Not used" 114 " Not used" 113 " Not used" 112 " Not used" 111 " Not used" 110 " Not used" 109 " Not used" 108 " Not used" 107 " Not used" 106 " Not used" 105 " Not used" 104 " Not used" 103 " Not used" 102 " Not used" 101 " Not used" 100 " Not used" 99 " Not used" 98 " Not used" 97 " Not used" 96 " Not used" 95 " Not used" ;
VAL_ 1141 LHSRRadarSensorDistance 125 " Not used" 124 " Not used" 123 " Not used" 122 " Not used" 121 " Not used" 120 " Not used" 119 " Not used" 118 " Not used" 117 " Not used" 116 " Not used" 115 " Not used" 114 " Not used" 113 " Not used" 112 " Not used" 111 " Not used" 110 " Not used" 109 " Not used" 108 " Not used" 107 " Not used" 106 " Not used" 105 " Not used" 104 " Not used" 103 " Not used" 102 " Not used" 101 " Not used" 100 " Not used" 99 " Not used" 98 " Not used" 97 " Not used" 96 " Not used" 95 " Not used" ;
VAL_ 1141 RHSRRadarSensorDistance 125 " Not used" 124 " Not used" 123 " Not used" 122 " Not used" 121 " Not used" 120 " Not used" 119 " Not used" 118 " Not used" 117 " Not used" 116 " Not used" 115 " Not used" 114 " Not used" 113 " Not used" 112 " Not used" 111 " Not used" 110 " Not used" 109 " Not used" 108 " Not used" 107 " Not used" 106 " Not used" 105 " Not used" 104 " Not used" 103 " Not used" 102 " Not used" 101 " Not used" 100 " Not used" 99 " Not used" 98 " Not used" 97 " Not used" 96 " Not used" 95 " Not used" ;
VAL_ 1088 RadarWorkSts 1 " Active" 0 " Not active" ;
VAL_ 1088 RadarDetectSts 3 " Not used" 2 " Rear Radar detecting" 1 " Front Radar detecting" 0 " No detecting" ;
VAL_ 1088 AudibleBeepRate 7 " Not used" 6 " Not used" 5 " Not used" 4 " 1Hz" 3 " 2Hz" 2 " 4Hz" 1 " On" 0 " Off" ;
VAL_ 1088 LHMFRadarSensorDistance 29 " Not used" 28 " Not used" ;
VAL_ 1088 RHMFRadarSensorDistance 29 " Not used" 28 " Not used" ;
VAL_ 1088 RHFRadarSensorDistance 29 " Not used" 28 " Not used" ;
VAL_ 1088 LHFRadarSensorDistance 29 " Not used" 28 " Not used" ;
VAL_ 1088 RHRRadarSensorDistance 61 " Not used" 60 " Not used" 59 " Not used" 58 " Not used" 57 " Not used" 56 " Not used" 55 " Not used" 54 " Not used" 53 " Not used" 52 " Not used" 51 " Not used" 50 " Not used" 49 " Not used" 48 " Not used" 47 " Not used" 46 " Not used" 45 " Not used" 44 " Not used" 43 " Not used" 42 " Not used" 41 " Not used" 40 " Not used" 39 " Not used" 38 " Not used" 37 " Not used" 36 " Not used" 35 " Not used" 34 " Not used" 33 " Not used" 32 " Not used" ;
VAL_ 1088 LHMRRadarSensorDistance 61 " Not used" 60 " Not used" 59 " Not used" 58 " Not used" 57 " Not used" 56 " Not used" 55 " Not used" 54 " Not used" 53 " Not used" 52 " Not used" 51 " Not used" 50 " Not used" 49 " Not used" 48 " Not used" 47 " Not used" 46 " Not used" 45 " Not used" 44 " Not used" 43 " Not used" 42 " Not used" 41 " Not used" 40 " Not used" 39 " Not used" 38 " Not used" 37 " Not used" 36 " Not used" 35 " Not used" 34 " Not used" 33 " Not used" 32 " Not used" ;
VAL_ 1088 RHMRRadarSensorDistance 61 " Not used" 60 " Not used" 59 " Not used" 58 " Not used" 57 " Not used" 56 " Not used" 55 " Not used" 54 " Not used" 53 " Not used" 52 " Not used" 51 " Not used" 50 " Not used" 49 " Not used" 48 " Not used" 47 " Not used" 46 " Not used" 45 " Not used" 44 " Not used" 43 " Not used" 42 " Not used" 41 " Not used" 40 " Not used" 39 " Not used" 38 " Not used" 37 " Not used" 36 " Not used" 35 " Not used" 34 " Not used" 33 " Not used" 32 " Not used" ;
VAL_ 1088 LHRRadarSensorDistance 61 " Not used" 60 " Not used" 59 " Not used" 58 " Not used" 57 " Not used" 56 " Not used" 55 " Not used" 54 " Not used" 53 " Not used" 52 " Not used" 51 " Not used" 50 " Not used" 49 " Not used" 48 " Not used" 47 " Not used" 46 " Not used" 45 " Not used" 44 " Not used" 43 " Not used" 42 " Not used" 41 " Not used" 40 " Not used" 39 " Not used" 38 " Not used" 37 " Not used" 36 " Not used" 35 " Not used" 34 " Not used" 33 " Not used" 32 " Not used" ;
VAL_ 1078 PLG_OperateSts 7 " Not used" 6 " Not used" 5 " Not used" 4 " Closing" 3 " Opening" 2 " Close" 1 " Open" 0 " Stop" ;
VAL_ 1042 PEPS_BLTKey_PESts 1 " ON" 0 " OFF                    " ;
VAL_ 1042 WelcomLightPollingSts 1 " Open" 0 " Close                       " ;
VAL_ 1042 PEPS_IntelligentOpenSts 1 " Open" 0 " Close                          " ;
VAL_ 1042 PEPSPollingSts 1 " Open" 0 " Close                           " ;
VAL_ 998 RemoteStartSts 2 " Remote start mode" 1 " Normal start mode" 0 " No start" ;
VAL_ 998 Start_StopRequest 6 " Reserved" 5 " Reserved" 4 " Remote stop request" 3 " Remote start request" 2 " Normal stop request" 1 " Normar start request" 0 " Not request" ;
VAL_ 998 IDInformation 7 " Transmitter BLT3" 6 " Transmitter BLT2" 5 " Transmitter BLT1" 4 " Transmitter 4" 3 " Transmitter 3" 2 " Transmitter 2" 1 " Transmitter 1" ;
VAL_ 1124 NFC_1_DispCardPosn 1 " active" 0 " not active" ;
VAL_ 1124 NFC_1_IDList 7 " NFC1&NFC2&NFC3" 6 " NFC2&NFC3    " 5 " NFC1&NFC3    " 4 " NFC1&NFC2    " 3 " NFC3" 2 " NFC2" 1 " NFC1" 0 "Not active" ;
VAL_ 1124 NFC_1_ID 3 "Transmitter NFC3 " 2 " Transmitter NFC2" 1 " Transmitter NFC1" 0 " No NFC" ;
VAL_ 864 MFS_ICM_Right 3 " invalid" 2 " Stuck" 1 " Pressed" 0 " Not action" ;
VAL_ 864 MFS_ICM_Left 3 " invalid" 2 " Stuck" 1 " Pressed" 0 " Not action" ;
VAL_ 864 MFS_ICM_Down 3 " invalid" 2 " Stuck" 1 " Pressed" 0 " Not action" ;
VAL_ 864 MFS_ICM_UP 3 " invalid" 2 " Stuck" 1 " Pressed" 0 " Not action" ;
VAL_ 864 MFS_Menu 3 " invalid" 2 " Stuck" 1 " Pressed" 0 " Not action" ;
VAL_ 945 MFS_Customize 3 " invalid" 2 "Stuck" 1 "Pressed" 0 " Not action" ;
VAL_ 945 MFS_WeChat 3 " invalid" 2 "Stuck" 1 "Pressed" 0 " Not action" ;
VAL_ 945 MFS_TJA_ICA_ON_OFF 3 " invalid" 2 " Stuck" 1 " Pressed" 0 " Not action" ;
VAL_ 945 MFS_Start_Pause 3 " invalid" 2 "Stuck" 1 "Pressed" 0 " Not action" ;
VAL_ 945 MFS_Mute 3 " invalid" 2 " Stuck" 1 " Pressed" 0 " Not action" ;
VAL_ 945 MFS_VoiceRecognition 3 " invalid" 2 " Stuck" 1 " Pressed" 0 " Not action" ;
VAL_ 945 MFS_PhoneHangUP 3 " invalid" 2 " Stuck" 1 " Pressed" 0 " Not action" ;
VAL_ 945 MFS_PhonePickUP 3 " invalid" 2 " Stuck" 1 " Pressed" 0 " Not action" ;
VAL_ 945 MFS_SeekDown 3 " invalid" 2 " Stuck" 1 " Pressed" 0 " Not action" ;
VAL_ 945 MFS_SeekUp 3 " invalid" 2 " Stuck" 1 " Pressed" 0 " Not action" ;
VAL_ 945 MFS_VolumeDown 3 " invalid" 2 " Stuck" 1 " Pressed" 0 " Not action" ;
VAL_ 945 MFS_VolumeUp 3 " invalid" 2 " Stuck" 1 " Pressed" 0 " Not action" ;
VAL_ 945 MFS_Mode 3 " invalid" 2 " Stuck" 1 " Pressed" 0 " Not action" ;
VAL_ 1218 LHM_1_ADBenable_Feedback 1 " enable" 0 " disenable" ;
VAL_ 1218 LHM_1_ADBSts 3 " Fault" 2 " Active" 1 " Standby" 0 " ADB Off" ;
VAL_ 1059 LDWSensitivitySettingFeedback 3 " High" 2 " Middle" 1 " Low" 0 " Not Used" ;
VAL_ 1059 LDWSwitchStsFeedback 1 " On" 0 " Off" ;
VAL_ 1175 CST_SensitivitySts 3 " Reserved" 2 " Comfort Level 2" 1 " Comfort Level 1 " 0 " Not Active" ;
VAL_ 1175 BrakepedalFeelSts 3 " Reserved" 2 " Reserved" 1 " Sport" 0 " Comfort" ;
VAL_ 1175 CST_Status 3 " CST is Failure" 2 " CST is Active" 1 " CST is Standby" 0 " CST is disabled" ;
VAL_ 1175 IPB_AssociWithDriverModeSts 1 "  ON" 0 "  OFF" ;
VAL_ 906 IDCU_12CPMod 15 " Reserved" 13 " Reserved" 12 " Reserved" 11 " Reserved" 10 " Failure mode" 9 " safe stop mode" 8 " NOC lateral override mode" 7 " CP lateral override mode" 6 " NOC Active-Control mode" 5 " NOC Reday mode" 4 " NOC cancel mode" 3 " CP Active-Control mode" 2 " CP Reday mode" 1 " CP cancel mode" 0 " No display mode" ;
VAL_ 906 IDCU_12Rmninfo 79 " Reserved" 78 " Reserved" 77 " Reserved" 76 " Reserved" 75 " Reserved" 74 " Reserved" 73 " Reserved" 72 " Reserved" 71 " Reserved" 70 " Reserved" 69 " Reserved" 68 " Reserved" 67 " Reserved" 66 " Reserved" 65 " Reserved" 64 " Reserved" 63 " Reserved" 62 " Reserved" 61 " Reserved" 60 " Reserved" 59 " Reserved" 58 " Reserved" 57 " Reserved" 56 " Reserved" 55 "Reserved" 54 " Reserved" 53 " Reserved" 52 "Reserved" 51 "Reserved" 50 "Reserved" 49 "Reserved" 48 "Reserved" 47 "DCLC is right condition not meeted to left" 46 "CP is active" 45 "ACC is active" 44 " Confirm to change to turn to right lane" 43 " Confirm to change to turn to left lane" 42 " Longitudinal override info" 41 " ELK is in error mode" 40 " LDP is in error mode" 39 " CP is in error mode" 38 " FCW is switched on" 37 " FCW is switched off " 36 " lateral override info" 35 " NOC is changing to turn to right lane" 34 " NOC is changing to turn to left lane" 33 " NOC is going to change to turn to Right lane" 32 " NOC is going to change to turn to left lane" 31 " NOC is going to entrance ramp" 30 " FCW is in error mode" 29 " ACC is in error mode" 28 " AEB is in error mode " 27 " AEB is switched on" 26 " AEB is switched off" 25 " LDW is in error mode" 24 " BSD is in error mode" 23 " Not take over after long time" 22 " Take over info Level3" 21 " Take over info Level1" 20 " Take over info Level1" 19 " NOC is going to exit soon" 18 " DCLC condition not meeted" 17 " Unable to change lane as vehicle speed limit" 16 " unable to active CP" 15 " CP is cancelled" 14 " Radar Error ADAS not available" 13 " Camera Error ADAS not available" 12 " ACC is stand-wait" 11 " Drive Away Info Active" 10 " FCW is active" 9 " Unable to active FCW" 8 " Radar is in error mode" 7 " Camera is in error mode" 6 " Camera is covered" 5 " Radar is covered" 4 "AEB is active" 3 " unable to active AEB" 2 " unable to active ACC" 1 "ACC is cancelled" 0 "No display" ;
VAL_ 1248 IDCU_11_DrvAssiStylests 3 " self-defined" 2 " Old Driver" 1 " New Driver" 0 " Not active" ;
VAL_ 1248 IDCU_11_DCLCONOFFsts 3 " reserved" 2 " switch on" 1 " switch off" 0 " Not active" ;
VAL_ 533 ICM_8_FrntRadarSwt 1 " Active" 0 " Not Active" ;
VAL_ 533 ICM_ESPSwitchCmd 1 " Active" 0 " Not Active" ;
VAL_ 647 ICM_DVDAudibleAlarmStyle 3 "Not Used" 2 "Cycle" 1 "Once" 0 "Not active" ;
VAL_ 647 ICM_DVDAudibleAlarm 15 "Reserved" 14 "Reserved" 13 "Reserved" 12 "Reserved" 11 "Key Tone" 10 "Door Open" 9 "ODO" 8 "Turn Tock    " 7 "Turn Tick                                                                  " 6 "Seatbelt" 5 "Safty" 4 "Warning" 3 "Info" 2 "FWC" 1 "PDC" 0 "Not active" ;
VAL_ 647 CTP_DriveModeSet 3 " Not Used" 2 " DOWN                                     " 1 " UP " 0 " Not Active                                   " ;
VAL_ 647 ICM_5_AlrmVolCtrl 3 " Not Used" 2 " Down" 1 " UP" 0 " Not active" ;
VAL_ 647 ICM_5_BackLiBriAdjmt 3 " Not Used" 2 " Down" 1 " UP" 0 " Not active" ;
VAL_ 1107 FatigureDrivingWaring 1 " Warning" 0 " Not Warning" ;
VAL_ 1107 ICM_BrightnessLevel 15 " Not Used" 14 " Not Used" 13 " Not Used" 12 " Not Used" 11 " Not Used" 10 " Level 10" 9 " Level 9" 8 " Level 8" 7 " Level 7" 6 " Level 6" 5 " Level 5" 4 " Level 4" 3 " Level 3" 2 " Level 2" 1 " Level 1 " 0 " Not Active" ;
VAL_ 1107 LowFuleWarning 1 " Warning" 0 " Not Warning" ;
VAL_ 1107 FatigureDrivingTime 15 " Reserved" 14 " Reserved" 13 " Reserved" 12 " Reserved" 11 " Reserved" 10 " Reserved" 9 " Reserved" 8 " Reserved" 7 " 4 hours " 6 " 3.5 hours" 5 " 3 hours" 4 " 2.5 hours" 3 " 2 hours" 2 " 1.5 hours" 1 " 1 hour" 0 " Not Active" ;
VAL_ 1106 ICM_2_OverSpeedValue 42 " 170km/h" 41 " 165km/h" 40 " 160km/h" 39 " 155km/h" 38 " 150km/h" 37 " 145km/h" 36 " 140km/h" 35 " 135km/h" 34 " 80 mph" 33 " 75 mph" 32 " 70 mph" 31 " 65 mph" 30 " 60 mph" 29 " 55 mph" 28 " 50 mph" 27 " 45 mph" 26 " 40 mph" 25 " 35 mph" 24 " 30mph" 23 " 25mph" 22 " 20mph" 21 " 130km/h" 20 " 125km/h" 19 " 120km/h" 18 " 115km/h" 17 " 110km/h" 16 " 105km/h" 15 " 100km/h" 14 " 95km/h" 13 " 90km/h" 12 " 85km/h" 11 " 80km/h" 10 " 75km/h" 9 " 70km/h" 8 " 65km/h" 7 " 60km/h" 6 " 55km/h" 5 " 50km/h" 4 " 45km/h" 3 " 40km/h" 2 " 35km/h" 1 " 30km/h" 0 " Not Active" ;
VAL_ 1106 BackLightLevel 15 " Reserved" 14 " Reserved" 13 " Reserved" 12 " Reserved" 11 " Reserved" 10 " Reserved" 9 " Level 10 " 8 " Level 9" 7 " Level 8" 6 " Level 7" 5 " Level 6 " 4 " Level 5" 3 " Level 4" 2 " Level 3" 1 " Level 2" 0 " Level 1" ;
VAL_ 1072 ECOModeSWSts 1 " Active" 0 " Not active" ;
VAL_ 1072 ICM_1_HandBrakeSystemSts 7 " Not Used" 6 " Not Used" 5 " ErrorApplied" 4 " Unknown" 3 " Applying" 2 " Releasing" 1 " Applied" 0 " Released" ;
VAL_ 903 FCM_FRM_6_AEBMode 3 " Failure mode" 2 " Active mode" 1 " On mode" 0 " OFF mode" ;
VAL_ 903 FCM_FRM_6_FCWMode 3 " Failure mode" 2 " Active mode" 1 " On mode" 0 " OFF mode" ;
VAL_ 903 FCM_FRM_6_TakeOverReq 1 " Requst" 0 " No Requst" ;
VAL_ 903 FCM_FRM_6_FCW_preWarning 1 " Warning" 0 " No warning" ;
VAL_ 903 FCM_FRM_6_DistanceWarning 1 " Warning" 0 " No warning" ;
VAL_ 903 FCM_FRM_6_TimeGapSetICM 7 " Reserved" 6 " Reserved" 5 " TauGap_5" 4 " TauGap_4" 3 " TauGap_3" 2 " TauGap_2" 1 " TauGap_1" 0 " No Display" ;
VAL_ 903 FCM_FRM_6_ACCMode 15 " Reserved" 14 " Reserved" 13 " Reserved" 12 " Reserved" 11 " Reserved" 10 " Reserved" 9 " Failure mode" 8 " Reserved" 7 " Override" 6 " Stand-wait" 5 " Stand-active" 4 "Brake-Only mode" 3 " Active-Control mode" 2 " Ready mode" 1 " Passive mode" 0 " Initial Mode" ;
VAL_ 1251 FCM_FRM_5_DAIONOFFSts 3 " Reserved" 2 " OFF" 1 " ON" 0 " Not active" ;
VAL_ 1251 FCM_FRM_5_SCFONOFFSts 3 " Reserved" 2 " OFF" 1 " ON" 0 " Not active" ;
VAL_ 1251 FCM_FRM_5_FCWONOFFSts 3 " Reserved" 2 " OFF" 1 " ON" 0 " Not active" ;
VAL_ 1251 FCM_FRM_5_FCWSnvtySts 3 " far" 2 " near" 1 " standard" 0 " Not active" ;
VAL_ 1251 FCM_FRM_5_AEBONOFFSts 3 " Reserved" 2 " OFF" 1 " ON" 0 " Not active" ;
VAL_ 1020 FCM_10_TJAICAExitTextInfoSts 3 " Reserved" 2 " OFF" 1 " ON" 0 " Not active" ;
VAL_ 1020 FCM_10_LDPTJAELKTakeoverReq 3 " Suppressed" 2 " Take Over Safty" 1 " Take Over Warning" 0 " Not Active" ;
VAL_ 1020 FCM_10_TSINoParkWarn 1 " Active" 0 " Not Active" ;
VAL_ 1020 FCM_10_ELKSysSts 7 " Reserved" 6 " Reserved" 5 " Reserved" 4 " Fault" 3 " Active_startup " 2 " Active_standby" 1 " Suppressed" 0 " OFF" ;
VAL_ 1020 FCM_10_LDWSysSts 7 " Reserved" 6 " Reserved" 5 " Reserved" 4 " Fault" 3 " Active_startup " 2 " Active_standby" 1 " Suppressed" 0 " OFF" ;
VAL_ 1020 FCM_10_LDPSysSts 7 " Reserved" 6 " Reserved" 5 " Reserved" 4 " Fault" 3 " Active_startup " 2 " Active_standby" 1 " Suppressed" 0 " OFF" ;
VAL_ 1020 FCM_10_TLITrfcLi 3 " Red" 2 " Yellow" 1 " Green" 0 " No Display" ;
VAL_ 1020 FCM_10_TSISgnLongStayDisp 15 " Reserved" 14 " Reserved" 13 " Reserved" 12 " Reserved" 11 " Reserved" 10 " Reserved" 9 " Reserved" 8 " Malaysia no overtaking" 7 " Australian No parking" 6 " Australian prohibiting standing and parking" 5 " Australian no overtaking" 4 " Prohibiting Standing And Parking" 3 " No Parking" 2 " End Of No Overtaking" 1 " No Overtaking" 0 " No Display" ;
VAL_ 1020 FCM_10_TLISysSts 3 " Fault" 2 " Active" 1 " Standby" 0 " OFF" ;
VAL_ 1020 FCM_10_TSISysSts 3 " Reserved" 2 " Fault" 1 " On" 0 " OFF" ;
VAL_ 1245 FCM_5_ELKONOFFSts 3 " Reserved" 2 " OFF" 1 " ON" 0 " Not active" ;
VAL_ 1245 FCM_5_LDWLDPSnvtySts 3 " Reserved" 2 " HighSensitivity" 1 " LowSensitivity" 0 " Not active" ;
VAL_ 1245 FCM_5_LDPONOFFSts 3 " Reserved" 2 " OFF" 1 " ON" 0 " Not active" ;
VAL_ 1245 FCM_5_WarnModSts 3 " voice and shock" 2 " only shock " 1 " only voice" 0 " Not active" ;
VAL_ 1245 FCM_5_LDWONOFFSts 3 " Reserved" 2 " OFF" 1 " ON" 0 " Not active" ;
VAL_ 1245 FCM_5_TLIONOFFSts 3 " Reserved" 2 " OFF" 1 " ON" 0 " Not active" ;
VAL_ 1245 FCM_5_TSIONOFFSts 3 " Reserved" 2 " OFF" 1 " ON" 0 " Not active" ;
VAL_ 1245 FCM_5_HMAONOFFSts 3 " Reserved" 2 " OFF" 1 " ON" 0 " Not active" ;
VAL_ 1245 FCM_5_IESONOFFSts 3 " Reserved" 2 " OFF" 1 " ON" 0 " Not active" ;
VAL_ 1245 FCM_5_SLAONOFFSts 3 " Reserved" 2 " OFF" 1 " ON" 0 " Not active" ;
VAL_ 1245 FCM_5_TJAICAExitTextInfoSts 3 " Reserved" 2 " OFF" 1 " ON" 0 " Not active" ;
VAL_ 775 FCM_2_SLASpdlimitUnits 3 " Reserved" 2 " MPH" 1 " KMH" 0 " Unknown" ;
VAL_ 775 TJA_ICA_mode 7 " Reserved" 6 " Reserved" 5 " Reserved" 4 " Reserved" 3 " Failure mode" 2 " Active mode" 1 " Standby mode" 0 " OFF mode" ;
VAL_ 775 Camera_textinfo 3 " Reserved" 2 " Camera blocked" 1 " Camera failure" 0 " Camera normal" ;
VAL_ 775 SLASpdlimitWarning 1 " Active" 0 " Not Active" ;
VAL_ 775 SLASpdlimit 255 " Reserved" 254 " Reserved" 253 " Reserved" 252 " Reserved" 251 " Reserved" 250 " Reserved" 249 " Reserved" 248 " Reserved" 247 " Reserved" 246 " Reserved" 245 " Reserved" 244 " Reserved" 243 " Reserved" 242 " Reserved" 241 " Reserved" 240 " Reserved" 239 " Reserved" 238 " Reserved" 237 " Reserved" 236 " Reserved" 235 " Reserved" 234 " Reserved" 233 " Reserved" 232 " Reserved" 231 " Reserved" 230 " Reserved" 229 " Reserved" 228 " Reserved" 227 " Reserved" 226 " Reserved" 225 " Reserved" 224 " Reserved" 223 " Reserved" 222 " Reserved" 221 " Reserved" 220 " Reserved" 219 " Reserved" 218 " Reserved" 217 " Reserved" 216 " Reserved" 215 " Reserved" 214 " Reserved" 213 " Reserved" 212 " Reserved" 211 " Reserved" 210 " Reserved" 209 " Reserved" 208 " Reserved" 207 " Reserved" 206 " Reserved" 205 " Reserved" 204 " Reserved" 203 " Reserved" 202 " Reserved" 201 " Reserved" 200 " Reserved" 199 " Reserved" 198 " Reserved" 197 " Reserved" 196 " Reserved" 195 " Reserved" 194 " Reserved" 193 " Reserved" 192 " Reserved" 191 " Reserved" 190 " Reserved" 189 " Reserved" 188 " Reserved" 187 " Reserved" 186 " Reserved" 185 " Reserved" 184 " Reserved" 183 " Reserved" 182 " Reserved" 181 " Reserved" 180 " Reserved" 179 " Reserved" 178 " Reserved" 177 " Reserved" 176 " Reserved" 175 " Reserved" 174 " Reserved" 173 " Reserved" 172 " Reserved" 171 " Reserved" 170 " Reserved" 169 " Reserved" 168 " Reserved" 167 " Reserved" 166 " Reserved" 165 " Reserved" 164 " Reserved" 163 " Reserved" 162 " Reserved" 161 " Reserved" 160 " Reserved" 159 " Reserved" 158 " Reserved" 157 " Reserved" 156 " Reserved" 155 " Reserved" 154 " Reserved" 153 " Reserved" 152 " Reserved" 151 " Reserved" 150 " Reserved" 149 " Reserved" 148 " Reserved" 147 " Reserved" 146 " Reserved" 145 " Reserved" 144 " Reserved" 143 " Reserved" 142 " Reserved" 141 " Reserved" 140 " Reserved" 139 " Reserved" 138 " Reserved" 137 " Reserved" 136 " Reserved" 135 " Reserved" 134 " Reserved" 133 " Reserved" 132 " Reserved" 131 " Reserved" 130 " Reserved" 129 " Reserved" 128 " Reserved" 127 " Reserved" 126 " Reserved" 125 " Reserved" 124 " Reserved" 123 " Reserved" 122 " Reserved" 121 " Reserved" 120 " Reserved" 119 " Reserved" 118 " Reserved" 117 " Reserved" 116 " Reserved" 115 " Reserved" 114 " Reserved" 113 " Reserved" 112 " Reserved" 111 " Reserved" 110 " Reserved" 109 " Reserved" 108 " Reserved" 107 " Reserved" 106 " Reserved" 105 " Reserved" 104 " Reserved" 103 " Reserved" 102 " Reserved" 101 " Reserved" 100 " Reserved" 99 " Reserved" 98 " Reserved" 97 " Reserved" 96 " Reserved" 95 " Reserved" 94 " Reserved" 93 " Reserved" 92 " Reserved" 91 " Reserved" 90 " Reserved" 89 " Reserved" 88 " Reserved" 87 " Reserved" 86 " Reserved" 85 " Reserved" 84 " Reserved" 83 " Reserved" 82 " Reserved" 81 " Reserved" 80 " Reserved" 79 " Reserved" 78 " Reserved" 77 " Reserved" 76 " Reserved" 75 " Reserved" 74 " Reserved" 73 " Reserved" 72 " Reserved" 71 " Reserved" 70 " Reserved" 69 " Reserved" 68 " Reserved" 67 " Reserved" 66 " Reserved" 65 " Reserved" 64 " Reserved" 63 " Reserved" 62 " Reserved" 61 " Reserved" 60 " Reserved" 59 " Reserved" 58 " Reserved" 57 " Reserved" 56 " Reserved" 55 " Reserved" 54 " Reserved" 53 " Reserved" 52 " Reserved" 51 " Reserved" 50 " Reserved" 49 " Reserved" 48 " Reserved" 47 " Reserved" 46 " Reserved" 45 " Reserved" 44 " Reserved" 43 " Reserved" 42 " Reserved" 41 " Reserved" 40 " Reserved" 39 " Reserved" 38 " Reserved" 37 " Reserved" 36 " Reserved" 35 " Reserved" 34 " Reserved" 33 " Reserved" 32 " Reserved" 31 " Reserved" 30 " Reserved" 29 " Reserved" 28 " Reserved" 27 " SPL 130" 26 " SPL 125" 25 " SPL 120" 24 " SPL 115" 23 " SPL 110" 22 " SPL 105" 21 " SPL 100" 20 " SPL 95" 19 " SPL 90" 18 " SPL 85" 17 " SPL 80" 16 " SPL 75" 15 " SPL 70" 14 " SPL 65" 13 " SPL 60" 12 " SPL 55" 11 " SPL 50" 10 " SPL 45" 9 " SPL 40" 8 " SPL 35" 7 " SPL 30" 6 " SPL 25" 5 " SPL 20" 4 " SPL 15" 3 " SPL10" 2 " SPL 5" 1 " SPL Cancelled" 0 " No Display" ;
VAL_ 775 SLAState 7 " Reserved" 6 " Reserved" 5 " Reserved" 4 " Defect" 3 " Navigation only mode" 2 " Vision mode" 1 " Fusion mode" 0 " Off" ;
VAL_ 775 LDW_ELK_TJA_LDPRightVisuali 3 " Warning" 2 " Intervention" 1 " Line tracking" 0 " No display" ;
VAL_ 775 LDW_ELK_TJA_LDPLeftVisuali 3 " Warning" 2 " Intervention" 1 " Line tracking" 0 " No display" ;
VAL_ 775 HMA_HighbeamReq 1 " High beam request" 0 " No request" ;
VAL_ 775 HMA_Status 7 " Reserved" 6 " Reserved" 5 " Reserved" 4 " Reserved" 3 " Fault" 2 " Active" 1 " Standby" 0 " Off" ;
VAL_ 896 EPS_AssociWithDriverModeSts 1 "ON" 0 "OFF" ;
VAL_ 896 EPS_AssistanceStyle_Sts 3 " Reserved" 2 " Reserved" 1 " Light" 0 " Heavy" ;
VAL_ 1057 BrakePedalSts 0 " Not applied" 1 " Applied" ;
VAL_ 1057 BrakePedalStsValidData 0 " Valid" 1 " Not Valid" ;
VAL_ 1057 GasPedalPositionInvalidData 1 " Invalid" 0 " Valid" ;
VAL_ 640 EngineSts 0 " Not Run" 1 " Run" ;
VAL_ 640 SSMStatus 6 " Auto Stopping" 5 " Operation" 4 " Engine Restart" 3 " Starter Restart" 2 " Stopped" 1 " Standby" 0 " Reset/Not Implemented" ;
VAL_ 1277 CLM_10_SeRowDispSts 1 " Active" 0 " Not active" ;
VAL_ 1277 CLM_10_RfgtLkDispSts 1 " Active" 0 " Not active" ;
VAL_ 1277 CLM_10_ReRowDispSts 1 " Active" 0 " Not active" ;
VAL_ 1277 CLM_10_ReRowBlowSpdLvlSts 7 " Level  7" 6 " Level  6" 5 " Level  5" 4 " Level  4" 3 " Level  3" 2 " Level  2" 1 " Level  1" 0 " Not Active" ;
VAL_ 1277 CLM_10_ReRowWorkSts 1 " Active" 0 " Not active" ;
VAL_ 1277 CLM_10_RmnDispSts 7 " Reserved" 6 " Reserved" 5 " Reserved" 4 " Reserved" 3 " Note3" 2 " Note2" 1 " Note1 " 0 " Not Active" ;
VAL_ 1277 CLM_10_AQSDispSts 1 " Active" 0 " Not active" ;
VAL_ 1277 SelfTestResult2 39 "Right temperature sensor fault" 38 "UV sterilization error (Reserved )" 37 "Fragrance communication error " 36 "Fragrance fan fault " 35 "Fragrance motor error" 34 "Right anion  error " 33 "Left anion  error " 32 "PTC  fault(Reserved)" 25 "Rear Booster error" 24 "External PM2.5  error " 23 "Incar PM2.5  error " 22 "Right mixture motor error" 15 "Left mixture motor error" 14 "Rear Booster Mode motor  error" 13 "Mode motor 1 error" 12 "Circulation motor error" 11 "Blower error" 10 "Left temperature sensor fault  " 9 "Frag motor error" 8 "Evaporator temperature sensor errorevaporator" 7 "AQS sensor error" 6 "Humidity sensor error" 5 "Right solar error" 4 "Left solar error" 3 "Frag Lost Communication With CLM" 2 "Left internal temperature error" 1 "External temperature error" 0 "No error,the system operates well" ;
VAL_ 1277 IntelligentCustomSts 1 " ON" 0 " Off" ;
VAL_ 1277 CLM_10_SeRowWorkSts 1 " Active" 0 " Not Active" ;
VAL_ 1277 CLM_10_SeRowBlowSpdLvlDispSts 7 " Level  7" 6 " Level  6" 5 " Level  5" 4 " Level  4" 3 " Level  3" 2 " Level  2" 1 " Level  1" 0 " Not Active" ;
VAL_ 1277 PtcHeatgSts 1 " ON" 0 " OFF" ;
VAL_ 1334 FragranCeconsistenceLevelSts 7 " Not used" 6 " Not used" 5 " Level5" 4 " Level4" 3 " Level3" 2 " Level2" 1 " Level1" 0 " Not used" ;
VAL_ 1334 Pos3_FragranceTypesSts 7 " Reserved" 6 " Unfilled                           " 5 " Reserved" 4 " Reserved                             " 3 " Type3" 2 " Type2                              " 1 " Type1  " 0 " Not active   " ;
VAL_ 1334 Pos2_FragranceTypesSts 7 " Reserved" 6 " Unfilled                           " 5 " Reserved" 4 " Reserved                             " 3 " Type3" 2 " Type2                              " 1 " Type1  " 0 " Not active   " ;
VAL_ 1334 PM2_5AutoRunSetSts 1 " Off" 0 " On " ;
VAL_ 1334 PM2_5_Incar_Level 7 " Reserved" 6 " Reserved" 5 " Serious pollution" 4 " High levels of pollution" 3 " Moderate pollution" 2 " Light pollution" 1 " Favorable pollution" 0 " Good" ;
VAL_ 1334 PM2_5_Outcar_Level 7 " Reserved" 6 " Reserved" 5 " Serious pollution" 4 " High levels of pollution" 3 " Moderate pollution" 2 " Light pollution" 1 " Favorable pollution" 0 " Good" ;
VAL_ 1334 FragranceDisplaysts 1 " Active" 0 " Not active" ;
VAL_ 1334 FragrancePositionSwt 3 " Position three  active" 2 " Position two  active" 1 " Position one active" 0 " Not active   " ;
VAL_ 1334 ACModeCustomSts 3 " Strong" 2 " Comfortable                                      " 1 " Save" 0 " Not active  " ;
VAL_ 1334 FragranceWelcomeModeSts 1 " Off" 0 " On " ;
VAL_ 1334 RefreshFunctionSts 1 " Off" 0 " On " ;
VAL_ 1334 Pos1_FragranceTypesSts 7 " Reserved" 6 " Unfilled                           " 5 " Reserved" 4 " Reserved                             " 3 " Type3" 2 " Type2                              " 1 " Type1  " 0 " Not active   " ;
VAL_ 1334 PM2_5AutoRunSts 1 " Off" 0 " On " ;
VAL_ 1334 FragranceSWSts 2 " Custom User-Defined" 1 " Off                                                                                                    " 0 " Auto" ;
VAL_ 1334 AutoBltCalllowBlowSpeedSts 1 " Off" 0 " On " ;
VAL_ 1334 AutoParkInnerCirculationSts 1 " Off" 0 " On " ;
VAL_ 1334 PM2_5_IncarSts 1 " failure" 0 " Normal" ;
VAL_ 1334 PM2_5_ExtSts 1 " failure" 0 " Normal" ;
VAL_ 1334 FragranceShortageWarning 7 " Position one and two and three shortage" 6 " Position two and three shortage " 5 " Position one and three shortage " 4 " Position three shortage " 3 " Position one and two shortage                             " 2 " Position two shortage" 1 " Position one shortage" 0 " No Warning" ;
VAL_ 1334 ION_Function_Sts 3 " Not used" 2 " Close " 1 " Open" 0 " No display" ;
VAL_ 1333 AUTODefrostDisplaySts 1 " Active" 0 " Not active" ;
VAL_ 1333 TempKnobRollingCounter 31 " 31(Reserved)" 30 " 30(Reserved)" 29 " 29(Reserved)" 28 " 28(Reserved)" 27 " 27(Reserved)" 26 " 26(Reserved)" 25 " 25(Reserved)" 24 " 24(Reserved)" 23 " 23(Reserved)" 22 " 22(Reserved)" 21 " 21(Reserved)" 20 " 20(Reserved)" 19 " 19(Reserved)" 18 " 18(Reserved)" 17 " 17(Reserved)" 16 " 16" 15 " 15" 14 " 14" 13 " 13" 12 " 12" 11 " 11" 10 " 10" 9 " 9" 8 " 8" 7 " 7" 6 " 6" 5 " 5" 4 " 4" 3 " 3" 2 " 2" 1 " 1" 0 " Not Active" ;
VAL_ 1333 BlowSpeedLevelDisplaySts 15 " Level  15" 14 " Level  14" 13 " Level  13" 12 " Level  12" 11 " Level  11" 10 " Level  10" 9 " Level  9" 8 " Level  8" 7 " Level  7" 6 " Level  6" 5 " Level  5" 4 " Level  4" 3 " Level  3" 2 " Level  2" 1 " Level  1" 0 " Not Active" ;
VAL_ 1333 AUTODefrostForceOpenSts 1 " Active" 0 " Not active" ;
VAL_ 1333 PM2_5Displaysts 1 " Active" 0 " Not active" ;
VAL_ 1333 PM2_5overproofDisplaySts 1 " Active" 0 " Not active" ;
VAL_ 1333 FiltertchangeDisplaySts 1 " Active" 0 " Not active" ;
VAL_ 1333 REARInhibitSts 1 " Inhibitt" 0 " permit" ;
VAL_ 1333 AUTODefrostOnSts 1 " On" 0 " Off" ;
VAL_ 1306 SelfTestResult 30 "Lost Communication With PEPS" 29 "Frag fan error" 28 "Right anion  error  " 27 "Left anion  error " 26 "PTC  fault(Reserved)" 25 "EAC fault(Reserved)" 24 "External PM2.5  error" 23 "Incar PM2.5  error " 22 "Lost Communication With IPM " 21 "Lost Communication With BCM " 20 "Lost Communication With RRM " 19 "Lost Communication With BSM " 18 "Lost Communication With EMS " 17 "Lost Communication With ICM " 16 "Right mixture motor error" 15 "Left mixture motor error" 14 "Mode motor 2 error" 13 "Mode motor 1 error" 12 "Circulation motor error" 11 "Blower error" 10 "AQM fault" 9 "Frag motor error" 8 "Evaporator temperature sensor errorevaporator" 7 "AQS sensor error" 6 "Humidity sensor error" 5 "Right solar error" 4 "Left solar error" 3 "Frag Lost Communication With CLM" 2 "Left internal temperature error" 1 "External temperature error" 0 "No error,the system operates well" ;
VAL_ 1306 TemperatureUnit 1 " Fahrenheit(℉)" 0 " Centigrade(℃)" ;
VAL_ 1306 ZoneSelectionDisplaySts 1 " Dual zone mode" 0 " Single zone mode" ;
VAL_ 1306 CirculationModeDisplaySts 1 " Air circulation mode" 0 " Recirculation mode" ;
VAL_ 1306 BlowDelayOffSts 1 " Not DelayOff" 0 " DelayOff" ;
VAL_ 1306 BlowAdvanceOnSts 1 " Not AdvanceOn" 0 " AdvanceOn" ;
VAL_ 1306 DisplayActive 1 " Active" 0 " Not Active" ;
VAL_ 1306 SelfTestActive 1 " Active" 0 " Not Active" ;
VAL_ 1306 PM2_5Sts 1 " Active" 0 " Not Active" ;
VAL_ 1306 WorkingSts 1 " Active" 0 " Not Active" ;
VAL_ 1306 ModeAdjustDisplaySts 7 "?BlowFace ?&?BlowFoot & Defrost" 6 "?BlowFace & Defrost " 5 "?Not?Active " 4 "?Defrost " 3 "?BlowFoot?&?Defrost " 2 "?BlowFoot " 1 "?BlowFace?&?BlowFoot " 0 "?BlowFace " ;
VAL_ 1306 FrontDeforest_MaxDisplaySts 1 " Active" 0 " Not Active" ;
VAL_ 1306 ACRequestDisplaySts 1 " Active" 0 " Not Active" ;
VAL_ 1306 AutoDisplaySts 1 " Auto Active" 0 " Auto Not Active" ;
VAL_ 1306 Reserved_AC_MaxSts 1 " Active" 0 " Not Active" ;
VAL_ 1306 ExternalTemperatureFailSts 1 " Fail Present" 0 " Fail Not Present" ;
VAL_ 1104 OBDDiagnosisReqInd 1 " Request" 0 " Not Request" ;
VAL_ 1287 BCM_22_WiprSnvtySetFb 7 " Reserved" 6 " Reserved" 5 " Reserved" 4 " Level4" 3 " Level3" 2 " Level2" 1 " Level1" 0 " Not Active" ;
VAL_ 1287 PassSeatMsgStr_LvlSts 3 "High" 2 "Middle" 1 "Low" 0 "OFF" ;
VAL_ 1287 PassSeatMsg_ModeSts 5 "Jump Mode" 4 "Relieve Mode" 3 "Cross Mode" 2 "Cat Paw Mode" 1 "Wave Mode" 0 "Initial" ;
VAL_ 746 BDM_OTAPwrOnReqFb 3 " Resrved" 2 " Fail" 1 " Success" 0 " No Command" ;
VAL_ 746 BDM_OTAPwrDwnReqFb 3 " Resrved" 2 " Fail" 1 " Success" 0 " No Command" ;
VAL_ 746 BDM_OTAModStsFb 1 " Active" 0 " InActive" ;
VAL_ 746 SlaveVehMod 7 "Reserved" 6 "Transport Paused" 5 "Factory Paused " 4 " Crash" 3 " Dyno " 2 " Normal" 1 " Transport" 0 " Factory " ;
VAL_ 746 VehPwrMod 4 " Running" 3 " Crank" 2 " ON " 1 " ACC" 0 " OFF" ;
VAL_ 901 CTP_VolPlusMinusForDVDSts 3 " Not Used" 2 " Plus" 1 " Minus" 0 " Not Active" ;
VAL_ 901 CTP_HomeKeyForIHUSts 3 " Not Used" 2 " Not Used" 1 " Active" 0 " Not active" ;
VAL_ 901 CTP_PowerKeyForIHUSts 3 " Not Used" 2 " Not Used" 1 " Active" 0 " Not active" ;
VAL_ 901 CTP_TrackMod 1 " Active" 0 " Not Active" ;
VAL_ 901 CTP_DriveModeSet 3 " Not Used" 2 " DOWN                                     " 1 " UP " 0 " Not Active                                   " ;
VAL_ 901 CTP_NavKeyForIHUSts 3 " Not Used" 2 " Not Used" 1 " Active" 0 " Not Active" ;
VAL_ 901 CTPKeyVoiceRemindReq 1 " Active" 0 " Not Active" ;
VAL_ 901 IHUSetSwitch 1 " Active" 0 " Not Active" ;
VAL_ 901 AVMSwitch 1 " Active" 0 " Not Active" ;
VAL_ 1063 TheaterDimmingColorFeedback_64 64 " Number 64??Snow??" 63 " Number 63" 62 " Number 62" 61 " Number 61" 60 " Number 60" 59 " Number 59" 58 " Number 58" 57 " Number 57" 56 " Number 56" 55 " Number 55" 54 " Number 54" 53 " Number 53" 52 " Number 52" 51 " Number 51" 50 " Number 50" 49 " Number 49" 48 " Number 48" 47 " Number 47" 46 " Number 46" 45 " Number 45" 44 " Number 44" 43 " Number 43" 42 " Number 42" 41 " Number 41" 40 " Number 40" 39 " Number 39" 38 " Number 38" 37 " Number 37" 36 " Number 36??Mud??" 35 " Number 35" 34 " Number 34" 33 " Number 33" 32 " Number 32" 31 " Number 31" 30 " Number 30" 29 " Number 29" 28 " Number 28" 27 " Number 27" 26 " Number 26" 25 " Number 25" 24 " Number 24" 23 " Number 23" 22 " Number 22" 21 " Number 21" 20 " Number 20" 19 " Number 19??Sand??" 18 " Number 18" 17 " Number 17" 16 " Number 16" 15 " Number 15" 14 " Number 14" 13 " Number 13" 12 " Number 12" 11 " Number 11" 10 " Number 10" 9 " Number 9" 8 " Number 8" 7 " Number 7" 6 " Number 6" 5 " Number 5" 4 " Number 4" 3 " Number 3(Sport)" 2 " Number 2(Normal)" 1 " Number 1(ECO)" 0 " Not Active" ;
VAL_ 1063 Rainfall 3 "Heavy Rain" 2 "Moderate Rain" 1 "Light Rain" 0 "No Rain" ;
VAL_ 1063 HUDBriUnit 3 " 1000 lux" 2 " 100 lux" 1 " 10 lux" 0 " 1 lux" ;
VAL_ 1077 RvsExtMirrFbSts 3 " Both Sides" 2 " Only Left Side" 1 " Only Right Side" 0 " OFF" ;
VAL_ 1077 SRF_Hall2SensorError 1 " Error" 0 " Normal" ;
VAL_ 1077 SRF_Hall1SensorError 1 " Error" 0 " Normal" ;
VAL_ 1077 SRF_SunroofOverVolt 1 " OverVoltage" 0 " Normal" ;
VAL_ 1077 SRF_SunroofUnderVolt 1 " UnderVoltage" 0 " Normal" ;
VAL_ 1077 SRF_LINCommunicationERROR 1 " Error" 0 " Normal" ;
VAL_ 1077 SRF_SwitchError 1 " Error" 0 " Normal" ;
VAL_ 1077 SRF_OverHeatProtect 1 " Active" 0 " Not Active" ;
VAL_ 1077 SRF_MotorRelayError 1 " Error" 0 " Normal" ;
VAL_ 1077 AssociatedWithDriverModeFeedback 1 " ON" 0 " OFF" ;
VAL_ 1077 TheaterDimmingBrightnessFeedback 7 " Reserved" 6 " Reserved" 5 " Reserved" 4 " Level 5" 3 " Level 4" 2 " Level 3" 1 " Level 2" 0 " Level 1                  " ;
VAL_ 1077 TheaterDimmingColorFeedback 7 " Reserved" 6 " Purple" 5 " Blue" 4 " Cyan" 3 " Green" 2 " Yellow" 1 " Orange" 0 " Red                   " ;
VAL_ 1077 SRF_Sunshade_OperateSts 7 " Not Used" 6 " Half Open" 5 " Open" 4 " Closing" 3 " Stop" 2 " Opening" 1 " Close" 0 " Startup" ;
VAL_ 1077 RRWindowSts 7 " Reserved" 6 " Opening" 5 " Closing" 4 " Stop" 3 " Open" 2 " Close" 1 " Comfort" 0 " Startup" ;
VAL_ 1077 RLWindowSts 7 " Reserved" 6 " Opening" 5 " Closing" 4 " Stop" 3 " Open" 2 " Close" 1 " Comfort" 0 " Startup" ;
VAL_ 1077 WindowInhibitSts 1 " Inhibit" 0 " Permit" ;
VAL_ 1077 FRWindow_Sts 7 " Reserved" 6 " Opening" 5 " Closing" 4 " Stop" 3 " Open" 2 " Close" 1 " Comfort" 0 " Startup" ;
VAL_ 1077 FLWindow_Sts 7 " Reserved" 6 " Opening" 5 " Closing" 4 " Stop" 3 " Open" 2 " Close" 1 " Comfort" 0 " Startup" ;
VAL_ 1077 Window_OperateSts 3 " Reserved" 2 " Not active" 1 " Active" 0 " Startup" ;
VAL_ 1077 Reserved_SRF_Error 15 " Reserved" 14 " Reserved" 13 " Reserved" 12 " Reserved" 11 " Reserved" 10 " Reserved" 9 " Reserved" 8 " Hall2 Sensor Error" 7 " Hall1 Sensor Error" 6 " Sunroof Over Volt" 5 " Sunroof under volt" 4 " LIN Communication Error" 3 " Switch Error" 2 " OverHeat Protect" 1 " Motor relay Error" 0 " Start up" ;
VAL_ 1077 SRF_InitStatus 1 " Sunroof Init Complete" 0 " Sunroof Init Incomplete" ;
VAL_ 1077 AssociatedWithMusicModeFeedback 1 " ON" 0 " OFF" ;
VAL_ 1077 TheaterDimmingStatusFeedback 1 " ON" 0 " OFF" ;
VAL_ 1077 SRF_PositionSts 15 " Reserved" 14 " Reserved" 13 " Reserved" 12 " Tilt" 11 " 100%" 10 " 90%" 9 " 80%" 8 " 70%" 7 " 60%" 6 " 50%" 5 " 40%" 4 " 30%" 3 " 20%" 2 " 10%" 1 " 0" 0 " Startup" ;
VAL_ 1077 SRF_OperateSts 7 " Comfort open" 6 " Open" 5 " Closing" 4 " Stop" 3 " Opening" 2 " Close" 1 " Tilt" 0 " Startup" ;
VAL_ 1514 NavigationInformation 1 "Present" 0 "Not Present" ;
VAL_ 1514 SecondIntervalMaintainMileage 3 "10000km" 2 "8000km" 1 "5000km" 0 "Not Present" ;
VAL_ 1514 OverSpeedWarningFunction 3 "120km/h(China,3 beeps)" 2 "120km/h(GSO)" 1 "30~130km/h" 0 "No" ;
VAL_ 1514 Language 19 "Reserved" 18 "Indonesian" 17 "Thai" 16 "Ukrainian" 9 "Turkish" 8 "Italian" 7 "Spanish" 6 "Persian" 5 "Portuguese" 4 "Arabic" 3 "Russian" 1 "English" 0 "Chinese" ;
VAL_ 1514 LDW 1 "Present" 0 "Not Present" ;
VAL_ 1514 EngineFuelType 4 "Flex" 3 "CNG" 1 "Diesel" 0 "Gasoline" ;
VAL_ 1514 Radar_RadaralarmDisplayonICM_ 1 "Not display" 0 "Display" ;
VAL_ 1514 FuelConsumptionCorrect 4 "Configuration 4" 3 "Configuration 3" 1 "Configuration 2" 0 "Configuration 1" ;
VAL_ 1514 MaintainMileage 1 "International(10000km)" 0 "China/International(5000km)" ;
VAL_ 1514 FirstMaintain 1 "International(10000km)" 0 "China/International(5000km)" ;
VAL_ 1514 InitialFuelConsumption 4 "Unit" 3 "Conversion " 2 "Range low" 1 "Range high" 0 "Accuracy" ;
VAL_ 1505 TCU3_CVT25_CVT18 1 " Present" 0 " Not Present" ;
VAL_ 1505 CGW 1 " Present" 0 " Not Present" ;
VAL_ 1505 MFS_LIN 1 " Present" 0 " Not Present" ;
VAL_ 1505 PLG 1 " Present" 0 " Not Present" ;
VAL_ 1505 FRM 1 " Present" 0 " Not Present" ;
VAL_ 1505 FCM 1 " Present" 0 " Not Present" ;
VAL_ 1505 TCU4_7DCT_DHT 1 " Present" 0 " Not Present" ;
VAL_ 1505 EIPM_ONCAN 1 " Present" 0 " Not Present" ;
VAL_ 1505 BSD 1 " Present" 0 " Not Present" ;
VAL_ 1505 EPB 1 " Present" 0 " Not Present" ;
VAL_ 1505 AVM 1 " Present" 0 " Not Present" ;
VAL_ 1505 RADAR 1 " Present" 0 " Not Present" ;
VAL_ 1505 SAS 1 " Present" 0 " Not Present" ;
VAL_ 1505 TPMS 1 " Present" 0 " Not Present" ;
VAL_ 1505 APM 1 " Present" 0 " Not Present" ;
VAL_ 1505 PEPS 1 " Present" 0 " Not Present" ;
VAL_ 1505 EPS 1 " Present" 0 " Not Present" ;
VAL_ 1505 CLM 1 " Present" 0 " Not Present" ;
VAL_ 1505 TCU2_6DCT 1 " Present" 0 " Not Present" ;
VAL_ 1505 TCU1_CVT19 1 " Present" 0 " Not Present" ;
VAL_ 1505 IMMO 3 "BDM integrated IMMO" 2 "PEPS integrated IMMO" 1 "Independent IMMO" 0 "Not Present" ;
VAL_ 1505 ESP 1 " Present" 0 " Not Present" ;
VAL_ 1505 ABS 1 " Present" 0 " Not Present" ;
VAL_ 1505 ABM 1 " Present" 0 " Not Present" ;
VAL_ 1505 ICM 1 " Present" 0 " Not Present" ;
VAL_ 1505 BCM 1 " Present" 0 " Not Present" ;
VAL_ 1505 EMS 1 " Present" 0 " Not Present" ;
VAL_ 1307 TirePosition 3 " RHR" 2 " LHR" 1 " RHF" 0 " LHF" ;
VAL_ 1307 TirePositionWarning_RHRTire 7 " Not used(Reserved)" 6 " Error Mode" 5 " High Temperature" 4 " High Pressure(Reserved)" 2 " Low Pressure" 1 " Rapid Air Loss(Reserved) " 0 " Normal" ;
VAL_ 1307 TirePositionWarning_LHRTire 7 " Not used(Reserved)" 6 " Error Mode" 5 " High Temperature" 4 " High Pressure(Reserved)" 2 " Low Pressure" 1 " Rapid Air Loss(Reserved)" 0 " Normal" ;
VAL_ 1307 TirePositionWarning_RHFTire 7 " Not used(Reserved)" 6 " Error Mode" 5 " High Temperature" 4 " High Pressure(Reserved)" 2 " Low Pressure" 1 " Rapid Air Loss(Reserved)" 0 " Normal" ;
VAL_ 1307 TirePositionWarning_LHFTire 7 " Not used(Reserved)" 6 " Error Mode" 5 " High Temperature" 4 " High Pressure(Reserved)" 2 " Low Pressure" 1 " Rapid Air Loss(Reserved)" 0 " Normal" ;
VAL_ 1307 TirePressureWarningLampSts 3 " Not used" 2 " Lamp On" 1 " Lamp Flashing(Reserved)" 0 " Lamp Off" ;
VAL_ 914 DRLModeSts 1 " Open DRL mode" 0 " Close DRL mode" ;
VAL_ 914 HeadlampDelayLightSts 1 " Delay mode" 0 " Not Delay mode" ;
VAL_ 914 AutolockSts 1 " Autolock mode" 0 " Not autolock mode" ;
VAL_ 914 AutoFoldSts 1 " Autofold mode" 0 " Not autofold mode" ;
VAL_ 914 HeadlampHeightFeedbackSts 7 " Not Used" 6 " Not Used" 5 " Not Used" 4 " Not Used" 3 " Level 3" 2 " Level 2" 1 " Level 1" 0 " Level 0" ;
VAL_ 914 RemoteLockFeedbackSts 3 " Not used" 2 " Only speaker(Reserved)" 1 " Only lamp" 0 " Lamp and speaker" ;
VAL_ 914 BCM_4_ReverseGearSts 1 " Active" 0 " Off" ;
VAL_ 914 BCM_4_RearFogLightSts 1 " Active" 0 " Off" ;
VAL_ 914 BCM_4_DriverDoorLockSts 1 " Unlock" 0 " Lock" ;
VAL_ 914 BCM_4_TrunkSts 1 " Open" 0 " Close" ;
VAL_ 914 BCM_4_LHRdoorSts 1 " Open" 0 " Close" ;
VAL_ 914 BCM_4_RHRDoorSts 1 " Open" 0 " Close" ;
VAL_ 914 BCM_4_HoodSts 1 " Open" 0 " Close" ;
VAL_ 914 BCM_4_PsngrDoorSts 1 " Open" 0 " Close" ;
VAL_ 914 BCM_4_DriverDoorSts 1 " Open" 0 " Close" ;
VAL_ 914 RVSMode 1 " Active" 0 " Not active" ;
VAL_ 914 DirectionIndLeft 1 " Active" 0 " Not active" ;
VAL_ 914 DirectionIndRight 1 " Active" 0 " Not active" ;
VAL_ 914 BCM_4_ParkLightSts 1 " Active" 0 " Off" ;
VAL_ 914 DrvrDoorUnlckOnlySts 1 " Driver Door Unlock Only Mode" 0 " Not Driver Door Unlock Only Mode" ;
VAL_ 914 FGHeat_Req_CmdFeedback 1 " On" 0 " Off" ;
VAL_ 914 BCM_4_KeySts 3 " CRANK + ON" 2 " ON" 1 " ACC" 0 " OFF" ;
VAL_ 914 LightDetected 1 " Bright" 0 " Dark" ;
VAL_ 914 BCM_4_ArmingSts 3 " Invalid" 2 " Disarming successful" 1 " Arming successful" 0 " Not active" ;
VAL_ 913 AutoHighSpeedRequest 1 " True" 0 "False" ;
VAL_ 913 RainDetected 1 " True" 0 "False" ;
VAL_ 913 WiperSts 3 " ContinuousFast" 2 " ContinuousSlow" 1 " Auto or Intermittent" 0 " OFF" ;
VAL_ 913 SteeringWheelheatingSts 1 "Active" 0 "Not Active        " ;
VAL_ 913 RARDfstCmd 1 " Active" 0 " Off" ;
VAL_ 913 HazardLightSW 1 " Active" 0 " Not active" ;
VAL_ 554 APAFailureSts 1 " Failure" 0 " Not Failure" ;
VAL_ 554 APA_Active 1 " Active" 0 " Not active " ;
VAL_ 554 AVM_APA_SystemSts 7 " Invalid" 6 " Terminated" 5 " Failure" 4 " Completed" 3 " Guidance active" 2 " Searching" 1 " Standby" 0 " Off" ;
VAL_ 1267 AIPM_2_DriveModeSet 3 " Not Used" 2 " DOWN" 1 " UP" 0 " Not Active" ;
VAL_ 1265 PanelKeyVoiceRemindReq 1 " Request" 0 " Not active" ;
VAL_ 704 HDCCtrlSts 3 " Not used" 2 " On active braking" 1 " flash not active braking" 0 " OFF" ;
VAL_ 704 VehicleSpeedVSOSigValidData 1 " Not valid" 0 " Valid" ;
VAL_ 704 ESPSwitchStatus 1 " Disable" 0 " On" ;
VAL_ 932 RHRWheelSpeedRawValidData 1 " Not Valid" 0 " Valid" ;
VAL_ 932 RHRWheelDriveDirection 7 " reserved" 6 " reserved" 5 " reserved" 4 " Invalid" 3 " Stop" 2 " Backward" 1 " Forward" 0 " Init" ;
VAL_ 932 LHRWheelSpeedRawValidData 1 " Not Valid" 0 " Valid" ;
VAL_ 932 LHRWheelDriveDirection 7 " reserved" 6 " reserved" 5 " reserved" 4 " Invalid" 3 " Stop" 2 " Backward" 1 " Forward" 0 " Init" ;
VAL_ 931 RHFWheelSpeedRawValidData 1 " Not Valid" 0 " Valid" ;
VAL_ 931 RHFWheelDriveDirection 7 " reserved" 6 " reserved" 5 " reserved" 4 " Invalid" 3 " Stop" 2 " Backward" 1 " Forward" 0 " Init" ;
VAL_ 931 LHFWheelSpeedRawValidData 1 " Not Valid" 0 " Valid" ;
VAL_ 931 LHFWheelDriveDirection 7 " reserved" 6 " reserved" 5 " reserved" 4 " Invalid" 3 " Stop" 2 " Backward" 1 " Forward" 0 " Init" ;
VAL_ 793 RHRPulseCounterFailSts 1 " Fail Present" 0 " Fail Not Present" ;
VAL_ 793 LHFPulseCounterFailSts 1 " Fail Present" 0 " Fail Not Present" ;
VAL_ 793 RHFPulseCounterFailSts 1 " Fail Present" 0 " Fail Not Present" ;
VAL_ 793 LHRPulseCounterFailSts 1 " Fail Present" 0 " Fail Not Present" ;
VAL_ 787 ABS_ESP_3_AVHSts 3 " Not used" 2 " Active" 1 " Standby" 0 " Off" ;
VAL_ 787 ABS_ESP_3_AVHFailSts 1 " Fail present (lamp on)" 0 " Not present" ;
VAL_ 800 ABM_1_PABSetSts 1 "PAB ON" 0 "PAB OFF" ;
VAL_ 1560 ECUSPEC_AWAKE_IHU 1 " Active" 0 " Inactive" ;
VAL_ 1560 DIAGNOSTIC_AWAKE_IHU 1 " Active" 0 " Inactive" ;
VAL_ 1560 IGNITION_AWAKE_IHU 1 " Active" 0 " Inactive" ;
VAL_ 1560 NETWORK_AWAKE_IHU 1 " Active" 0 " Inactive" ;
VAL_ 1560 ECUSPEC_WAKEUP_IHU 1 " Active" 0 " Inactive" ;
VAL_ 1560 NETWORK_WAKEUP_IHU 1 " Active" 0 " Inactive" ;
VAL_ 1560 RESET_WAKEUP_IHU 1 " Active" 0 " Inactive" ;
VAL_ 1560 IGNITION_WAKEUP_IHU 1 " Active" 0 " Inactive" ;
VAL_ 1560 usrData0_IHU 255 " User data not used" 0 " User data for current vehicle" ;
VAL_ 1560 RMR_IHU 1 " Active" 0 " Inactive" ;
VAL_ 1266 TBOX_SetAVMVeiw 7 " Not used" 6 " Not used" 5 " Not used" 4 " 2D right" 3 " 2D left" 2 " 2D Rear" 1 " 2D front" 0 " Not Active       " ;
VAL_ 1266 TBOX_SetAVMOnReq 3 " Not used" 2 " On                                                         " 1 " Off                                                   " 0 " Not Active   " ;
VAL_ 1312 TBOX_1_RemDiagSts 3 "End Read" 2 "Reading" 1 "Start Read" 0 "Not Read" ;
VAL_ 1243 STAT_ADASDisplayPoision 3 "Invalid" 2 "Ignore" 1 "ADAS right" 0 "ADAS left" ;
VAL_ 1243 STAT_NavigationDisplay 1 "Display" 0 "No Display" ;
VAL_ 1243 STAT_ADASDisplay 1 "Display" 0 "No Display" ;
VAL_ 1243 STAT_BluetoothDisplay 1 "Display" 0 "No Display" ;
VAL_ 1243 HUD_1_HUDHiTWarn 3 "Reserved" 2 "Reserved" 1 "warning" 0 "No warning" ;
VAL_ 1243 STAT_FaceIDOnOFF 1 "ON" 0 "OFF" ;
VAL_ 1243 STAT_HUDBrightness 9 "Level10" 8 "Level9" 7 "Level8" 6 "Level7" 5 "Level6" 4 "Level5" 3 "Level4" 2 "Level3" 1 "Level2" 0 "Level1" ;
VAL_ 1243 STAT_HUD 3 " Standby" 2 " Preparing" 1 " Error" 0 " Normal" ;
VAL_ 1243 STAT_HUDProfileID 7 "Ignore" 6 "Reserved" 5 "Reserved" 4 "ID5" 3 "ID4" 2 "ID3" 1 "ID2" 0 "ID1" ;
VAL_ 1243 STAT_HUDDisplayMod 2 "sport" 1 " Snowy" 0 " Normal" ;
VAL_ 1243 STAT_HUDDisplayOnOff 1 " ON" 0 " OFF" ;
VAL_ 1243 STAT_HUDHeight 15 "Reserved" 14 "Reserved" 13 "Reserved" 12 "Reserved" 11 "Reserved" 10 "Reserved" 9 "Level10" 8 "Level9" 7 "Level8" 6 "Level7" 5 "Level6" 4 "Level5" 3 "Level4" 2 "Level3" 1 "Level2" 0 "Level1" ;
VAL_ 1140 STAT_AMPESEVol 63 " Reserved" 62 " Reserved" 61 " Reserved" 60 " Reserved" 59 " Reserved" 58 " Reserved" 57 " Reserved" 56 " Reserved" 55 " Reserved" 54 " Reserved" 53 " Reserved" 52 " Reserved" 51 " Reserved" 50 " Reserved" 49 " Reserved" 48 " Reserved" 41 " Reserved" 40 " Reserved" 39 " Reserved" 38 " Reserved" 37 " Reserved" 36 " Reserved" 35 " Reserved" 34 " Reserved" 33 " Reserved" 32 " 31" 31 " 30" 30 " 29" 29 " 28" 28 " 27" 27 " 26" 26 " 25" 25 " 24" 24 " 23" 23 " 22" 22 " 21" 21 " 20" 20 " 19" 19 " 18" 18 " 17" 17 " 16" 16 " 15" 15 " 14" 14 " 13" 13 " 12" 12 " 11" 11 " 10" 10 " 9" 9 " 8" 8 " 7" 7 " 6" 6 " 5" 5 " 4" 4 " 3" 3 " 2" 2 " 1" 1 " 0 " 0 " Not Active" ;
VAL_ 1140 STAT_AMPWelVol 63 " Reserved" 62 " Reserved" 61 " Reserved" 60 " Reserved" 59 " Reserved" 58 " Reserved" 57 " Reserved" 56 " Reserved" 55 " Reserved" 54 " Reserved" 53 " Reserved" 52 " Reserved" 51 " Reserved" 50 " Reserved" 49 " Reserved" 48 " Reserved" 41 " Reserved" 40 " Reserved" 39 " Reserved" 38 " Reserved" 37 " Reserved" 36 " Reserved" 35 " Reserved" 34 " Reserved" 33 " Reserved" 32 " 31" 31 " 30" 30 " 29" 29 " 28" 28 " 27" 27 " 26" 26 " 25" 25 " 24" 24 " 23" 23 " 22" 22 " 21" 21 " 20" 20 " 19" 19 " 18" 18 " 17" 17 " 16" 16 " 15" 15 " 14" 14 " 13" 13 " 12" 12 " 11" 11 " 10" 10 " 9" 9 " 8" 8 " 7" 7 " 6" 6 " 5" 5 " 4" 4 " 3" 3 " 2" 2 " 1" 1 " 0 " 0 " Not Active" ;
VAL_ 1140 STAT_AMPBTMediVol 63 " Reserved" 62 " Reserved" 61 " Reserved" 60 " Reserved" 59 " Reserved" 58 " Reserved" 57 " Reserved" 56 " Reserved" 55 " Reserved" 54 " Reserved" 53 " Reserved" 52 " Reserved" 51 " Reserved" 50 " Reserved" 49 " Reserved" 48 " Reserved" 41 " Reserved" 40 " Reserved" 39 " Reserved" 38 " Reserved" 37 " Reserved" 36 " Reserved" 35 " Reserved" 34 " Reserved" 33 " Reserved" 32 " 31" 31 " 30" 30 " 29" 29 " 28" 28 " 27" 27 " 26" 26 " 25" 25 " 24" 24 " 23" 23 " 22" 22 " 21" 21 " 20" 20 " 19" 19 " 18" 18 " 17" 17 " 16" 16 " 15" 15 " 14" 14 " 13" 13 " 12" 12 " 11" 11 " 10" 10 " 9" 9 " 8" 8 " 7" 7 " 6" 6 " 5" 5 " 4" 4 " 3" 3 " 2" 2 " 1" 1 " 0 " 0 " Not Active" ;
VAL_ 1140 STAT_AMPTEMP 7 " Reserved" 6 " Reserved" 5 " Reserved" 4 " Reserved" 3 " 3" 2 " 2" 1 " 1" 0 " Not Active" ;
VAL_ 1140 STAT_AMPMute 3 " reserved" 2 " OFF" 1 " ON" 0 " Not Active" ;
VAL_ 1140 STAT_AMPSpeedVolume 7 " Reserved" 6 " Reserved" 5 " Reserved" 4 " High" 3 " Middle" 2 " Low" 1 " OFF" 0 " Not Active" ;
VAL_ 1140 EAMP_2_HdrestSpkrMod 7 "reserved" 6 "reserved " 5 "reserved" 4 "reserved" 3 "Private mode" 2 "Drive mode" 1 "Shared mode" 0 "Not Active" ;
VAL_ 1121 STAT_AMPAlarmVolume 15 " Reserved" 14 " Reserved" 13 " Reserved" 12 " Reserved" 11 " Reserved" 10 " 10" 9 " 9" 8 " 8" 7 " 7" 6 " 6" 5 " 5" 4 " 4" 3 " 3" 2 " 2" 1 " 1" 0 " Not Active" ;
VAL_ 1121 STAT_AMPLoudness 3 " reserved" 2 " OFF" 1 " ON" 0 " Not Active" ;
VAL_ 1121 STAT_AMPLiveAcoustics 3 " reserved" 2 " OFF" 1 " ON" 0 " Not Active" ;
VAL_ 1121 STAT_AMPSoundFieldFader 15 " 7" 14 " 6" 13 " 5" 12 " 4" 11 " 3" 10 " 2" 9 " 1" 8 " 0" 7 " -1" 6 " -2" 5 " -3" 4 " -4" 3 " -5" 2 " -6" 1 " -7" 0 " Not Active" ;
VAL_ 1121 STAT_AMPSoundFieldBalance 15 " 7" 14 " 6" 13 " 5" 12 " 4" 11 " 3" 10 " 2" 9 " 1" 8 " 0" 7 " -1" 6 " -2" 5 " -3" 4 " -4" 3 " -5" 2 " -6" 1 " -7" 0 " Not Active" ;
VAL_ 1121 STAT_AMPSoundEffectTreble 15 " 7" 14 " 6" 13 " 5" 12 " 4" 11 " 3" 10 " 2" 9 " 1" 8 " 0" 7 " -1" 6 " -2" 5 " -3" 4 " -4" 3 " -5" 2 " -6" 1 " -7" 0 " Not Active" ;
VAL_ 1121 STAT_AMPSoundEffectMidrange 15 " 7" 14 " 6" 13 " 5" 12 " 4" 11 " 3" 10 " 2" 9 " 1" 8 " 0" 7 " -1" 6 " -2" 5 " -3" 4 " -4" 3 " -5" 2 " -6" 1 " -7" 0 " Not Active" ;
VAL_ 1121 STAT_AMPSoundEffectBass 15 " 7" 14 " 6" 13 " 5" 12 " 4" 11 " 3" 10 " 2" 9 " 1" 8 " 0" 7 " -1" 6 " -2" 5 " -3" 4 " -4" 3 " -5" 2 " -6" 1 " -7" 0 " Not Active" ;
VAL_ 1121 STAT_AMPSoundEffect 15 " Reserved" 14 " Reserved" 13 " Reserved" 12 " Reserved" 11 " Reserved" 10 " Reserved" 9 "  Reserved" 8 " Rural model" 7 " Vocals mode" 6 " Rock mode" 5 " Classic mode" 4 " Jazz mode" 3 " Popular mode" 2 " Standard mode " 1 " Customer-defined mode" 0 " Not Active" ;
VAL_ 1121 STAT_AMPRestoreDefaults 3 " Reserved" 2 " OFF" 1 " ON" 0 " Not Active" ;
VAL_ 1121 STAT_AMPDefaultVolume 63 " Reserved" 62 " Reserved" 61 " Reserved" 60 " Reserved" 59 " Reserved" 58 " Reserved" 57 " Reserved" 56 " Reserved" 55 " Reserved" 54 " Reserved" 53 " Reserved" 52 " Reserved" 51 " Reserved" 50 " Reserved" 49 " Reserved" 48 " Reserved" 41 " Reserved" 40 " Reserved" 39 " Reserved" 38 " Reserved" 37 " Reserved" 36 " Reserved" 35 " Reserved" 34 " Reserved" 33 " Reserved" 32 " 31" 31 " 30" 30 " 29" 29 " 28" 28 " 27" 27 " 26" 26 " 25" 25 " 24" 24 " 23" 23 " 22" 22 " 21" 21 " 20" 20 " 19" 19 " 18" 18 " 17" 17 " 16" 16 " 15" 15 " 14" 14 " 13" 13 " 12" 12 " 11" 11 " 10" 10 " 9" 9 " 8" 8 " 7" 7 " 6" 6 " 5" 5 " 4" 4 " 3" 3 " 2" 2 " 1" 1 " 0 " 0 " Not Active" ;
VAL_ 1121 STAT_AMPSoundFocus 0 " Not Active" ;
VAL_ 1121 STAT_AMPPhoneVolume 31 " Reserved" 30 " Reserved" 29 " Reserved" 28 " Reserved" 27 " Reserved" 26 " 25" 25 " 24" 24 " 23" 23 " 22" 22 " 21" 21 " 20" 20 " 19" 19 " 18" 18 " 17" 17 " 16" 16 " 15" 15 " 14" 14 " 13" 13 " 12" 12 " 11" 11 " 10" 10 " 9" 9 " 8" 8 " 7" 7 " 6" 6 " 5" 5 " 4" 4 " 3" 3 " 2" 2 " 1" 1 " 0 " 0 " Not Active" ;
VAL_ 1121 STAT_AMPMediaVolume 63 " Reserved" 62 " Reserved" 61 " Reserved" 60 " Reserved" 59 " Reserved" 58 " Reserved" 57 " Reserved" 56 " Reserved" 55 " Reserved" 54 " Reserved" 53 " Reserved" 52 " Reserved" 51 " Reserved" 50 " Reserved" 49 " Reserved" 48 " Reserved" 41 " Reserved" 40 " Reserved" 39 " Reserved" 38 " Reserved" 37 " Reserved" 36 " Reserved" 35 " Reserved" 34 " Reserved" 33 " Reserved" 32 " 31" 31 " 30" 30 " 29" 29 " 28" 28 " 27" 27 " 26" 26 " 25" 25 " 24" 24 " 23" 23 " 22" 22 " 21" 21 " 20" 20 " 19" 19 " 18" 18 " 17" 17 " 16" 16 " 15" 15 " 14" 14 " 13" 13 " 12" 12 " 11" 11 " 10" 10 " 9" 9 " 8" 8 " 7" 7 " 6" 6 " 5" 5 " 4" 4 " 3" 3 " 2" 2 " 1" 1 " 0 " 0 " Not Active" ;
VAL_ 1121 STAT_AMPKeyTone 3 " reserved" 2 " OFF" 1 " ON" 0 " Not Active" ;
VAL_ 1121 STAT_AMPVRVolume 15 " Reserved" 14 " Reserved" 13 " Reserved" 12 " Reserved" 11 " 10" 10 " 9" 9 " 8" 8 " 7" 7 " 6" 6 " 5" 5 " 4" 4 " 3" 3 " 2" 2 " 1" 1 " 0 " 0 " Not Active" ;
VAL_ 1121 STAT_AMPNaviVolume 15 " Reserved" 14 " Reserved" 13 " Reserved" 12 " Reserved" 11 " 10" 10 " 9" 9 " 8" 8 " 7" 7 " 6" 6 " 5" 5 " 4" 4 " 3" 3 " 2" 2 " 1" 1 " 0 " 0 " Not Active" ;
